VERSION "created by canmatrix"

NS_ :

BS_:

BU_:

BO_ 2358902526 JLCM: 8 Vector__XXX
 SG_ Joystick3Lamp10Cmd : 58|2@1+ (1,0) [0|3] "" Vector__XXX
 SG_ Joystick3Lamp9Cmd : 56|2@1+ (1,0) [0|3] "" Vector__XXX
 SG_ Joystick3Lamp8Cmd : 54|2@1+ (1,0) [0|3] "" Vector__XXX
 SG_ Joystick3Lamp7Cmd : 52|2@1+ (1,0) [0|3] "" Vector__XXX
 SG_ Joystick3Lamp6Cmd : 50|2@1+ (1,0) [0|3] "" Vector__XXX
 SG_ Joystick3Lamp5Cmd : 48|2@1+ (1,0) [0|3] "" Vector__XXX
 SG_ Joystick3Lamp4Cmd : 46|2@1+ (1,0) [0|3] "" Vector__XXX
 SG_ Joystick3Lamp3Cmd : 44|2@1+ (1,0) [0|3] "" Vector__XXX
 SG_ Joystick3Lamp2Cmd : 42|2@1+ (1,0) [0|3] "" Vector__XXX
 SG_ Joystick3Lamp1Cmd : 40|2@1+ (1,0) [0|3] "" Vector__XXX
 SG_ Joystick2Lamp10Cmd : 38|2@1+ (1,0) [0|3] "" Vector__XXX
 SG_ Joystick2Lamp9Cmd : 36|2@1+ (1,0) [0|3] "" Vector__XXX
 SG_ Joystick2Lamp8Cmd : 34|2@1+ (1,0) [0|3] "" Vector__XXX
 SG_ Joystick2Lamp7Cmd : 32|2@1+ (1,0) [0|3] "" Vector__XXX
 SG_ Joystick2Lamp6Cmd : 30|2@1+ (1,0) [0|3] "" Vector__XXX
 SG_ Joystick2Lamp5Cmd : 28|2@1+ (1,0) [0|3] "" Vector__XXX
 SG_ Joystick2Lamp4Cmd : 26|2@1+ (1,0) [0|3] "" Vector__XXX
 SG_ Joystick2Lamp3Cmd : 24|2@1+ (1,0) [0|3] "" Vector__XXX
 SG_ Joystick2Lamp2Cmd : 22|2@1+ (1,0) [0|3] "" Vector__XXX
 SG_ Joystick2Lamp1Cmd : 20|2@1+ (1,0) [0|3] "" Vector__XXX
 SG_ Joystick1Lamp10Cmd : 18|2@1+ (1,0) [0|3] "" Vector__XXX
 SG_ Joystick1Lamp9Cmd : 16|2@1+ (1,0) [0|3] "" Vector__XXX
 SG_ Joystick1Lamp8Cmd : 14|2@1+ (1,0) [0|3] "" Vector__XXX
 SG_ Joystick1Lamp7Cmd : 12|2@1+ (1,0) [0|3] "" Vector__XXX
 SG_ Joystick1Lamp6Cmd : 10|2@1+ (1,0) [0|3] "" Vector__XXX
 SG_ Joystick1Lamp5Cmd : 8|2@1+ (1,0) [0|3] "" Vector__XXX
 SG_ Joystick1Lamp4Cmd : 6|2@1+ (1,0) [0|3] "" Vector__XXX
 SG_ Joystick1Lamp3Cmd : 4|2@1+ (1,0) [0|3] "" Vector__XXX
 SG_ Joystick1Lamp2Cmd : 2|2@1+ (1,0) [0|3] "" Vector__XXX
 SG_ Joystick1Lamp1Cmd : 0|2@1+ (1,0) [0|3] "" Vector__XXX

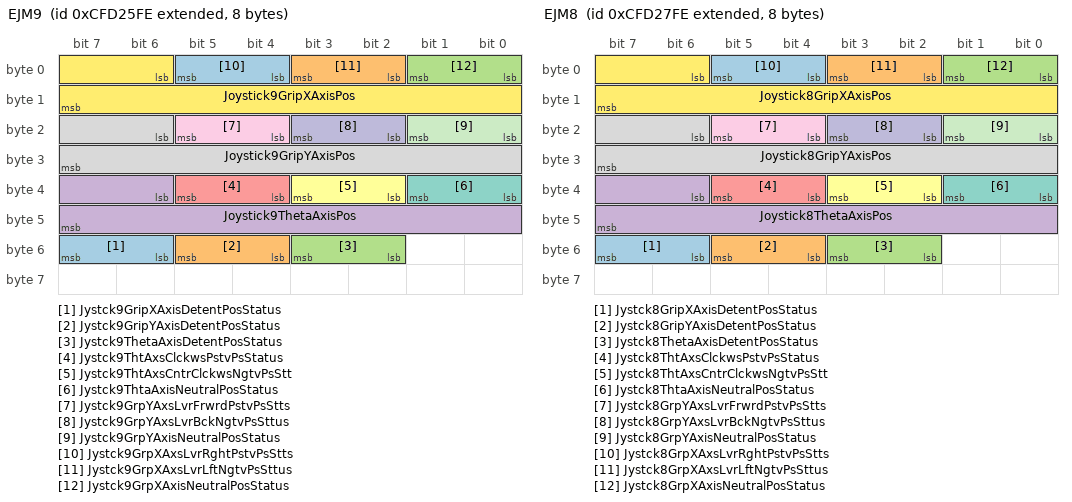
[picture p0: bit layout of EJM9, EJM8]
BO_ 2365400574 EJM9: 8 Vector__XXX
 SG_ Jystck9GripXAxisDetentPosStatus : 54|2@1+ (1,0) [0|3] "" Vector__XXX
 SG_ Jystck9GripYAxisDetentPosStatus : 52|2@1+ (1,0) [0|3] "" Vector__XXX
 SG_ Jystck9ThetaAxisDetentPosStatus : 50|2@1+ (1,0) [0|3] "" Vector__XXX
 SG_ Joystick9ThetaAxisPos : 38|10@1+ (0.1,0) [0|102] "%" Vector__XXX
 SG_ Jystck9ThtAxsClckwsPstvPsStatus : 36|2@1+ (1,0) [0|3] "" Vector__XXX
 SG_ Jystck9ThtAxsCntrClckwsNgtvPsStt : 34|2@1+ (1,0) [0|3] "" Vector__XXX
 SG_ Jystck9ThtaAxisNeutralPosStatus : 32|2@1+ (1,0) [0|3] "" Vector__XXX
 SG_ Joystick9GripYAxisPos : 22|10@1+ (0.1,0) [0|102] "%" Vector__XXX
 SG_ Jystck9GrpYAxsLvrFrwrdPstvPsStts : 20|2@1+ (1,0) [0|3] "" Vector__XXX
 SG_ Jystck9GrpYAxsLvrBckNgtvPsSttus : 18|2@1+ (1,0) [0|3] "" Vector__XXX
 SG_ Jystck9GrpYAxisNeutralPosStatus : 16|2@1+ (1,0) [0|3] "" Vector__XXX
 SG_ Joystick9GripXAxisPos : 6|10@1+ (0.1,0) [0|102] "%" Vector__XXX
 SG_ Jystck9GrpXAxsLvrRghtPstvPsStts : 4|2@1+ (1,0) [0|3] "" Vector__XXX
 SG_ Jystck9GrpXAxsLvrLftNgtvPsSttus : 2|2@1+ (1,0) [0|3] "" Vector__XXX
 SG_ Jystck9GrpXAxisNeutralPosStatus : 0|2@1+ (1,0) [0|3] "" Vector__XXX

BO_ 2365401086 EJM8: 8 Vector__XXX
 SG_ Jystck8GripXAxisDetentPosStatus : 54|2@1+ (1,0) [0|3] "" Vector__XXX
 SG_ Jystck8GripYAxisDetentPosStatus : 52|2@1+ (1,0) [0|3] "" Vector__XXX
 SG_ Jystck8ThetaAxisDetentPosStatus : 50|2@1+ (1,0) [0|3] "" Vector__XXX
 SG_ Joystick8ThetaAxisPos : 38|10@1+ (0.1,0) [0|102] "%" Vector__XXX
 SG_ Jystck8ThtAxsClckwsPstvPsStatus : 36|2@1+ (1,0) [0|3] "" Vector__XXX
 SG_ Jystck8ThtAxsCntrClckwsNgtvPsStt : 34|2@1+ (1,0) [0|3] "" Vector__XXX
 SG_ Jystck8ThtaAxisNeutralPosStatus : 32|2@1+ (1,0) [0|3] "" Vector__XXX
 SG_ Joystick8GripYAxisPos : 22|10@1+ (0.1,0) [0|102] "%" Vector__XXX
 SG_ Jystck8GrpYAxsLvrFrwrdPstvPsStts : 20|2@1+ (1,0) [0|3] "" Vector__XXX
 SG_ Jystck8GrpYAxsLvrBckNgtvPsSttus : 18|2@1+ (1,0) [0|3] "" Vector__XXX
 SG_ Jystck8GrpYAxisNeutralPosStatus : 16|2@1+ (1,0) [0|3] "" Vector__XXX
 SG_ Joystick8GripXAxisPos : 6|10@1+ (0.1,0) [0|102] "%" Vector__XXX
 SG_ Jystck8GrpXAxsLvrRghtPstvPsStts : 4|2@1+ (1,0) [0|3] "" Vector__XXX
 SG_ Jystck8GrpXAxsLvrLftNgtvPsSttus : 2|2@1+ (1,0) [0|3] "" Vector__XXX
 SG_ Jystck8GrpXAxisNeutralPosStatus : 0|2@1+ (1,0) [0|3] "" Vector__XXX

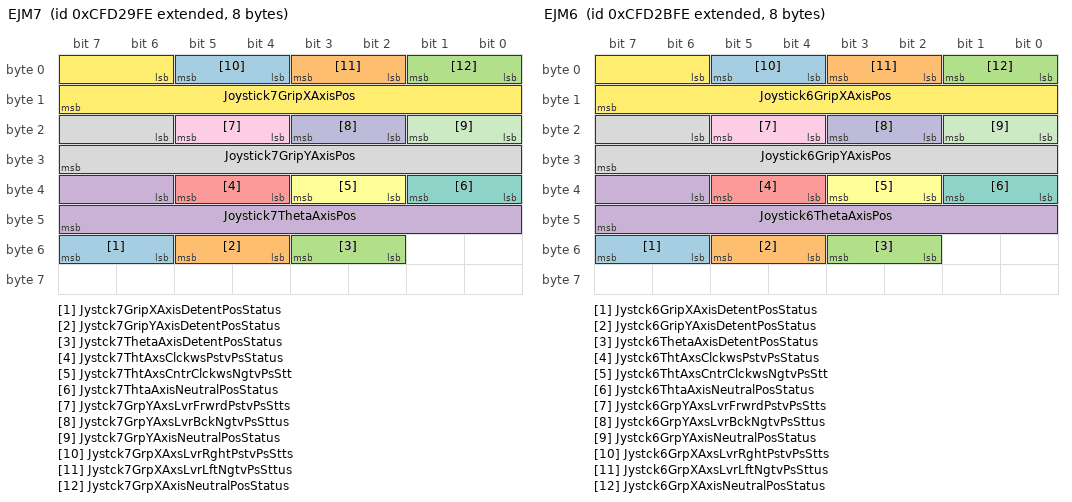
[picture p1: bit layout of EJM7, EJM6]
BO_ 2365401598 EJM7: 8 Vector__XXX
 SG_ Jystck7GripXAxisDetentPosStatus : 54|2@1+ (1,0) [0|3] "" Vector__XXX
 SG_ Jystck7GripYAxisDetentPosStatus : 52|2@1+ (1,0) [0|3] "" Vector__XXX
 SG_ Jystck7ThetaAxisDetentPosStatus : 50|2@1+ (1,0) [0|3] "" Vector__XXX
 SG_ Joystick7ThetaAxisPos : 38|10@1+ (0.1,0) [0|102] "%" Vector__XXX
 SG_ Jystck7ThtAxsClckwsPstvPsStatus : 36|2@1+ (1,0) [0|3] "" Vector__XXX
 SG_ Jystck7ThtAxsCntrClckwsNgtvPsStt : 34|2@1+ (1,0) [0|3] "" Vector__XXX
 SG_ Jystck7ThtaAxisNeutralPosStatus : 32|2@1+ (1,0) [0|3] "" Vector__XXX
 SG_ Joystick7GripYAxisPos : 22|10@1+ (0.1,0) [0|102] "%" Vector__XXX
 SG_ Jystck7GrpYAxsLvrFrwrdPstvPsStts : 20|2@1+ (1,0) [0|3] "" Vector__XXX
 SG_ Jystck7GrpYAxsLvrBckNgtvPsSttus : 18|2@1+ (1,0) [0|3] "" Vector__XXX
 SG_ Jystck7GrpYAxisNeutralPosStatus : 16|2@1+ (1,0) [0|3] "" Vector__XXX
 SG_ Joystick7GripXAxisPos : 6|10@1+ (0.1,0) [0|102] "%" Vector__XXX
 SG_ Jystck7GrpXAxsLvrRghtPstvPsStts : 4|2@1+ (1,0) [0|3] "" Vector__XXX
 SG_ Jystck7GrpXAxsLvrLftNgtvPsSttus : 2|2@1+ (1,0) [0|3] "" Vector__XXX
 SG_ Jystck7GrpXAxisNeutralPosStatus : 0|2@1+ (1,0) [0|3] "" Vector__XXX

BO_ 2365402110 EJM6: 8 Vector__XXX
 SG_ Jystck6GripXAxisDetentPosStatus : 54|2@1+ (1,0) [0|3] "" Vector__XXX
 SG_ Jystck6GripYAxisDetentPosStatus : 52|2@1+ (1,0) [0|3] "" Vector__XXX
 SG_ Jystck6ThetaAxisDetentPosStatus : 50|2@1+ (1,0) [0|3] "" Vector__XXX
 SG_ Joystick6ThetaAxisPos : 38|10@1+ (0.1,0) [0|102] "%" Vector__XXX
 SG_ Jystck6ThtAxsClckwsPstvPsStatus : 36|2@1+ (1,0) [0|3] "" Vector__XXX
 SG_ Jystck6ThtAxsCntrClckwsNgtvPsStt : 34|2@1+ (1,0) [0|3] "" Vector__XXX
 SG_ Jystck6ThtaAxisNeutralPosStatus : 32|2@1+ (1,0) [0|3] "" Vector__XXX
 SG_ Joystick6GripYAxisPos : 22|10@1+ (0.1,0) [0|102] "%" Vector__XXX
 SG_ Jystck6GrpYAxsLvrFrwrdPstvPsStts : 20|2@1+ (1,0) [0|3] "" Vector__XXX
 SG_ Jystck6GrpYAxsLvrBckNgtvPsSttus : 18|2@1+ (1,0) [0|3] "" Vector__XXX
 SG_ Jystck6GrpYAxisNeutralPosStatus : 16|2@1+ (1,0) [0|3] "" Vector__XXX
 SG_ Joystick6GripXAxisPos : 6|10@1+ (0.1,0) [0|102] "%" Vector__XXX
 SG_ Jystck6GrpXAxsLvrRghtPstvPsStts : 4|2@1+ (1,0) [0|3] "" Vector__XXX
 SG_ Jystck6GrpXAxsLvrLftNgtvPsSttus : 2|2@1+ (1,0) [0|3] "" Vector__XXX
 SG_ Jystck6GrpXAxisNeutralPosStatus : 0|2@1+ (1,0) [0|3] "" Vector__XXX

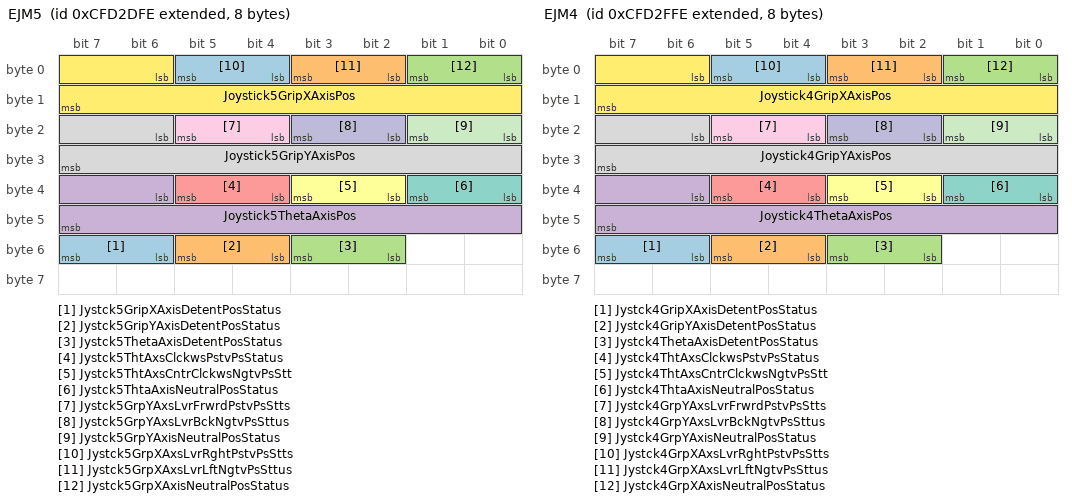
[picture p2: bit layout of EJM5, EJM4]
BO_ 2365402622 EJM5: 8 Vector__XXX
 SG_ Jystck5GripXAxisDetentPosStatus : 54|2@1+ (1,0) [0|3] "" Vector__XXX
 SG_ Jystck5GripYAxisDetentPosStatus : 52|2@1+ (1,0) [0|3] "" Vector__XXX
 SG_ Jystck5ThetaAxisDetentPosStatus : 50|2@1+ (1,0) [0|3] "" Vector__XXX
 SG_ Joystick5ThetaAxisPos : 38|10@1+ (0.1,0) [0|102] "%" Vector__XXX
 SG_ Jystck5ThtAxsClckwsPstvPsStatus : 36|2@1+ (1,0) [0|3] "" Vector__XXX
 SG_ Jystck5ThtAxsCntrClckwsNgtvPsStt : 34|2@1+ (1,0) [0|3] "" Vector__XXX
 SG_ Jystck5ThtaAxisNeutralPosStatus : 32|2@1+ (1,0) [0|3] "" Vector__XXX
 SG_ Joystick5GripYAxisPos : 22|10@1+ (0.1,0) [0|102] "%" Vector__XXX
 SG_ Jystck5GrpYAxsLvrFrwrdPstvPsStts : 20|2@1+ (1,0) [0|3] "" Vector__XXX
 SG_ Jystck5GrpYAxsLvrBckNgtvPsSttus : 18|2@1+ (1,0) [0|3] "" Vector__XXX
 SG_ Jystck5GrpYAxisNeutralPosStatus : 16|2@1+ (1,0) [0|3] "" Vector__XXX
 SG_ Joystick5GripXAxisPos : 6|10@1+ (0.1,0) [0|102] "%" Vector__XXX
 SG_ Jystck5GrpXAxsLvrRghtPstvPsStts : 4|2@1+ (1,0) [0|3] "" Vector__XXX
 SG_ Jystck5GrpXAxsLvrLftNgtvPsSttus : 2|2@1+ (1,0) [0|3] "" Vector__XXX
 SG_ Jystck5GrpXAxisNeutralPosStatus : 0|2@1+ (1,0) [0|3] "" Vector__XXX

BO_ 2365403134 EJM4: 8 Vector__XXX
 SG_ Jystck4GripXAxisDetentPosStatus : 54|2@1+ (1,0) [0|3] "" Vector__XXX
 SG_ Jystck4GripYAxisDetentPosStatus : 52|2@1+ (1,0) [0|3] "" Vector__XXX
 SG_ Jystck4ThetaAxisDetentPosStatus : 50|2@1+ (1,0) [0|3] "" Vector__XXX
 SG_ Joystick4ThetaAxisPos : 38|10@1+ (0.1,0) [0|102] "%" Vector__XXX
 SG_ Jystck4ThtAxsClckwsPstvPsStatus : 36|2@1+ (1,0) [0|3] "" Vector__XXX
 SG_ Jystck4ThtAxsCntrClckwsNgtvPsStt : 34|2@1+ (1,0) [0|3] "" Vector__XXX
 SG_ Jystck4ThtaAxisNeutralPosStatus : 32|2@1+ (1,0) [0|3] "" Vector__XXX
 SG_ Joystick4GripYAxisPos : 22|10@1+ (0.1,0) [0|102] "%" Vector__XXX
 SG_ Jystck4GrpYAxsLvrFrwrdPstvPsStts : 20|2@1+ (1,0) [0|3] "" Vector__XXX
 SG_ Jystck4GrpYAxsLvrBckNgtvPsSttus : 18|2@1+ (1,0) [0|3] "" Vector__XXX
 SG_ Jystck4GrpYAxisNeutralPosStatus : 16|2@1+ (1,0) [0|3] "" Vector__XXX
 SG_ Joystick4GripXAxisPos : 6|10@1+ (0.1,0) [0|102] "%" Vector__XXX
 SG_ Jystck4GrpXAxsLvrRghtPstvPsStts : 4|2@1+ (1,0) [0|3] "" Vector__XXX
 SG_ Jystck4GrpXAxsLvrLftNgtvPsSttus : 2|2@1+ (1,0) [0|3] "" Vector__XXX
 SG_ Jystck4GrpXAxisNeutralPosStatus : 0|2@1+ (1,0) [0|3] "" Vector__XXX

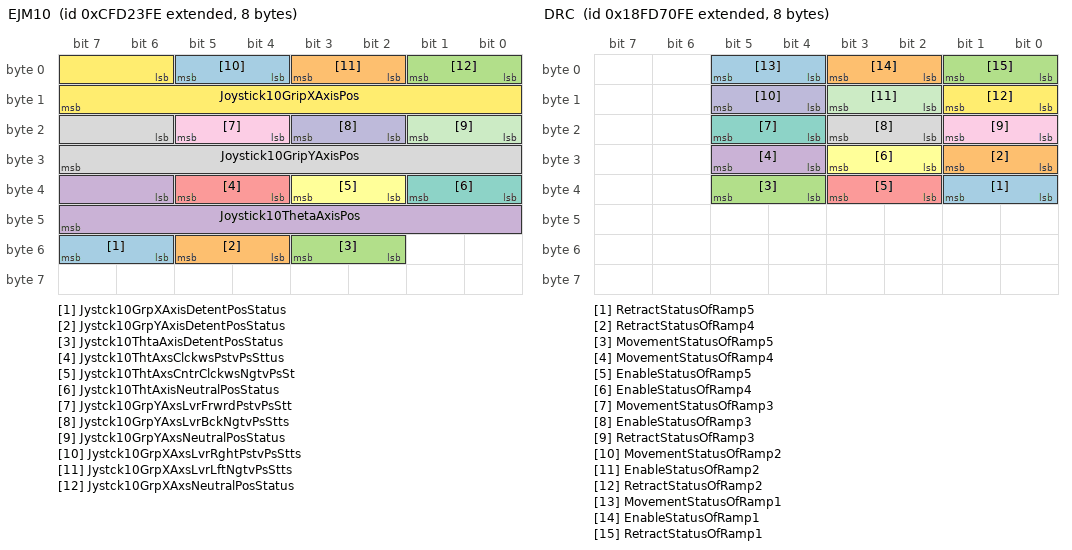
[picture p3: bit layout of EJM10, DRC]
BO_ 2365400062 EJM10: 8 Vector__XXX
 SG_ Jystck10GrpXAxisDetentPosStatus : 54|2@1+ (1,0) [0|3] "" Vector__XXX
 SG_ Jystck10GrpYAxisDetentPosStatus : 52|2@1+ (1,0) [0|3] "" Vector__XXX
 SG_ Jystck10ThtaAxisDetentPosStatus : 50|2@1+ (1,0) [0|3] "" Vector__XXX
 SG_ Joystick10ThetaAxisPos : 38|10@1+ (0.1,0) [0|102] "%" Vector__XXX
 SG_ Jystck10ThtAxsClckwsPstvPsSttus : 36|2@1+ (1,0) [0|3] "" Vector__XXX
 SG_ Jystck10ThtAxsCntrClckwsNgtvPsSt : 34|2@1+ (1,0) [0|3] "" Vector__XXX
 SG_ Jystck10ThtAxisNeutralPosStatus : 32|2@1+ (1,0) [0|3] "" Vector__XXX
 SG_ Joystick10GripYAxisPos : 22|10@1+ (0.1,0) [0|102] "%" Vector__XXX
 SG_ Jystck10GrpYAxsLvrFrwrdPstvPsStt : 20|2@1+ (1,0) [0|3] "" Vector__XXX
 SG_ Jystck10GrpYAxsLvrBckNgtvPsStts : 18|2@1+ (1,0) [0|3] "" Vector__XXX
 SG_ Jystck10GrpYAxsNeutralPosStatus : 16|2@1+ (1,0) [0|3] "" Vector__XXX
 SG_ Joystick10GripXAxisPos : 6|10@1+ (0.1,0) [0|102] "%" Vector__XXX
 SG_ Jystck10GrpXAxsLvrRghtPstvPsStts : 4|2@1+ (1,0) [0|3] "" Vector__XXX
 SG_ Jystck10GrpXAxsLvrLftNgtvPsStts : 2|2@1+ (1,0) [0|3] "" Vector__XXX
 SG_ Jystck10GrpXAxsNeutralPosStatus : 0|2@1+ (1,0) [0|3] "" Vector__XXX

BO_ 2566749438 DPFC1: 8 Vector__XXX
 SG_ DslPrtcltFltrActvRgnrtnFrcdStts : 53|3@1+ (1,0) [0|7] "" Vector__XXX
 SG_ ExhaustSystemHighTempLampCmd : 50|3@1+ (1,0) [0|7] "" Vector__XXX
 SG_ DslPrtcltFltrAtmtcActvRgnrtnIntt : 48|2@1+ (1,0) [0|3] "" Vector__XXX
 SG_ DslPrtcltFltrActvRgnrtnInhbtdDTV0 : 46|2@1+ (1,0) [0|3] "" Vector__XXX
 SG_ DslPrtcltFltrActvRgnrtnInhbtdDTE : 44|2@1+ (1,0) [0|3] "" Vector__XXX
 SG_ DslPrtcltFltrActvRgnrtnInhbtdDTP0 : 42|2@1+ (1,0) [0|3] "" Vector__XXX
 SG_ DslPrtcltFltrActvRgnrtnInhbtdDTT : 40|2@1+ (1,0) [0|3] "" Vector__XXX
 SG_ DslPrtcltFltrActvRgnrtnInhbtdDTS0 : 38|2@1+ (1,0) [0|3] "" Vector__XXX
 SG_ DslPrtcltFltrActvRgnrtnInhbtdDTS1 : 36|2@1+ (1,0) [0|3] "" Vector__XXX
 SG_ DslPrtcltFltrActvRgnrtnInhbtdDTL : 34|2@1+ (1,0) [0|3] "" Vector__XXX
 SG_ DslPrtcltFltrActvRgnrtnInhbtdDTP1 : 32|2@1+ (1,0) [0|3] "" Vector__XXX
 SG_ DslPrtcltFltrActvRgnrtnInhbtdDTV1 : 30|2@1+ (1,0) [0|3] "" Vector__XXX
 SG_ DslPrtcltFltrActvRgnrtnInhbtdDTO : 28|2@1+ (1,0) [0|3] "" Vector__XXX
 SG_ DslPrtcltFltrActvRgnrtnInhbtdDTA : 26|2@1+ (1,0) [0|3] "" Vector__XXX
 SG_ DslPrtcltFltrActvRgnrtnInhbtdDTP2 : 24|2@1+ (1,0) [0|3] "" Vector__XXX
 SG_ DslPrtcltFltrActvRgnrtnInhbtdDTS2 : 22|2@1+ (1,0) [0|3] "" Vector__XXX
 SG_ DslPrtcltFltrActvRgnrtnInhbtdDTC : 20|2@1+ (1,0) [0|3] "" Vector__XXX
 SG_ DslPrtcltFltrActvRgnrtnInhbtdDTI : 18|2@1+ (1,0) [0|3] "" Vector__XXX
 SG_ DslPrtcltFltrActvRgnrtnInhbtdStt : 16|2@1+ (1,0) [0|3] "" Vector__XXX
 SG_ DieselParticulateFilterStatus : 12|3@1+ (1,0) [0|7] "" Vector__XXX
 SG_ DslPrtcltFltrActvRgnrtionStatus : 10|2@1+ (1,0) [0|3] "" Vector__XXX
 SG_ DslPrtcltFltrPssvRgnrtionStatus : 8|2@1+ (1,0) [0|3] "" Vector__XXX
 SG_ DieselParticulateFilterLampCmd : 0|3@1+ (1,0) [0|7] "" Vector__XXX

BO_ 2561212158 DISP1: 8 Vector__XXX
 SG_ TextDisplayIndex : 16|8@1+ (1,0) [0|250] "" Vector__XXX
 SG_ TextDisplayInstructions : 0|4@1+ (1,0) [0|15] "" Vector__XXX

BO_ 2566746366 DRC: 8 Vector__XXX
 SG_ RetractStatusOfRamp5 : 32|2@1+ (1,0) [0|3] "" Vector__XXX
 SG_ RetractStatusOfRamp4 : 24|2@1+ (1,0) [0|3] "" Vector__XXX
 SG_ MovementStatusOfRamp5 : 36|2@1+ (1,0) [0|3] "" Vector__XXX
 SG_ MovementStatusOfRamp4 : 28|2@1+ (1,0) [0|3] "" Vector__XXX
 SG_ EnableStatusOfRamp5 : 34|2@1+ (1,0) [0|3] "" Vector__XXX
 SG_ EnableStatusOfRamp4 : 26|2@1+ (1,0) [0|3] "" Vector__XXX
 SG_ MovementStatusOfRamp3 : 20|2@1+ (1,0) [0|3] "" Vector__XXX
 SG_ EnableStatusOfRamp3 : 18|2@1+ (1,0) [0|3] "" Vector__XXX
 SG_ RetractStatusOfRamp3 : 16|2@1+ (1,0) [0|3] "" Vector__XXX
 SG_ MovementStatusOfRamp2 : 12|2@1+ (1,0) [0|3] "" Vector__XXX
 SG_ EnableStatusOfRamp2 : 10|2@1+ (1,0) [0|3] "" Vector__XXX
 SG_ RetractStatusOfRamp2 : 8|2@1+ (1,0) [0|3] "" Vector__XXX
 SG_ MovementStatusOfRamp1 : 4|2@1+ (1,0) [0|3] "" Vector__XXX
 SG_ EnableStatusOfRamp1 : 2|2@1+ (1,0) [0|3] "" Vector__XXX
 SG_ RetractStatusOfRamp1 : 0|2@1+ (1,0) [0|3] "" Vector__XXX

BO_ 2566750206 EC2: 8 Vector__XXX
 SG_ MaxCrankAttemptsPerStartAttempt : 0|8@1+ (1,0) [0|250] "" Vector__XXX

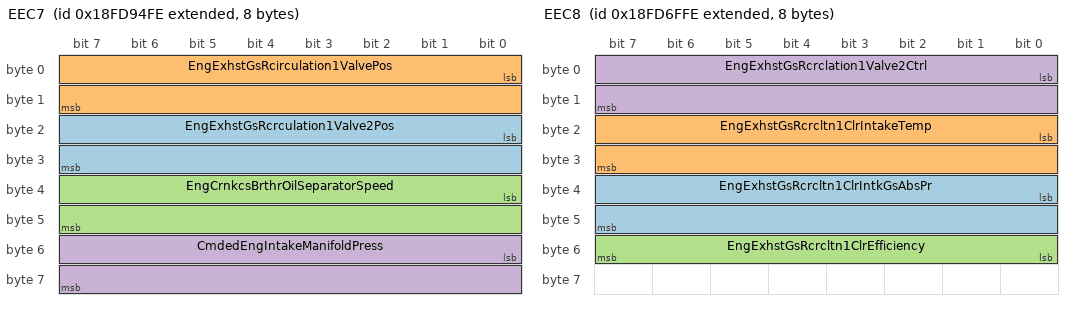
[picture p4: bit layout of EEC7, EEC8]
BO_ 2566755582 EEC7: 8 Vector__XXX
 SG_ EngExhstGsRcrculation1Valve2Pos : 16|16@1+ (0.0025,0) [0|160.6375] "%" Vector__XXX
 SG_ EngExhstGsRcirculation1ValvePos : 0|16@1+ (0.0025,0) [0|160.6375] "%" Vector__XXX
 SG_ EngCrnkcsBrthrOilSeparatorSpeed : 32|16@1+ (1,0) [0|64255] "rpm" Vector__XXX
 SG_ CmdedEngIntakeManifoldPress : 48|16@1+ (0.125,0) [0|8031.875] "kPa" Vector__XXX

BO_ 2566746110 EEC8: 8 Vector__XXX
 SG_ EngExhstGsRcrcltn1ClrIntkGsAbsPr : 32|16@1+ (0.5,0) [0|32127.5] "kPa" Vector__XXX
 SG_ EngExhstGsRcrcltn1ClrIntakeTemp : 16|16@1+ (0.03125,-273) [-273|1734.96875] "deg C" Vector__XXX
 SG_ EngExhstGsRcrcltn1ClrEfficiency : 48|8@1+ (0.4,0) [0|100] "%" Vector__XXX
 SG_ EngExhstGsRcrclation1Valve2Ctrl : 0|16@1+ (0.0025,0) [0|160.6375] "%" Vector__XXX

BO_ 2499641854 EGRBV: 8 Vector__XXX
 SG_ EGR1CoolerBypassActuatorPostion : 0|8@1+ (0.4,0) [0|100] "%" Vector__XXX

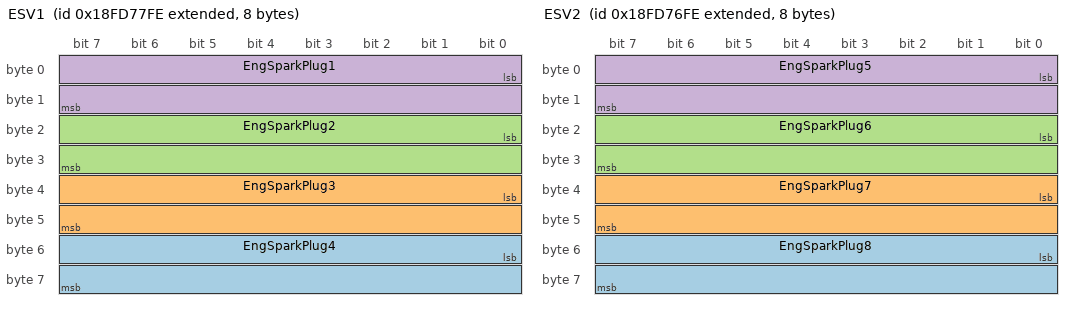
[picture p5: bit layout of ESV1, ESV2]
BO_ 2566748158 ESV1: 8 Vector__XXX
 SG_ EngSparkPlug4 : 48|16@1+ (1,0) [0|64255] "Volts" Vector__XXX
 SG_ EngSparkPlug3 : 32|16@1+ (1,0) [0|64255] "Volts" Vector__XXX
 SG_ EngSparkPlug2 : 16|16@1+ (1,0) [0|64255] "Volts" Vector__XXX
 SG_ EngSparkPlug1 : 0|16@1+ (1,0) [0|64255] "Volts" Vector__XXX

BO_ 2566747902 ESV2: 8 Vector__XXX
 SG_ EngSparkPlug8 : 48|16@1+ (1,0) [0|64255] "Volts" Vector__XXX
 SG_ EngSparkPlug7 : 32|16@1+ (1,0) [0|64255] "Volts" Vector__XXX
 SG_ EngSparkPlug6 : 16|16@1+ (1,0) [0|64255] "Volts" Vector__XXX
 SG_ EngSparkPlug5 : 0|16@1+ (1,0) [0|64255] "Volts" Vector__XXX

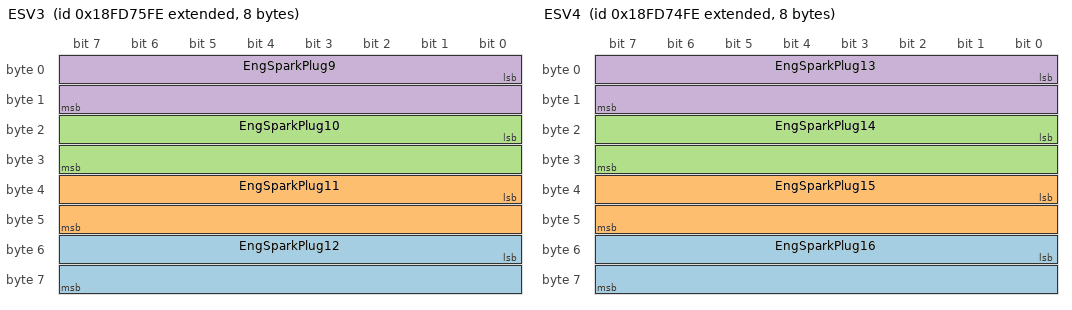
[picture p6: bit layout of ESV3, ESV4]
BO_ 2566747646 ESV3: 8 Vector__XXX
 SG_ EngSparkPlug12 : 48|16@1+ (1,0) [0|64255] "Volts" Vector__XXX
 SG_ EngSparkPlug11 : 32|16@1+ (1,0) [0|64255] "Volts" Vector__XXX
 SG_ EngSparkPlug10 : 16|16@1+ (1,0) [0|64255] "Volts" Vector__XXX
 SG_ EngSparkPlug9 : 0|16@1+ (1,0) [0|64255] "Volts" Vector__XXX

BO_ 2566747390 ESV4: 8 Vector__XXX
 SG_ EngSparkPlug16 : 48|16@1+ (1,0) [0|64255] "Volts" Vector__XXX
 SG_ EngSparkPlug15 : 32|16@1+ (1,0) [0|64255] "Volts" Vector__XXX
 SG_ EngSparkPlug14 : 16|16@1+ (1,0) [0|64255] "Volts" Vector__XXX
 SG_ EngSparkPlug13 : 0|16@1+ (1,0) [0|64255] "Volts" Vector__XXX

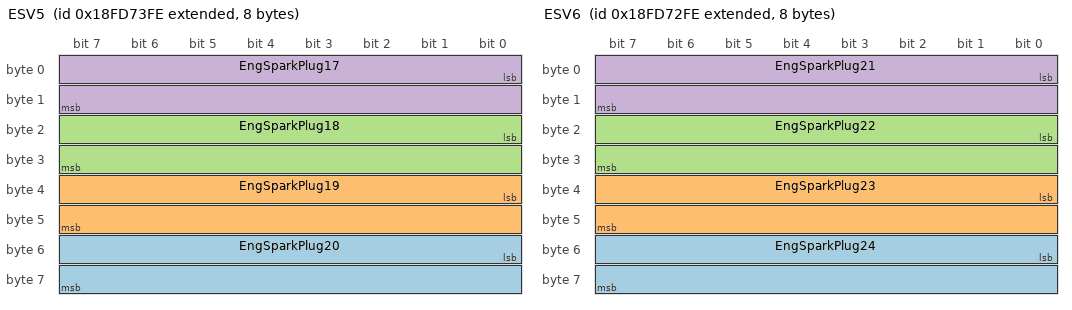
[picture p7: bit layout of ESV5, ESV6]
BO_ 2566747134 ESV5: 8 Vector__XXX
 SG_ EngSparkPlug20 : 48|16@1+ (1,0) [0|64255] "Volts" Vector__XXX
 SG_ EngSparkPlug19 : 32|16@1+ (1,0) [0|64255] "Volts" Vector__XXX
 SG_ EngSparkPlug18 : 16|16@1+ (1,0) [0|64255] "Volts" Vector__XXX
 SG_ EngSparkPlug17 : 0|16@1+ (1,0) [0|64255] "Volts" Vector__XXX

BO_ 2566746878 ESV6: 8 Vector__XXX
 SG_ EngSparkPlug24 : 48|16@1+ (1,0) [0|64255] "Volts" Vector__XXX
 SG_ EngSparkPlug23 : 32|16@1+ (1,0) [0|64255] "Volts" Vector__XXX
 SG_ EngSparkPlug22 : 16|16@1+ (1,0) [0|64255] "Volts" Vector__XXX
 SG_ EngSparkPlug21 : 0|16@1+ (1,0) [0|64255] "Volts" Vector__XXX

BO_ 2561277694 FLIC: 8 Vector__XXX
 SG_ LaneDepartureWarningEnableCmd : 0|2@1+ (1,0) [0|3] "" Vector__XXX

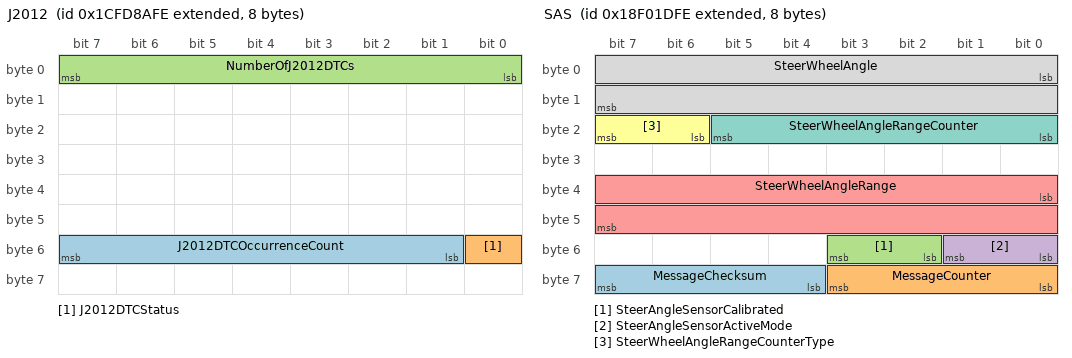
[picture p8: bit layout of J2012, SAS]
BO_ 2633861886 J2012: 8 Vector__XXX
 SG_ J2012DTCOccurrenceCount : 49|7@1+ (1,0) [0|127] "" Vector__XXX
 SG_ J2012DTCStatus : 48|1@1+ (1,0) [0|1] "" Vector__XXX
 SG_ NumberOfJ2012DTCs : 0|8@1+ (1,0) [0|250] "" Vector__XXX

BO_ 2565873150 SAS: 8 Vector__XXX
 SG_ MessageChecksum : 60|4@1+ (1,0) [0|15] "" Vector__XXX
 SG_ MessageCounter : 56|4@1+ (1,0) [0|15] "" Vector__XXX
 SG_ SteerAngleSensorCalibrated : 50|2@1+ (1,0) [0|3] "" Vector__XXX
 SG_ SteerAngleSensorActiveMode : 48|2@1+ (1,0) [0|3] "" Vector__XXX
 SG_ SteerWheelAngleRange : 32|16@1+ (0.0009765625,-31.374) [-31.374|31.374] "rad" Vector__XXX
 SG_ SteerWheelAngleRangeCounterType : 22|2@1+ (1,0) [0|3] "" Vector__XXX
 SG_ SteerWheelAngleRangeCounter : 16|6@1+ (1,-32) [-32|29] "ranges" Vector__XXX
 SG_ SteerWheelAngle : 0|16@1+ (0.0009765625,-31.374) [-31.374|31.374] "rad" Vector__XXX

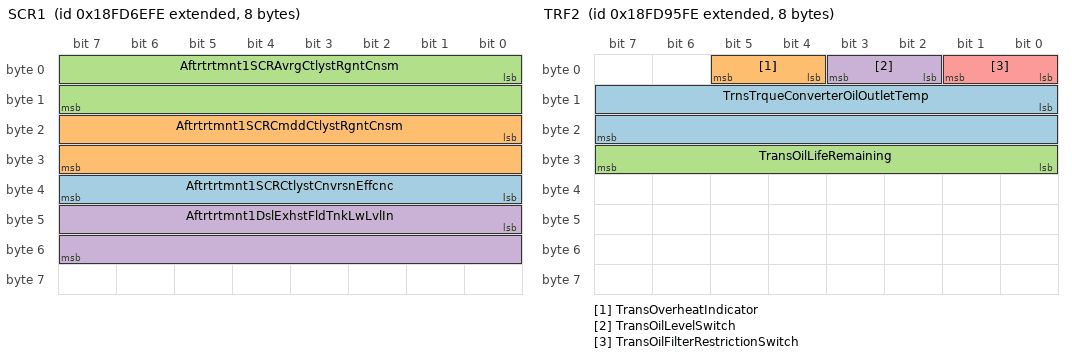
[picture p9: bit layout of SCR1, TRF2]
BO_ 2566745854 SCR1: 8 Vector__XXX
 SG_ Aftrtrtmnt1SCRCtlystCnvrsnEffcnc : 32|8@1+ (0.4,0) [0|100] "%" Vector__XXX
 SG_ Aftrtrtmnt1SCRCmddCtlystRgntCnsm : 16|16@1+ (0.05,0) [0|3212.75] "L/h" Vector__XXX
 SG_ Aftrtrtmnt1SCRAvrgCtlystRgntCnsm : 0|16@1+ (0.05,0) [0|3212.75] "L/h" Vector__XXX
 SG_ Aftrtrtmnt1DslExhstFldTnkLwLvlIn : 40|16@1+ (1,0) [0|64255] "km" Vector__XXX

BO_ 2566751230 TCI: 8 Vector__XXX
 SG_ TransferCaseStatus : 0|3@1+ (1,0) [0|7] "" Vector__XXX

BO_ 2566755838 TRF2: 8 Vector__XXX
 SG_ TrnsTrqueConverterOilOutletTemp : 8|16@1+ (0.03125,-273) [-273|1734.96875] "deg C" Vector__XXX
 SG_ TransOverheatIndicator : 4|2@1+ (1,0) [0|3] "" Vector__XXX
 SG_ TransOilLifeRemaining : 24|8@1+ (0.4,0) [0|100] "%" Vector__XXX
 SG_ TransOilLevelSwitch : 2|2@1+ (1,0) [0|3] "" Vector__XXX
 SG_ TransOilFilterRestrictionSwitch : 0|2@1+ (1,0) [0|3] "" Vector__XXX

BO_ 2566752766 VDS2: 8 Vector__XXX
 SG_ VehicleRoll : 0|16@1+ (0.0078125,-200) [-200|301.99] "deg" Vector__XXX

BO_ 2633938942 LF: 10 Vector__XXX
 SG_ TotalEngCruiseTime : 48|32@1+ (0.05,0) [0|210554060.75] "hr" Vector__XXX
 SG_ TotalDriveAverageLoadFactor : 40|8@1+ (0.4,0) [0|100] "%" Vector__XXX
 SG_ TripDriveAverageLoadFactor : 32|8@1+ (0.4,0) [0|100] "%" Vector__XXX
 SG_ TripAverageEngSpeed : 16|16@1+ (0.125,0) [0|8031.875] "rpm" Vector__XXX
 SG_ TripMaxEngSpeed : 0|16@1+ (0.125,0) [0|8031.875] "rpm" Vector__XXX

BO_ 2566799614 LD: 8 Vector__XXX
 SG_ ImplementRearWorkLight : 62|2@1+ (1,0) [0|3] "" Vector__XXX
 SG_ ImplementLeftForwardWorkLight : 60|2@1+ (1,0) [0|3] "" Vector__XXX
 SG_ ImplementRightForwardWorkLight : 58|2@1+ (1,0) [0|3] "" Vector__XXX
 SG_ ImplementLeftFacingWorkLight : 54|2@1+ (1,0) [0|3] "" Vector__XXX
 SG_ ImplementRightFacingWorkLight : 52|2@1+ (1,0) [0|3] "" Vector__XXX
 SG_ ImplementOEMOption1Light : 50|2@1+ (1,0) [0|3] "" Vector__XXX
 SG_ ImplementOEMOption2Light : 48|2@1+ (1,0) [0|3] "" Vector__XXX
 SG_ TrctrFrontHighMountedWorkLights : 46|2@1+ (1,0) [0|3] "" Vector__XXX
 SG_ TrctorFrontLowMountedWorkLights : 44|2@1+ (1,0) [0|3] "" Vector__XXX
 SG_ TrctorSideHighMountedWorkLights : 42|2@1+ (1,0) [0|3] "" Vector__XXX
 SG_ TractorSideLowMountedWorkLights : 40|2@1+ (1,0) [0|3] "" Vector__XXX
 SG_ TrctorRearHighMountedWorkLights : 38|2@1+ (1,0) [0|3] "" Vector__XXX
 SG_ TractorRearLowMountedWorkLights : 36|2@1+ (1,0) [0|3] "" Vector__XXX
 SG_ TrctrUndersideMountedWorkLights : 34|2@1+ (1,0) [0|3] "" Vector__XXX
 SG_ RearFogLights : 32|2@1+ (1,0) [0|3] "" Vector__XXX
 SG_ TractorMarkerLight : 30|2@1+ (1,0) [0|3] "" Vector__XXX
 SG_ ImplementMarkerLight : 28|2@1+ (1,0) [0|3] "" Vector__XXX
 SG_ TractorClearanceLight : 26|2@1+ (1,0) [0|3] "" Vector__XXX
 SG_ ImplementClearanceLight : 24|2@1+ (1,0) [0|3] "" Vector__XXX
 SG_ LeftStopLight : 22|2@1+ (1,0) [0|3] "" Vector__XXX
 SG_ RightStopLight : 20|2@1+ (1,0) [0|3] "" Vector__XXX
 SG_ CenterStopLight : 18|2@1+ (1,0) [0|3] "" Vector__XXX
 SG_ BackUpLightAndAlarmHorn : 16|2@1+ (1,0) [0|3] "" Vector__XXX
 SG_ LeftTurnSignalLights : 14|2@1+ (1,0) [0|3] "" Vector__XXX
 SG_ RightTurnSignalLights : 12|2@1+ (1,0) [0|3] "" Vector__XXX
 SG_ RotatingBeaconLight : 10|2@1+ (1,0) [0|3] "" Vector__XXX
 SG_ TractorFrontFogLights : 8|2@1+ (1,0) [0|3] "" Vector__XXX
 SG_ HighBeamHeadLightData : 6|2@1+ (1,0) [0|3] "" Vector__XXX
 SG_ LowBeamHeadLightData : 4|2@1+ (1,0) [0|3] "" Vector__XXX
 SG_ AltBeamHeadLightData : 2|2@1+ (1,0) [0|3] "" Vector__XXX
 SG_ RunningLight : 0|2@1+ (1,0) [0|3] "" Vector__XXX

BO_ 2365473278 LC: 8 Vector__XXX
 SG_ ImplementRearWorkLightCmd : 62|2@1+ (1,0) [0|3] "" Vector__XXX
 SG_ ImplmentLeftForwardWorkLightCmd : 60|2@1+ (1,0) [0|3] "" Vector__XXX
 SG_ ImplmntRightForwardWorkLightCmd : 58|2@1+ (1,0) [0|3] "" Vector__XXX
 SG_ LightingDataRqCmd : 56|2@1+ (1,0) [0|3] "" Vector__XXX
 SG_ ImplementLeftFacingWorkLightCmd : 54|2@1+ (1,0) [0|3] "" Vector__XXX
 SG_ ImplmentRightFacingWorkLightCmd : 52|2@1+ (1,0) [0|3] "" Vector__XXX
 SG_ ImplementOEMOption1LightCmd : 50|2@1+ (1,0) [0|3] "" Vector__XXX
 SG_ ImplementOEMOption2LightCmd : 48|2@1+ (1,0) [0|3] "" Vector__XXX
 SG_ TrctrFrntHghMuntedWorkLightsCmd : 46|2@1+ (1,0) [0|3] "" Vector__XXX
 SG_ TrctrFrntLwMountedWorkLightsCmd : 44|2@1+ (1,0) [0|3] "" Vector__XXX
 SG_ TrctrSdHighMountedWorkLightsCmd : 42|2@1+ (1,0) [0|3] "" Vector__XXX
 SG_ TrctrSdeLowMountedWorkLightsCmd : 40|2@1+ (1,0) [0|3] "" Vector__XXX
 SG_ TrctrRrHighMountedWorkLightsCmd : 38|2@1+ (1,0) [0|3] "" Vector__XXX
 SG_ TrctrRarLowMountedWorkLightsCmd : 36|2@1+ (1,0) [0|3] "" Vector__XXX
 SG_ TrctrUndrsdMountedWorkLightsCmd : 34|2@1+ (1,0) [0|3] "" Vector__XXX
 SG_ RearFogLightCmd : 32|2@1+ (1,0) [0|3] "" Vector__XXX
 SG_ TractorMarkerLightCmd : 30|2@1+ (1,0) [0|3] "" Vector__XXX
 SG_ ImplementMarkerLightCmd : 28|2@1+ (1,0) [0|3] "" Vector__XXX
 SG_ TractorClearanceLightCmd : 26|2@1+ (1,0) [0|3] "" Vector__XXX
 SG_ ImplementClearanceLightCmd : 24|2@1+ (1,0) [0|3] "" Vector__XXX
 SG_ LeftStopLightCmd : 22|2@1+ (1,0) [0|3] "" Vector__XXX
 SG_ RightStopLightCmd : 20|2@1+ (1,0) [0|3] "" Vector__XXX
 SG_ CenterStopLightCmd : 18|2@1+ (1,0) [0|3] "" Vector__XXX
 SG_ BackUpLightAndAlarmHornCmd : 16|2@1+ (1,0) [0|3] "" Vector__XXX
 SG_ LeftTurnSignalLightsCmd : 14|2@1+ (1,0) [0|3] "" Vector__XXX
 SG_ RightTurnSignalLightsCmd : 12|2@1+ (1,0) [0|3] "" Vector__XXX
 SG_ RotatingBeaconLightCmd : 10|2@1+ (1,0) [0|3] "" Vector__XXX
 SG_ TractorFrontFogLightsCmd : 8|2@1+ (1,0) [0|3] "" Vector__XXX
 SG_ HighBeamHeadLightCmd : 6|2@1+ (1,0) [0|3] "" Vector__XXX
 SG_ LowBeamHeadLightCmd : 4|2@1+ (1,0) [0|3] "" Vector__XXX
 SG_ AltBeamHeadLightCmd : 2|2@1+ (1,0) [0|3] "" Vector__XXX
 SG_ RunningLightCmd : 0|2@1+ (1,0) [0|3] "" Vector__XXX

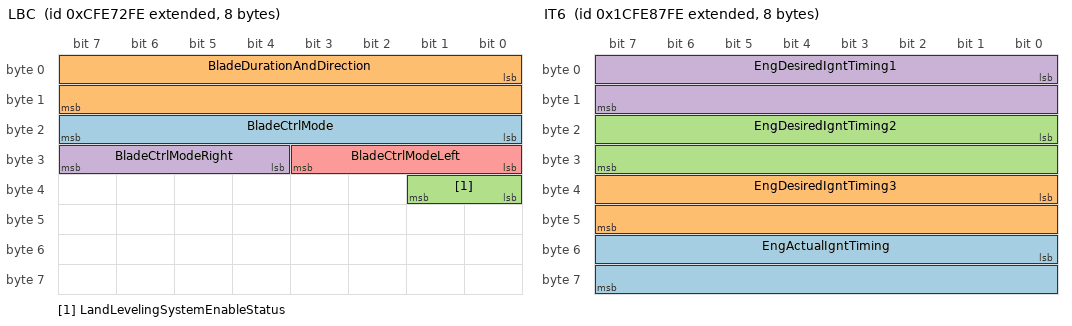
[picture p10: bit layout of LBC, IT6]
BO_ 2365485822 LBC: 8 Vector__XXX
 SG_ BladeCtrlMode : 16|8@1+ (1,0) [0|255] "" Vector__XXX
 SG_ BladeDurationAndDirection : 0|16@1+ (0.1,-3276.8) [-3276.8|3148.7] "sec" Vector__XXX
 SG_ LandLevelingSystemEnableStatus : 32|2@1+ (1,0) [0|3] "" Vector__XXX
 SG_ BladeCtrlModeRight : 28|4@1+ (1,0) [0|15] "" Vector__XXX
 SG_ BladeCtrlModeLeft : 24|4@1+ (1,0) [0|15] "" Vector__XXX

BO_ 2633926654 IT6: 8 Vector__XXX
 SG_ EngActualIgntTiming : 48|16@1+ (0.0078125,-200) [-200|301.99] "deg" Vector__XXX
 SG_ EngDesiredIgntTiming3 : 32|16@1+ (0.0078125,-200) [-200|301.99] "deg" Vector__XXX
 SG_ EngDesiredIgntTiming2 : 16|16@1+ (0.0078125,-200) [-200|301.99] "deg" Vector__XXX
 SG_ EngDesiredIgntTiming1 : 0|16@1+ (0.0078125,-200) [-200|301.99] "deg" Vector__XXX

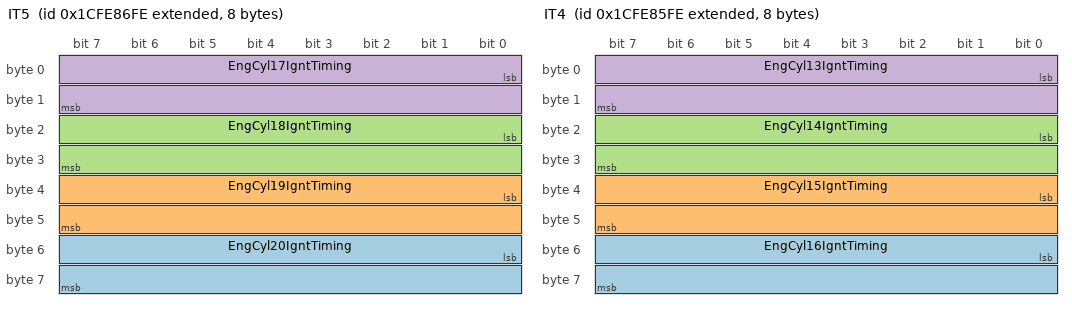
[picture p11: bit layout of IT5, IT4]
BO_ 2633926398 IT5: 8 Vector__XXX
 SG_ EngCyl20IgntTiming : 48|16@1+ (0.0078125,-200) [-200|301.99] "deg" Vector__XXX
 SG_ EngCyl19IgntTiming : 32|16@1+ (0.0078125,-200) [-200|301.99] "deg" Vector__XXX
 SG_ EngCyl18IgntTiming : 16|16@1+ (0.0078125,-200) [-200|301.99] "deg" Vector__XXX
 SG_ EngCyl17IgntTiming : 0|16@1+ (0.0078125,-200) [-200|301.99] "deg" Vector__XXX

BO_ 2633926142 IT4: 8 Vector__XXX
 SG_ EngCyl16IgntTiming : 48|16@1+ (0.0078125,-200) [-200|301.99] "deg" Vector__XXX
 SG_ EngCyl15IgntTiming : 32|16@1+ (0.0078125,-200) [-200|301.99] "deg" Vector__XXX
 SG_ EngCyl14IgntTiming : 16|16@1+ (0.0078125,-200) [-200|301.99] "deg" Vector__XXX
 SG_ EngCyl13IgntTiming : 0|16@1+ (0.0078125,-200) [-200|301.99] "deg" Vector__XXX

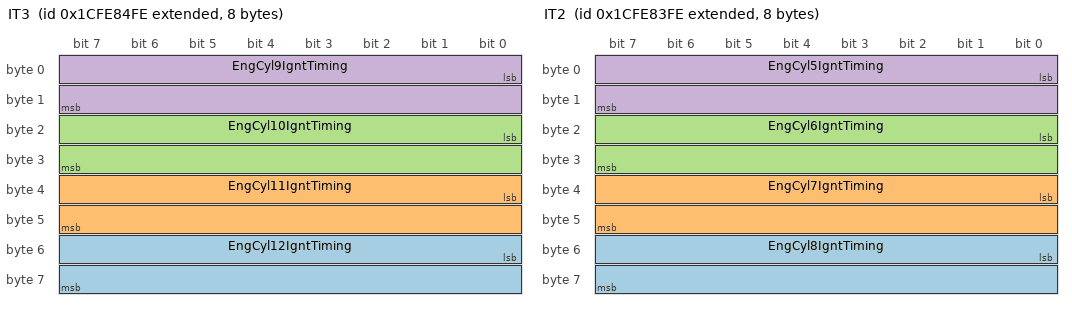
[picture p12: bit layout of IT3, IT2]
BO_ 2633925886 IT3: 8 Vector__XXX
 SG_ EngCyl12IgntTiming : 48|16@1+ (0.0078125,-200) [-200|301.99] "deg" Vector__XXX
 SG_ EngCyl11IgntTiming : 32|16@1+ (0.0078125,-200) [-200|301.99] "deg" Vector__XXX
 SG_ EngCyl10IgntTiming : 16|16@1+ (0.0078125,-200) [-200|301.99] "deg" Vector__XXX
 SG_ EngCyl9IgntTiming : 0|16@1+ (0.0078125,-200) [-200|301.99] "deg" Vector__XXX

BO_ 2633925630 IT2: 8 Vector__XXX
 SG_ EngCyl8IgntTiming : 48|16@1+ (0.0078125,-200) [-200|301.99] "deg" Vector__XXX
 SG_ EngCyl7IgntTiming : 32|16@1+ (0.0078125,-200) [-200|301.99] "deg" Vector__XXX
 SG_ EngCyl6IgntTiming : 16|16@1+ (0.0078125,-200) [-200|301.99] "deg" Vector__XXX
 SG_ EngCyl5IgntTiming : 0|16@1+ (0.0078125,-200) [-200|301.99] "deg" Vector__XXX

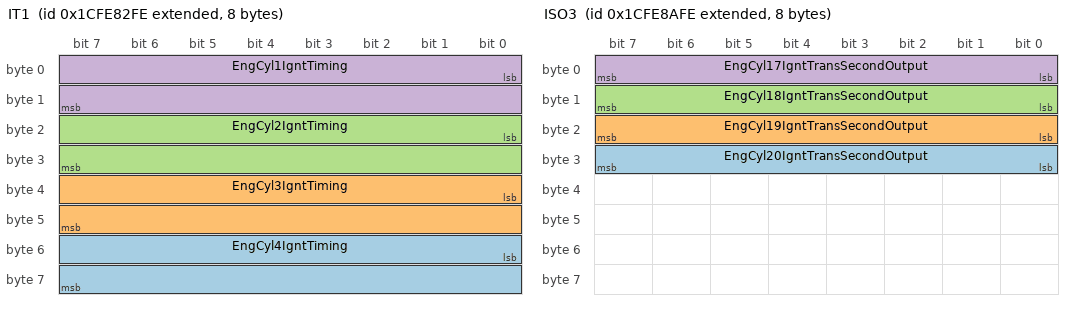
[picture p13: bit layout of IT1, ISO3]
BO_ 2633925374 IT1: 8 Vector__XXX
 SG_ EngCyl4IgntTiming : 48|16@1+ (0.0078125,-200) [-200|301.99] "deg" Vector__XXX
 SG_ EngCyl3IgntTiming : 32|16@1+ (0.0078125,-200) [-200|301.99] "deg" Vector__XXX
 SG_ EngCyl2IgntTiming : 16|16@1+ (0.0078125,-200) [-200|301.99] "deg" Vector__XXX
 SG_ EngCyl1IgntTiming : 0|16@1+ (0.0078125,-200) [-200|301.99] "deg" Vector__XXX

BO_ 2633927422 ISO3: 8 Vector__XXX
 SG_ EngCyl20IgntTransSecondOutput : 24|8@1+ (1,-125) [-125|125] "%" Vector__XXX
 SG_ EngCyl19IgntTransSecondOutput : 16|8@1+ (1,-125) [-125|125] "%" Vector__XXX
 SG_ EngCyl18IgntTransSecondOutput : 8|8@1+ (1,-125) [-125|125] "%" Vector__XXX
 SG_ EngCyl17IgntTransSecondOutput : 0|8@1+ (1,-125) [-125|125] "%" Vector__XXX

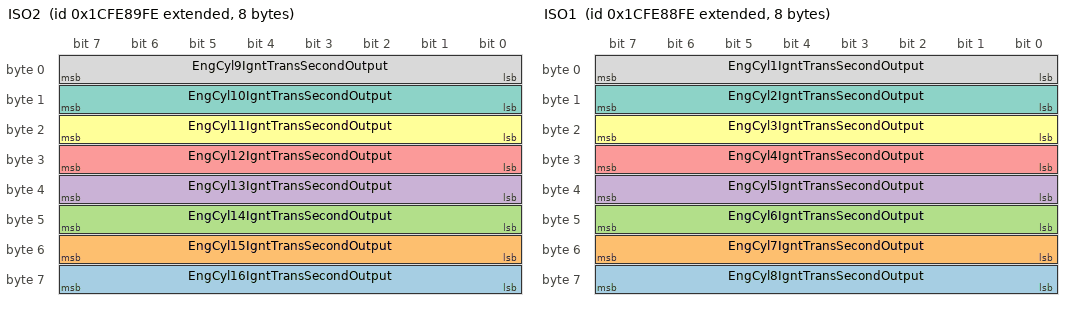
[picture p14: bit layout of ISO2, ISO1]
BO_ 2633927166 ISO2: 8 Vector__XXX
 SG_ EngCyl16IgntTransSecondOutput : 56|8@1+ (1,-125) [-125|125] "%" Vector__XXX
 SG_ EngCyl15IgntTransSecondOutput : 48|8@1+ (1,-125) [-125|125] "%" Vector__XXX
 SG_ EngCyl14IgntTransSecondOutput : 40|8@1+ (1,-125) [-125|125] "%" Vector__XXX
 SG_ EngCyl13IgntTransSecondOutput : 32|8@1+ (1,-125) [-125|125] "%" Vector__XXX
 SG_ EngCyl12IgntTransSecondOutput : 24|8@1+ (1,-125) [-125|125] "%" Vector__XXX
 SG_ EngCyl11IgntTransSecondOutput : 16|8@1+ (1,-125) [-125|125] "%" Vector__XXX
 SG_ EngCyl10IgntTransSecondOutput : 8|8@1+ (1,-125) [-125|125] "%" Vector__XXX
 SG_ EngCyl9IgntTransSecondOutput : 0|8@1+ (1,-125) [-125|125] "%" Vector__XXX

BO_ 2633926910 ISO1: 8 Vector__XXX
 SG_ EngCyl8IgntTransSecondOutput : 56|8@1+ (1,-125) [-125|125] "%" Vector__XXX
 SG_ EngCyl7IgntTransSecondOutput : 48|8@1+ (1,-125) [-125|125] "%" Vector__XXX
 SG_ EngCyl6IgntTransSecondOutput : 40|8@1+ (1,-125) [-125|125] "%" Vector__XXX
 SG_ EngCyl5IgntTransSecondOutput : 32|8@1+ (1,-125) [-125|125] "%" Vector__XXX
 SG_ EngCyl4IgntTransSecondOutput : 24|8@1+ (1,-125) [-125|125] "%" Vector__XXX
 SG_ EngCyl3IgntTransSecondOutput : 16|8@1+ (1,-125) [-125|125] "%" Vector__XXX
 SG_ EngCyl2IgntTransSecondOutput : 8|8@1+ (1,-125) [-125|125] "%" Vector__XXX
 SG_ EngCyl1IgntTransSecondOutput : 0|8@1+ (1,-125) [-125|125] "%" Vector__XXX

BO_ 2566768894 ISCS: 8 Vector__XXX
 SG_ EngOprtrPrmryIntrmdtSpdSlctStte : 0|4@1+ (1,0) [0|15] "" Vector__XXX

BO_ 2566769406 ISC: 8 Vector__XXX
 SG_ EngOprtrPrmryIntrmdtSpeedSelect : 0|4@1+ (1,0) [0|15] "" Vector__XXX

BO_ 2566839550 IO: 8 Vector__XXX
 SG_ EngTotalIdleHours : 32|32@1+ (0.05,0) [0|210554060.75] "hr" Vector__XXX
 SG_ EngTotalIdleFuelUsed : 0|32@1+ (0.5,0) [0|2105540607.5] "L" Vector__XXX

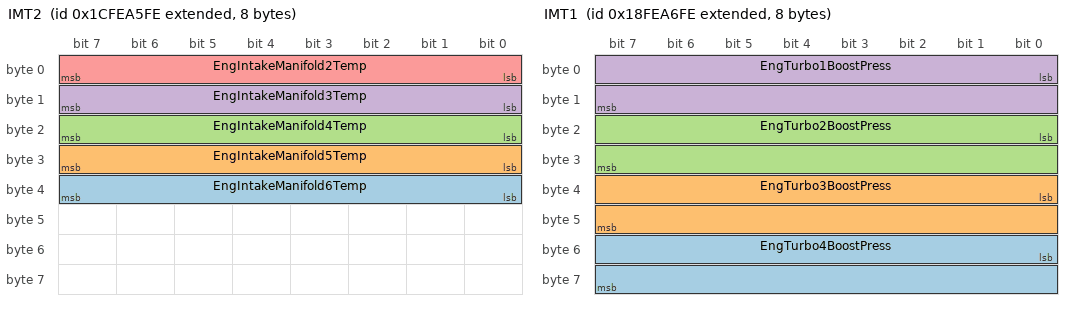
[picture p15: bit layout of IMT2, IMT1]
BO_ 2633934334 IMT2: 8 Vector__XXX
 SG_ EngIntakeManifold6Temp : 32|8@1+ (1,-40) [-40|210] "deg C" Vector__XXX
 SG_ EngIntakeManifold5Temp : 24|8@1+ (1,-40) [-40|210] "deg C" Vector__XXX
 SG_ EngIntakeManifold4Temp : 16|8@1+ (1,-40) [-40|210] "deg C" Vector__XXX
 SG_ EngIntakeManifold3Temp : 8|8@1+ (1,-40) [-40|210] "deg C" Vector__XXX
 SG_ EngIntakeManifold2Temp : 0|8@1+ (1,-40) [-40|210] "deg C" Vector__XXX

BO_ 2566825726 IMT1: 8 Vector__XXX
 SG_ EngTurbo4BoostPress : 48|16@1+ (0.125,0) [0|8031.875] "kPa" Vector__XXX
 SG_ EngTurbo3BoostPress : 32|16@1+ (0.125,0) [0|8031.875] "kPa" Vector__XXX
 SG_ EngTurbo2BoostPress : 16|16@1+ (0.125,0) [0|8031.875] "kPa" Vector__XXX
 SG_ EngTurbo1BoostPress : 0|16@1+ (0.125,0) [0|8031.875] "kPa" Vector__XXX

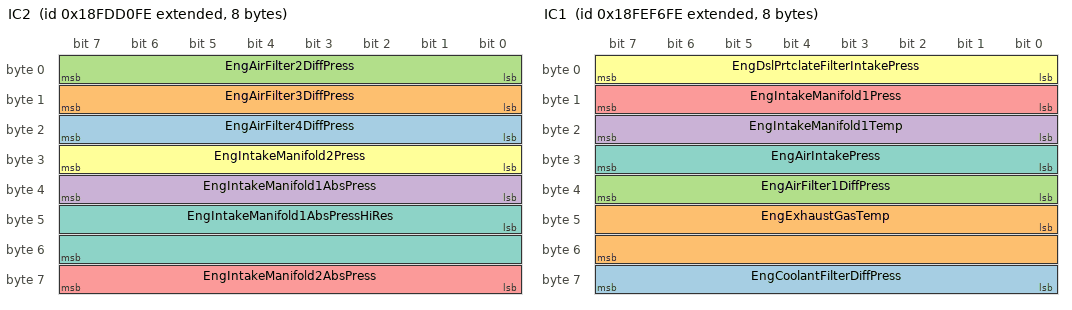
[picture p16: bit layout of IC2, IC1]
BO_ 2566770942 IC2: 8 Vector__XXX
 SG_ EngAirFilter4DiffPress : 16|8@1+ (0.05,0) [0|12.5] "kPa" Vector__XXX
 SG_ EngAirFilter3DiffPress : 8|8@1+ (0.05,0) [0|12.5] "kPa" Vector__XXX
 SG_ EngAirFilter2DiffPress : 0|8@1+ (0.05,0) [0|12.5] "kPa" Vector__XXX
 SG_ EngIntakeManifold1AbsPress : 32|8@1+ (0.1,0) [0|25.5] "kPa" Vector__XXX
 SG_ EngIntakeManifold2AbsPress : 56|8@1+ (2,0) [0|500] "kPa" Vector__XXX
 SG_ EngIntakeManifold2Press : 24|8@1+ (2,0) [0|500] "kPa" Vector__XXX
 SG_ EngIntakeManifold1AbsPressHiRes : 40|16@1+ (0.1,0) [0|6425.5] "kPa" Vector__XXX

BO_ 2566846206 IC1: 8 Vector__XXX
 SG_ EngCoolantFilterDiffPress : 56|8@1+ (0.5,0) [0|125] "kPa" Vector__XXX
 SG_ EngExhaustGasTemp : 40|16@1+ (0.03125,-273) [-273|1734.96875] "deg C" Vector__XXX
 SG_ EngAirFilter1DiffPress : 32|8@1+ (0.05,0) [0|12.5] "kPa" Vector__XXX
 SG_ EngIntakeManifold1Temp : 16|8@1+ (1,-40) [-40|210] "deg C" Vector__XXX
 SG_ EngIntakeManifold1Press : 8|8@1+ (2,0) [0|500] "kPa" Vector__XXX
 SG_ EngDslPrtclateFilterIntakePress : 0|8@1+ (0.5,0) [0|125] "kPa" Vector__XXX
 SG_ EngAirIntakePress : 24|8@1+ (2,0) [0|500] "kPa" Vector__XXX

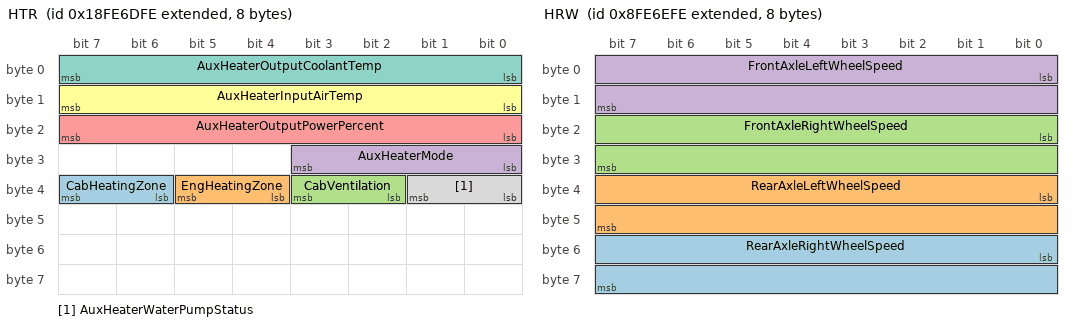
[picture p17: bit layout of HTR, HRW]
BO_ 2566811134 HTR: 8 Vector__XXX
 SG_ CabHeatingZone : 38|2@1+ (1,0) [0|3] "" Vector__XXX
 SG_ EngHeatingZone : 36|2@1+ (1,0) [0|3] "" Vector__XXX
 SG_ CabVentilation : 34|2@1+ (1,0) [0|3] "" Vector__XXX
 SG_ AuxHeaterMode : 24|4@1+ (1,0) [0|15] "" Vector__XXX
 SG_ AuxHeaterOutputPowerPercent : 16|8@1+ (0.4,0) [0|100] "%" Vector__XXX
 SG_ AuxHeaterInputAirTemp : 8|8@1+ (1,-40) [-40|210] "deg C" Vector__XXX
 SG_ AuxHeaterOutputCoolantTemp : 0|8@1+ (1,-40) [-40|210] "deg C" Vector__XXX
 SG_ AuxHeaterWaterPumpStatus : 32|2@1+ (1,0) [0|3] "" Vector__XXX

BO_ 2298375934 HRW: 8 Vector__XXX
 SG_ RearAxleRightWheelSpeed : 48|16@1+ (0.00390625,0) [0|250.996] "km/h" Vector__XXX
 SG_ RearAxleLeftWheelSpeed : 32|16@1+ (0.00390625,0) [0|250.996] "km/h" Vector__XXX
 SG_ FrontAxleRightWheelSpeed : 16|16@1+ (0.00390625,0) [0|250.996] "km/h" Vector__XXX
 SG_ FrontAxleLeftWheelSpeed : 0|16@1+ (0.00390625,0) [0|250.996] "km/h" Vector__XXX

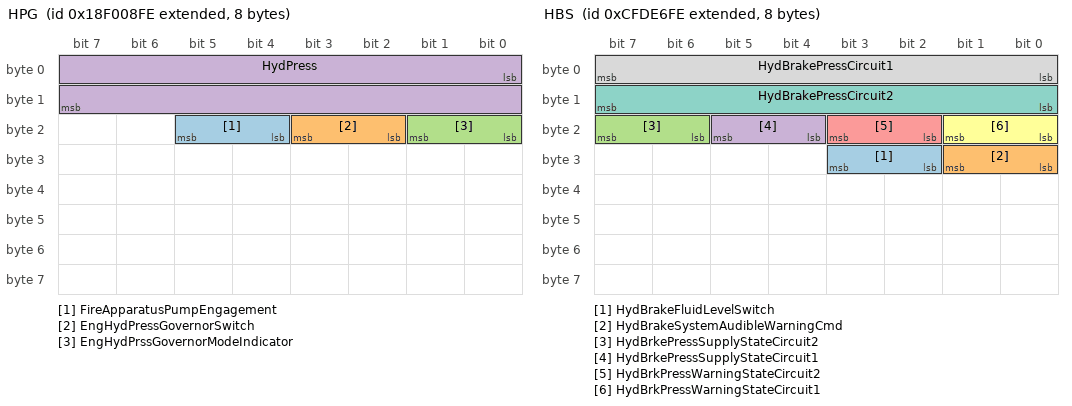
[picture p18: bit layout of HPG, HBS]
BO_ 2565867774 HPG: 8 Vector__XXX
 SG_ FireApparatusPumpEngagement : 20|2@1+ (1,0) [0|3] "" Vector__XXX
 SG_ EngHydPressGovernorSwitch : 18|2@1+ (1,0) [0|3] "" Vector__XXX
 SG_ EngHydPrssGovernorModeIndicator : 16|2@1+ (1,0) [0|3] "" Vector__XXX
 SG_ HydPress : 0|16@1+ (2,0) [0|128510] "kPa" Vector__XXX

BO_ 2566841854 HOURS: 8 Vector__XXX
 SG_ EngTotalRevolutions : 32|32@1+ (1000,0) [0|4211081215000] "r" Vector__XXX
 SG_ EngTotalHoursOfOperation : 0|32@1+ (0.05,0) [0|210554060.75] "hr" Vector__XXX

BO_ 2365449982 HBS: 8 Vector__XXX
 SG_ HydBrakeFluidLevelSwitch : 26|2@1+ (1,0) [0|3] "" Vector__XXX
 SG_ HydBrakeSystemAudibleWarningCmd : 24|2@1+ (1,0) [0|3] "" Vector__XXX
 SG_ HydBrkePressSupplyStateCircuit2 : 22|2@1+ (1,0) [0|3] "" Vector__XXX
 SG_ HydBrkePressSupplyStateCircuit1 : 20|2@1+ (1,0) [0|3] "" Vector__XXX
 SG_ HydBrkPressWarningStateCircuit2 : 18|2@1+ (1,0) [0|3] "" Vector__XXX
 SG_ HydBrkPressWarningStateCircuit1 : 16|2@1+ (1,0) [0|3] "" Vector__XXX
 SG_ HydBrakePressCircuit2 : 8|8@1+ (100,0) [0|25] "MPa" Vector__XXX
 SG_ HydBrakePressCircuit1 : 0|8@1+ (100,0) [0|25] "MPa" Vector__XXX

BO_ 2633939198 GTFI: 22 Vector__XXX
 SG_ TripDriveFuelEconomy : 160|16@1+ (0.001953125,0) [0|125.5] "km/kg" Vector__XXX
 SG_ TrpPTOGovernorNonmovingFuelUsed : 64|32@1+ (0.5,0) [0|2105540607.5] "kg" Vector__XXX
 SG_ TripVehicleIdleFuelUsed : 96|32@1+ (0.5,0) [0|2105540607.5] "kg" Vector__XXX
 SG_ TripCruiseFuelUsed : 128|32@1+ (0.5,0) [0|2105540607.5] "kg" Vector__XXX
 SG_ TripDriveFuelUsed : 0|32@1+ (0.5,0) [0|2105540607.5] "kg" Vector__XXX
 SG_ TripPTOGovernorMovingFuelUsed : 32|32@1+ (0.5,0) [0|2105540607.5] "kg" Vector__XXX

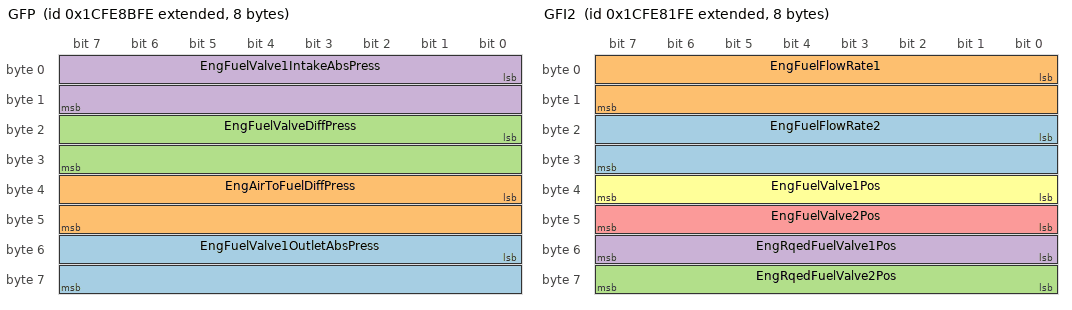
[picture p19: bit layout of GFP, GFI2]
BO_ 2633927678 GFP: 8 Vector__XXX
 SG_ EngFuelValve1OutletAbsPress : 48|16@1+ (0.1,0) [0|6425.5] "kPa" Vector__XXX
 SG_ EngAirToFuelDiffPress : 32|16@1+ (0.1,0) [0|6425.5] "kPa" Vector__XXX
 SG_ EngFuelValveDiffPress : 16|16@1+ (0.1,0) [0|6425.5] "kPa" Vector__XXX
 SG_ EngFuelValve1IntakeAbsPress : 0|16@1+ (0.1,0) [0|6425.5] "kPa" Vector__XXX

BO_ 2633925118 GFI2: 8 Vector__XXX
 SG_ EngFuelFlowRate2 : 16|16@1+ (0.1,0) [0|6425.5] "(m*m*m)/h" Vector__XXX
 SG_ EngFuelFlowRate1 : 0|16@1+ (0.1,0) [0|6425.5] "(m*m*m)/h" Vector__XXX
 SG_ EngRqedFuelValve2Pos : 56|8@1+ (0.4,0) [0|100] "%" Vector__XXX
 SG_ EngRqedFuelValve1Pos : 48|8@1+ (0.4,0) [0|100] "%" Vector__XXX
 SG_ EngFuelValve2Pos : 40|8@1+ (0.4,0) [0|100] "%" Vector__XXX
 SG_ EngFuelValve1Pos : 32|8@1+ (0.4,0) [0|100] "%" Vector__XXX

BO_ 2633937662 GFI1: 8 Vector__XXX
 SG_ TotalEngPTOGovernorFuelUsed : 0|32@1+ (0.5,0) [0|2105540607.5] "kg" Vector__XXX
 SG_ TripAverageFuelRate : 32|16@1+ (0.05,0) [0|3212.75] "kg/h" Vector__XXX
 SG_ EngFuelSpecificGravity : 48|16@1+ (0.0001,0) [0|6.4255] "" Vector__XXX

BO_ 2566804990 GFD: 8 Vector__XXX
 SG_ SpecificHeatRatio : 0|16@1+ (0.001,0) [0|64.255] "" Vector__XXX

CM_ BO_ 2358902526  "Joystick Lamp Command Message";
CM_ BO_ 2365400574  "Extended Joystick Message 9";
CM_ BO_ 2365401086  "Extended Joystick Message 8";
CM_ BO_ 2365401598  "Extended Joystick Message 7";
CM_ BO_ 2365402110  "Extended Joystick Message 6";
CM_ BO_ 2365402622  "Extended Joystick Message 5";
CM_ BO_ 2365403134  "Extended Joystick Message 4";
CM_ BO_ 2365400062  "Extended Joystick Message 10";
CM_ BO_ 2566749438  "Diesel Particulate Filter Control 1";
CM_ BO_ 2561212158  "Text Display";
CM_ BO_ 2566746366  "Door ramp control";
CM_ BO_ 2566750206  "Engine Configuration 2";
CM_ BO_ 2566755582  "Electronic Engine Controller 7";
CM_ BO_ 2566746110  "Electronic Engine Controller 8";
CM_ BO_ 2499641854  "EGR Cooler Bypass";
CM_ BO_ 2566748158  "Engine Spark Voltage 1";
CM_ BO_ 2566747902  "Engine Spark Voltage 2";
CM_ BO_ 2566747646  "Engine Spark Voltage 3";
CM_ BO_ 2566747390  "Engine Spark Voltage 4";
CM_ BO_ 2566747134  "Engine Spark Voltage 5";
CM_ BO_ 2566746878  "Engine Spark Voltage 6";
CM_ BO_ 2561277694  "Forward Lane Image Command";
CM_ BO_ 2633861886  "SAE J2012 DTC Display";
CM_ BO_ 2565873150  "Steering Angle Sensor Information";
CM_ BO_ 2566745854  "Aftertreatment 1 SCR Service Information";
CM_ BO_ 2566751230  "Transfer Case Information";
CM_ BO_ 2566755838  "Transmission Fluids 2";
CM_ BO_ 2566752766  "Vehicle Direction/Speed 2";
CM_ BO_ 2633938942  "Engine Speed/Load Factor Information";
CM_ BO_ 2566799614  "Lighting Data";
CM_ BO_ 2365473278  "Lighting Command";
CM_ BO_ 2365485822  "Laser Leveling System Blade Control";
CM_ BO_ 2633926654  "Ignition Timing 6";
CM_ BO_ 2633926398  "Ignition Timing 5";
CM_ BO_ 2633926142  "Ignition Timing 4";
CM_ BO_ 2633925886  "Ignition Timing 3";
CM_ BO_ 2633925630  "Ignition Timing 2";
CM_ BO_ 2633925374  "Ignition Timing 1";
CM_ BO_ 2633927422  "Ignition Transformer Secondary Output 3";
CM_ BO_ 2633927166  "Ignition Transformer Secondary Output 2";
CM_ BO_ 2633926910  "Ignition Transformer Secondary Output 1";
CM_ BO_ 2566768894  "Operator Primary Intermediate Speed Control state";
CM_ BO_ 2566769406  "Intermediate Speed Control";
CM_ BO_ 2566839550  "Idle Operation";
CM_ BO_ 2633934334  "Intake Manifold Information 2";
CM_ BO_ 2566825726  "Intake Manifold Information 1";
CM_ BO_ 2566770942  "Intake/Exhaust Conditions 2";
CM_ BO_ 2566846206  "Intake/Exhaust Conditions 1";
CM_ BO_ 2566811134  "Heater Information";
CM_ BO_ 2298375934  "High Resolution Wheel Speed";
CM_ BO_ 2565867774  "Hydraulic Pressure Governor Info";
CM_ BO_ 2566841854  "Engine Hours, Revolutions";
CM_ BO_ 2365449982  "Hydraulic Braking System";
CM_ BO_ 2633939198  "Trip Fuel Information (Gaseous)";
CM_ BO_ 2633927678  "Gaseous Fuel Pressure";
CM_ BO_ 2633925118  "Fuel Information 2 (Gaseous)";
CM_ BO_ 2633937662  "Fuel Information 1 (Gaseous)";
CM_ BO_ 2566804990  "Gaseous Fuel Properties";

CM_ SG_ 2358902526 Joystick3Lamp10Cmd "Tells joystick 3 to switch on/off/blinking lamp 10.";
CM_ SG_ 2358902526 Joystick3Lamp9Cmd "Tells joystick 3 to switch on/off/blinking lamp 9.";
CM_ SG_ 2358902526 Joystick3Lamp8Cmd "Tells joystick 3 to switch on/off/blinking lamp 8.";
CM_ SG_ 2358902526 Joystick3Lamp7Cmd "Tells joystick 3 to switch on/off/blinking lamp 7.";
CM_ SG_ 2358902526 Joystick3Lamp6Cmd "Tells joystick 3 to switch on/off/blinking lamp 6.";
CM_ SG_ 2358902526 Joystick3Lamp5Cmd "Tells joystick 3 to switch on/off/blinking lamp 5.";
CM_ SG_ 2358902526 Joystick3Lamp4Cmd "Tells joystick 3 to switch on/off/blinking lamp 4.";
CM_ SG_ 2358902526 Joystick3Lamp3Cmd "Tells joystick 3 to switch on/off/blinking lamp 3.";
CM_ SG_ 2358902526 Joystick3Lamp2Cmd "Tells joystick 3 to switch on/off/blinking lamp 2.";
CM_ SG_ 2358902526 Joystick3Lamp1Cmd "Tells joystick 3 to switch on/off/blinking lamp 1.";
CM_ SG_ 2358902526 Joystick2Lamp10Cmd "Tells joystick 2 to switch on/off/blinking lamp 10.";
CM_ SG_ 2358902526 Joystick2Lamp9Cmd "Tells joystick 2 to switch on/off/blinking lamp 9.";
CM_ SG_ 2358902526 Joystick2Lamp8Cmd "Tells joystick 2 to switch on/off/blinking lamp 8.";
CM_ SG_ 2358902526 Joystick2Lamp7Cmd "Tells joystick 2 to switch on/off/blinking lamp 7.";
CM_ SG_ 2358902526 Joystick2Lamp6Cmd "Tells joystick 2 to switch on/off/blinking lamp 6.";
CM_ SG_ 2358902526 Joystick2Lamp5Cmd "Tells joystick 2 to switch on/off/blinking lamp 5.";
CM_ SG_ 2358902526 Joystick2Lamp4Cmd "Tells joystick 2 to switch on/off/blinking lamp 4.";
CM_ SG_ 2358902526 Joystick2Lamp3Cmd "Tells joystick 2 to switch on/off/blinking lamp 3.";
CM_ SG_ 2358902526 Joystick2Lamp2Cmd "Tells joystick 2 to switch on/off/blinking lamp 2.";
CM_ SG_ 2358902526 Joystick2Lamp1Cmd "Tells joystick 2 to switch on/off/blinking lamp 1.";
CM_ SG_ 2358902526 Joystick1Lamp10Cmd "Tells joystick 1 to switch on/off/blinking lamp 10.";
CM_ SG_ 2358902526 Joystick1Lamp9Cmd "Tells joystick 1 to switch on/off/blinking lamp 9.";
CM_ SG_ 2358902526 Joystick1Lamp8Cmd "Tells joystick 1 to switch on/off/blinking lamp 8.";
CM_ SG_ 2358902526 Joystick1Lamp7Cmd "Tells joystick 1 to switch on/off/blinking lamp 7.";
CM_ SG_ 2358902526 Joystick1Lamp6Cmd "Tells joystick 1 to switch on/off/blinking lamp 6.";
CM_ SG_ 2358902526 Joystick1Lamp5Cmd "Tells joystick 1 to switch on/off/blinking lamp 5.";
CM_ SG_ 2358902526 Joystick1Lamp4Cmd "Tells joystick 1 to switch on/off/blinking lamp 4.";
CM_ SG_ 2358902526 Joystick1Lamp3Cmd "Tells joystick 1 to switch on/off/blinking lamp 3.";
CM_ SG_ 2358902526 Joystick1Lamp2Cmd "Tells joystick 1 to switch on/off/blinking lamp 2.";
CM_ SG_ 2358902526 Joystick1Lamp1Cmd "Tells joystick 1 to switch on/off/blinking lamp 1.";
CM_ SG_ 2365400574 Jystck9GripXAxisDetentPosStatus "Reports when the current joystick grip position is in the detent position for that axis of travel.";
CM_ SG_ 2365400574 Jystck9GripYAxisDetentPosStatus "Reports when the current joystick grip position is in the detent position for that axis of travel.";
CM_ SG_ 2365400574 Jystck9ThetaAxisDetentPosStatus "Reports when the current joystick position is in the detent position for that axis of travel.";
CM_ SG_ 2365400574 Joystick9ThetaAxisPos "The position of the joystick in the relative motion of travel from the neutral position.";
CM_ SG_ 2365400574 Jystck9ThtAxsClckwsPstvPsStatus "Reports when the current joystick position is on the positive travel side (forward, right, clockwise, up) relative to the";
CM_ SG_ 2365400574 Jystck9ThtAxsCntrClckwsNgtvPsStt "Reports when the current joystick position is on the negative travel side (back, left, counterclockwise, down) relative to the";
CM_ SG_ 2365400574 Jystck9ThtaAxisNeutralPosStatus "Reports when the current joystick position is in the neutral position for that axis of travel.";
CM_ SG_ 2365400574 Joystick9GripYAxisPos "The position of the joystick grip in the relative motion of travel from the neutral position.";
CM_ SG_ 2365400574 Jystck9GrpYAxsLvrFrwrdPstvPsStts "Reports when the current joystick grip position is on the positive travel side (forward, right, clockwise, up) relative to the";
CM_ SG_ 2365400574 Jystck9GrpYAxsLvrBckNgtvPsSttus "Reports when the current joystick grip position is on the negative travel side (back, left, counterclockwise, down) relative";
CM_ SG_ 2365400574 Jystck9GrpYAxisNeutralPosStatus "Reports when the current joystick grip position is in the neutral position for that axis of travel.";
CM_ SG_ 2365400574 Joystick9GripXAxisPos "The position of the joystick grip in the relative motion of travel from the neutral position.";
CM_ SG_ 2365400574 Jystck9GrpXAxsLvrRghtPstvPsStts "Reports when the current joystick grip position is on the positive travel side (forward, right, clockwise, up) relative to the";
CM_ SG_ 2365400574 Jystck9GrpXAxsLvrLftNgtvPsSttus "Reports when the current joystick grip position is on the negative travel side (back, left, counterclockwise, down) relative";
CM_ SG_ 2365400574 Jystck9GrpXAxisNeutralPosStatus "Reports when the current joystick grip position is in the neutral position for that axis of travel.";
CM_ SG_ 2365401086 Jystck8GripXAxisDetentPosStatus "Reports when the current joystick grip position is in the detent position for that axis of travel.";
CM_ SG_ 2365401086 Jystck8GripYAxisDetentPosStatus "Reports when the current joystick grip position is in the detent position for that axis of travel.";
CM_ SG_ 2365401086 Jystck8ThetaAxisDetentPosStatus "Reports when the current joystick position is in the detent position for that axis of travel.";
CM_ SG_ 2365401086 Joystick8ThetaAxisPos "The position of the joystick in the relative motion of travel from the neutral position.";
CM_ SG_ 2365401086 Jystck8ThtAxsClckwsPstvPsStatus "Reports when the current joystick position is on the positive travel side (forward, right, clockwise, up) relative to the";
CM_ SG_ 2365401086 Jystck8ThtAxsCntrClckwsNgtvPsStt "Reports when the current joystick position is on the negative travel side (back, left, counterclockwise, down) relative to the";
CM_ SG_ 2365401086 Jystck8ThtaAxisNeutralPosStatus "Reports when the current joystick position is in the neutral position for that axis of travel.";
CM_ SG_ 2365401086 Joystick8GripYAxisPos "The position of the joystick grip in the relative motion of travel from the neutral position.";
CM_ SG_ 2365401086 Jystck8GrpYAxsLvrFrwrdPstvPsStts "Reports when the current joystick grip position is on the positive travel side (forward, right, clockwise, up) relative to the";
CM_ SG_ 2365401086 Jystck8GrpYAxsLvrBckNgtvPsSttus "Reports when the current joystick grip position is on the negative travel side (back, left, counterclockwise, down) relative";
CM_ SG_ 2365401086 Jystck8GrpYAxisNeutralPosStatus "Reports when the current joystick grip position is in the neutral position for that axis of travel.";
CM_ SG_ 2365401086 Joystick8GripXAxisPos "The position of the joystick grip in the relative motion of travel from the neutral position.";
CM_ SG_ 2365401086 Jystck8GrpXAxsLvrRghtPstvPsStts "Reports when the current joystick grip position is on the positive travel side (forward, right, clockwise, up) relative to the";
CM_ SG_ 2365401086 Jystck8GrpXAxsLvrLftNgtvPsSttus "Reports when the current joystick grip position is on the negative travel side (back, left, counterclockwise, down) relative";
CM_ SG_ 2365401086 Jystck8GrpXAxisNeutralPosStatus "Reports when the current joystick grip position is in the neutral position for that axis of travel.";
CM_ SG_ 2365401598 Jystck7GripXAxisDetentPosStatus "Reports when the current joystick grip position is in the detent position for that axis of travel.";
CM_ SG_ 2365401598 Jystck7GripYAxisDetentPosStatus "Reports when the current joystick grip position is in the detent position for that axis of travel.";
CM_ SG_ 2365401598 Jystck7ThetaAxisDetentPosStatus "Reports when the current joystick position is in the detent position for that axis of travel.";
CM_ SG_ 2365401598 Joystick7ThetaAxisPos "The position of the joystick in the relative motion of travel from the neutral position.";
CM_ SG_ 2365401598 Jystck7ThtAxsClckwsPstvPsStatus "Reports when the current joystick position is on the positive travel side (forward, right, clockwise, up) relative to the";
CM_ SG_ 2365401598 Jystck7ThtAxsCntrClckwsNgtvPsStt "Reports when the current joystick position is on the negative travel side (back, left, counterclockwise, down) relative to the";
CM_ SG_ 2365401598 Jystck7ThtaAxisNeutralPosStatus "Reports when the current joystick position is in the neutral position for that axis of travel.";
CM_ SG_ 2365401598 Joystick7GripYAxisPos "The position of the joystick grip in the relative motion of travel from the neutral position.";
CM_ SG_ 2365401598 Jystck7GrpYAxsLvrFrwrdPstvPsStts "Reports when the current joystick grip position is on the positive travel side (forward, right, clockwise, up) relative to the";
CM_ SG_ 2365401598 Jystck7GrpYAxsLvrBckNgtvPsSttus "Reports when the current joystick grip position is on the negative travel side (back, left, counterclockwise, down) relative";
CM_ SG_ 2365401598 Jystck7GrpYAxisNeutralPosStatus "Reports when the current joystick grip position is in the neutral position for that axis of travel.";
CM_ SG_ 2365401598 Joystick7GripXAxisPos "The position of the joystick grip in the relative motion of travel from the neutral position.";
CM_ SG_ 2365401598 Jystck7GrpXAxsLvrRghtPstvPsStts "Reports when the current joystick grip position is on the positive travel side (forward, right, clockwise, up) relative to the";
CM_ SG_ 2365401598 Jystck7GrpXAxsLvrLftNgtvPsSttus "Reports when the current joystick grip position is on the negative travel side (back, left, counterclockwise, down) relative";
CM_ SG_ 2365401598 Jystck7GrpXAxisNeutralPosStatus "Reports when the current joystick grip position is in the neutral position for that axis of travel.";
CM_ SG_ 2365402110 Jystck6GripXAxisDetentPosStatus "Reports when the current joystick grip position is in the detent position for that axis of travel.";
CM_ SG_ 2365402110 Jystck6GripYAxisDetentPosStatus "Reports when the current joystick grip position is in the detent position for that axis of travel.";
CM_ SG_ 2365402110 Jystck6ThetaAxisDetentPosStatus "Reports when the current joystick position is in the detent position for that axis of travel.";
CM_ SG_ 2365402110 Joystick6ThetaAxisPos "The position of the joystick in the relative motion of travel from the neutral position.";
CM_ SG_ 2365402110 Jystck6ThtAxsClckwsPstvPsStatus "Reports when the current joystick position is on the positive travel side (forward, right, clockwise, up) relative to the";
CM_ SG_ 2365402110 Jystck6ThtAxsCntrClckwsNgtvPsStt "Reports when the current joystick position is on the negative travel side (back, left, counterclockwise, down) relative to the";
CM_ SG_ 2365402110 Jystck6ThtaAxisNeutralPosStatus "Reports when the current joystick position is in the neutral position for that axis of travel.";
CM_ SG_ 2365402110 Joystick6GripYAxisPos "The position of the joystick grip in the relative motion of travel from the neutral position.";
CM_ SG_ 2365402110 Jystck6GrpYAxsLvrFrwrdPstvPsStts "Reports when the current joystick grip position is on the positive travel side (forward, right, clockwise, up) relative to the";
CM_ SG_ 2365402110 Jystck6GrpYAxsLvrBckNgtvPsSttus "Reports when the current joystick grip position is on the negative travel side (back, left, counterclockwise, down) relative";
CM_ SG_ 2365402110 Jystck6GrpYAxisNeutralPosStatus "Reports when the current joystick grip position is in the neutral position for that axis of travel.";
CM_ SG_ 2365402110 Joystick6GripXAxisPos "The position of the joystick grip in the relative motion of travel from the neutral position.";
CM_ SG_ 2365402110 Jystck6GrpXAxsLvrRghtPstvPsStts "Reports when the current joystick grip position is on the positive travel side (forward, right, clockwise, up) relative to the";
CM_ SG_ 2365402110 Jystck6GrpXAxsLvrLftNgtvPsSttus "Reports when the current joystick grip position is on the negative travel side (back, left, counterclockwise, down) relative";
CM_ SG_ 2365402110 Jystck6GrpXAxisNeutralPosStatus "Reports when the current joystick grip position is in the neutral position for that axis of travel.";
CM_ SG_ 2365402622 Jystck5GripXAxisDetentPosStatus "Reports when the current joystick grip position is in the detent position for that axis of travel.";
CM_ SG_ 2365402622 Jystck5GripYAxisDetentPosStatus "Reports when the current joystick grip position is in the detent position for that axis of travel.";
CM_ SG_ 2365402622 Jystck5ThetaAxisDetentPosStatus "Reports when the current joystick position is in the detent position for that axis of travel.";
CM_ SG_ 2365402622 Joystick5ThetaAxisPos "The position of the joystick in the relative motion of travel from the neutral position.";
CM_ SG_ 2365402622 Jystck5ThtAxsClckwsPstvPsStatus "Reports when the current joystick position is on the positive travel side (forward, right, clockwise, up) relative to the";
CM_ SG_ 2365402622 Jystck5ThtAxsCntrClckwsNgtvPsStt "Reports when the current joystick position is on the negative travel side (back, left, counterclockwise, down) relative to the";
CM_ SG_ 2365402622 Jystck5ThtaAxisNeutralPosStatus "Reports when the current joystick position is in the neutral position for that axis of travel.";
CM_ SG_ 2365402622 Joystick5GripYAxisPos "The position of the joystick grip in the relative motion of travel from the neutral position.";
CM_ SG_ 2365402622 Jystck5GrpYAxsLvrFrwrdPstvPsStts "Reports when the current joystick grip position is on the positive travel side (forward, right, clockwise, up) relative to the";
CM_ SG_ 2365402622 Jystck5GrpYAxsLvrBckNgtvPsSttus "Reports when the current joystick grip position is on the negative travel side (back, left, counterclockwise, down) relative";
CM_ SG_ 2365402622 Jystck5GrpYAxisNeutralPosStatus "Reports when the current joystick grip position is in the neutral position for that axis of travel.";
CM_ SG_ 2365402622 Joystick5GripXAxisPos "The position of the joystick grip in the relative motion of travel from the neutral position.";
CM_ SG_ 2365402622 Jystck5GrpXAxsLvrRghtPstvPsStts "Reports when the current joystick grip position is on the positive travel side (forward, right, clockwise, up) relative to the";
CM_ SG_ 2365402622 Jystck5GrpXAxsLvrLftNgtvPsSttus "Reports when the current joystick grip position is on the negative travel side (back, left, counterclockwise, down) relative";
CM_ SG_ 2365402622 Jystck5GrpXAxisNeutralPosStatus "Reports when the current joystick grip position is in the neutral position for that axis of travel.";
CM_ SG_ 2365403134 Jystck4GripXAxisDetentPosStatus "Reports when the current joystick grip position is in the detent position for that axis of travel.";
CM_ SG_ 2365403134 Jystck4GripYAxisDetentPosStatus "Reports when the current joystick grip position is in the detent position for that axis of travel.";
CM_ SG_ 2365403134 Jystck4ThetaAxisDetentPosStatus "Reports when the current joystick position is in the detent position for that axis of travel.";
CM_ SG_ 2365403134 Joystick4ThetaAxisPos "The position of the joystick in the relative motion of travel from the neutral position.";
CM_ SG_ 2365403134 Jystck4ThtAxsClckwsPstvPsStatus "Reports when the current joystick position is on the positive travel side (forward, right, clockwise, up) relative to the";
CM_ SG_ 2365403134 Jystck4ThtAxsCntrClckwsNgtvPsStt "Reports when the current joystick position is on the negative travel side (back, left, counterclockwise, down) relative to the";
CM_ SG_ 2365403134 Jystck4ThtaAxisNeutralPosStatus "Reports when the current joystick position is in the neutral position for that axis of travel.";
CM_ SG_ 2365403134 Joystick4GripYAxisPos "The position of the joystick grip in the relative motion of travel from the neutral position.";
CM_ SG_ 2365403134 Jystck4GrpYAxsLvrFrwrdPstvPsStts "Reports when the current joystick grip position is on the positive travel side (forward, right, clockwise, up) relative to the";
CM_ SG_ 2365403134 Jystck4GrpYAxsLvrBckNgtvPsSttus "Reports when the current joystick grip position is on the negative travel side (back, left, counterclockwise, down) relative";
CM_ SG_ 2365403134 Jystck4GrpYAxisNeutralPosStatus "Reports when the current joystick grip position is in the neutral position for that axis of travel.";
CM_ SG_ 2365403134 Joystick4GripXAxisPos "The position of the joystick grip in the relative motion of travel from the neutral position.";
CM_ SG_ 2365403134 Jystck4GrpXAxsLvrRghtPstvPsStts "Reports when the current joystick grip position is on the positive travel side (forward, right, clockwise, up) relative to the";
CM_ SG_ 2365403134 Jystck4GrpXAxsLvrLftNgtvPsSttus "Reports when the current joystick grip position is on the negative travel side (back, left, counterclockwise, down) relative";
CM_ SG_ 2365403134 Jystck4GrpXAxisNeutralPosStatus "Reports when the current joystick grip position is in the neutral position for that axis of travel.";
CM_ SG_ 2365400062 Jystck10GrpXAxisDetentPosStatus "Reports when the current joystick grip position is in the detent position for that axis of travel.";
CM_ SG_ 2365400062 Jystck10GrpYAxisDetentPosStatus "Reports when the current joystick grip position is in the detent position for that axis of travel.";
CM_ SG_ 2365400062 Jystck10ThtaAxisDetentPosStatus "Reports when the current joystick position is in the detent position for that axis of travel.";
CM_ SG_ 2365400062 Joystick10ThetaAxisPos "The position of the joystick in the relative motion of travel from the neutral position.";
CM_ SG_ 2365400062 Jystck10ThtAxsClckwsPstvPsSttus "Reports when the current joystick position is on the positive travel side (forward, right, clockwise, up) relative to the";
CM_ SG_ 2365400062 Jystck10ThtAxsCntrClckwsNgtvPsSt "Reports when the current joystick position is on the negative travel side (back, left, counterclockwise, down) relative to the";
CM_ SG_ 2365400062 Jystck10ThtAxisNeutralPosStatus "Reports when the current joystick position is in the neutral position for that axis of travel.";
CM_ SG_ 2365400062 Joystick10GripYAxisPos "The position of the joystick grip in the relative motion of travel from the neutral position.";
CM_ SG_ 2365400062 Jystck10GrpYAxsLvrFrwrdPstvPsStt "Reports when the current joystick grip position is on the positive travel side (forward, right, clockwise, up) relative to the";
CM_ SG_ 2365400062 Jystck10GrpYAxsLvrBckNgtvPsStts "Reports when the current joystick grip position is on the negative travel side (back, left, counterclockwise, down) relative";
CM_ SG_ 2365400062 Jystck10GrpYAxsNeutralPosStatus "Reports when the current joystick grip position is in the neutral position for that axis of travel.";
CM_ SG_ 2365400062 Joystick10GripXAxisPos "The position of the joystick grip in the relative motion of travel from the neutral position.";
CM_ SG_ 2365400062 Jystck10GrpXAxsLvrRghtPstvPsStts "Reports when the current joystick grip position is on the positive travel side (forward, right, clockwise, up) relative to the";
CM_ SG_ 2365400062 Jystck10GrpXAxsLvrLftNgtvPsStts "Reports when the current joystick grip position is on the negative travel side (back, left, counterclockwise, down) relative";
CM_ SG_ 2365400062 Jystck10GrpXAxsNeutralPosStatus "Reports when the current joystick grip position is in the neutral position for that axis of travel.";
CM_ SG_ 2566749438 DslPrtcltFltrActvRgnrtnFrcdStts "Indicates the forced execution status of diesel particulate filter regeneration.";
CM_ SG_ 2566749438 ExhaustSystemHighTempLampCmd "Command to control the exhaust system high temperature lamp.";
CM_ SG_ 2566749438 DslPrtcltFltrAtmtcActvRgnrtnIntt "Indicates the configuration of diesel particulate filter active regeneration automatic initiation.";
CM_ SG_ 2566749438 DslPrtcltFltrActvRgnrtnInhbtdDTV0 "Speed";
CM_ SG_ 2566749438 DslPrtcltFltrActvRgnrtnInhbtdDTE "Indicates the state of diesel particulate filter active regeneration inhibition due to the engine not being warmed up.";
CM_ SG_ 2566749438 DslPrtcltFltrActvRgnrtnInhbtdDTP0 "Indicates the state of diesel particulate filter active regeneration inhibition due to a permanent system lockout.";
CM_ SG_ 2566749438 DslPrtcltFltrActvRgnrtnInhbtdDTT "Indicates the state of diesel particulate filter active regeneration inhibition due to a temporary system lockout.";
CM_ SG_ 2566749438 DslPrtcltFltrActvRgnrtnInhbtdDTS0 "Indicates the state of diesel particulate filter active regeneration inhibition due to a system timeout.";
CM_ SG_ 2566749438 DslPrtcltFltrActvRgnrtnInhbtdDTS1 "Indicates the state of diesel particulate filter active regeneration inhibition due to a system fault being active.";
CM_ SG_ 2566749438 DslPrtcltFltrActvRgnrtnInhbtdDTL "Indicates the state of diesel particulate filter active regeneration inhibition due to the exhaust gas temperature being too";
CM_ SG_ 2566749438 DslPrtcltFltrActvRgnrtnInhbtdDTP1 "Indicates the state of diesel particulate filter active regeneration inhibition due to the parking brake being not set.";
CM_ SG_ 2566749438 DslPrtcltFltrActvRgnrtnInhbtdDTV1 "Speed";
CM_ SG_ 2566749438 DslPrtcltFltrActvRgnrtnInhbtdDTO "Indicates the state of diesel particulate filter active regeneration inhibition due to the transmission being out of neutral.";
CM_ SG_ 2566749438 DslPrtcltFltrActvRgnrtnInhbtdDTA "Indicates the state of diesel particulate filter active regeneration inhibition due to the accelerator pedal being off idle.";
CM_ SG_ 2566749438 DslPrtcltFltrActvRgnrtnInhbtdDTP2 "Indicates the state of diesel particulate filter active regeneration inhibition due to the PTO being active.";
CM_ SG_ 2566749438 DslPrtcltFltrActvRgnrtnInhbtdDTS2 "Indicates the state of diesel particulate filter active regeneration inhibition due to the service brake being active.";
CM_ SG_ 2566749438 DslPrtcltFltrActvRgnrtnInhbtdDTC "Indicates the state of diesel particulate filter active regeneration inhibition due to the clutch being disengaged.";
CM_ SG_ 2566749438 DslPrtcltFltrActvRgnrtnInhbtdDTI "Indicates the state of diesel particulate filter active regeneration inhibition due to the Diesel Particulate Filter Regeneration";
CM_ SG_ 2566749438 DslPrtcltFltrActvRgnrtnInhbtdStt "Indicates the state of diesel particulate filter active regeneration inhibition.";
CM_ SG_ 2566749438 DieselParticulateFilterStatus "Indicates the state of the diesel particulate filter regeneration need and urgency.";
CM_ SG_ 2566749438 DslPrtcltFltrActvRgnrtionStatus "Indicates the state of diesel particulate filter active regeneration.";
CM_ SG_ 2566749438 DslPrtcltFltrPssvRgnrtionStatus "Indicates the state of diesel particulate filter passive regeneration.";
CM_ SG_ 2566749438 DieselParticulateFilterLampCmd "Command to control the diesel particulate filter lamp.";
CM_ SG_ 2561212158 TextDisplayInstructions "This parameter describes the status for the display how to show the information.";
CM_ SG_ 2566746366 RetractStatusOfRamp5 "Retract status of ramp at doorway 5, counting from front to back on the vehicle.";
CM_ SG_ 2566746366 RetractStatusOfRamp4 "Retract status of ramp at doorway 4, counting from front to back on the vehicle.";
CM_ SG_ 2566746366 MovementStatusOfRamp5 "Movement status of ramp at doorway 5, counting from front to back on the vehicle.";
CM_ SG_ 2566746366 MovementStatusOfRamp4 "Movement status of ramp at doorway 4, counting from front to back on the vehicle.";
CM_ SG_ 2566746366 EnableStatusOfRamp5 "Enable status of ramp at doorway 5, counting from front to back on the vehicle.";
CM_ SG_ 2566746366 EnableStatusOfRamp4 "Enable status of ramp at doorway 4, counting from front to back on the vehicle.";
CM_ SG_ 2566746366 MovementStatusOfRamp3 "Movement status of ramp at doorway 3, counting from front to back on the vehicle.";
CM_ SG_ 2566746366 EnableStatusOfRamp3 "Enable status of ramp at doorway 3, counting from front to back on the vehicle.";
CM_ SG_ 2566746366 RetractStatusOfRamp3 "Retract status of ramp at doorway 3, counting from front to back on the vehicle.";
CM_ SG_ 2566746366 MovementStatusOfRamp2 "Movement status of ramp at doorway 2, counting from front to back on the vehicle.";
CM_ SG_ 2566746366 EnableStatusOfRamp2 "Enable status of ramp at doorway 2, counting from front to back on the vehicle.";
CM_ SG_ 2566746366 RetractStatusOfRamp2 "Retract status of ramp at doorway 2, counting from front to back on the vehicle.";
CM_ SG_ 2566746366 MovementStatusOfRamp1 "Movement status of ramp at doorway 1, counting from front to back on the vehicle.";
CM_ SG_ 2566746366 EnableStatusOfRamp1 "Enable status of ramp at doorway 1, counting from front to back on the vehicle.";
CM_ SG_ 2566746366 RetractStatusOfRamp1 "Retract status of ramp at doorway 1, counting from front to back on the vehicle.";
CM_ SG_ 2566750206 MaxCrankAttemptsPerStartAttempt "The number of cranking cycles that will be performed before ending the start attempt.";
CM_ SG_ 2566755582 EngExhstGsRcrculation1Valve2Pos "The position of the second exhaust gas recirculation valve expressed as a percentage of full travel.";
CM_ SG_ 2566755582 EngExhstGsRcirculation1ValvePos "The position of the exhaust gas recirculation valve expressed as a percentage of full travel.";
CM_ SG_ 2566755582 EngCrnkcsBrthrOilSeparatorSpeed "The speed of a rotating (centrifugal) crankcase oil separator.";
CM_ SG_ 2566755582 CmdedEngIntakeManifoldPress "Provides the commanded set point value for the engine intake manifold pressure.";
CM_ SG_ 2566746110 EngExhstGsRcrcltn1ClrIntkGsAbsPr "Exhaust Gas Recirculation gas absolute pressure is measured at the EGR cooler intake.";
CM_ SG_ 2566746110 EngExhstGsRcrcltn1ClrIntakeTemp "Exhaust Gas Recirculation (EGR) Temperature measured at the EGR cooler intake.";
CM_ SG_ 2566746110 EngExhstGsRcrcltn1ClrEfficiency "Exhaust Gas Recirculation cooler efficiency is an indication of the cooler's ability to reduce the temperature of the exhaust";
CM_ SG_ 2566746110 EngExhstGsRcrclation1Valve2Ctrl "Desired percentage of maximum Exhaust Gas Recirculation (EGR) valve opening for valve 2.";
CM_ SG_ 2499641854 EGR1CoolerBypassActuatorPostion "The parameter gives the % open of the EGR Cooler Bypass Actuator, where 0% = Fully Closed (no gas flowing through";
CM_ SG_ 2566748158 EngSparkPlug4 "The measured voltage of the spark event on Cylinder #4";
CM_ SG_ 2566748158 EngSparkPlug3 "The measured voltage of the spark event on Cylinder #3";
CM_ SG_ 2566748158 EngSparkPlug2 "The measured voltage of the spark event on Cylinder #2";
CM_ SG_ 2566748158 EngSparkPlug1 "The measured voltage of the spark event on Cylinder #1";
CM_ SG_ 2566747902 EngSparkPlug8 "The measured voltage of the spark event on Cylinder #8";
CM_ SG_ 2566747902 EngSparkPlug7 "The measured voltage of the spark event on Cylinder #7";
CM_ SG_ 2566747902 EngSparkPlug6 "The measured voltage of the spark event on Cylinder #6";
CM_ SG_ 2566747902 EngSparkPlug5 "The measured voltage of the spark event on Cylinder #5";
CM_ SG_ 2566747646 EngSparkPlug12 "The measured voltage of the spark event on Cylinder #12";
CM_ SG_ 2566747646 EngSparkPlug11 "The measured voltage of the spark event on Cylinder #11";
CM_ SG_ 2566747646 EngSparkPlug10 "The measured voltage of the spark event on Cylinder #10";
CM_ SG_ 2566747646 EngSparkPlug9 "The measured voltage of the spark event on Cylinder #9";
CM_ SG_ 2566747390 EngSparkPlug16 "The measured voltage of the spark event on Cylinder #16";
CM_ SG_ 2566747390 EngSparkPlug15 "The measured voltage of the spark event on Cylinder #15";
CM_ SG_ 2566747390 EngSparkPlug14 "The measured voltage of the spark event on Cylinder #14";
CM_ SG_ 2566747390 EngSparkPlug13 "The measured voltage of the spark event on Cylinder #13";
CM_ SG_ 2566747134 EngSparkPlug20 "The measured voltage of the spark event on Cylinder #20";
CM_ SG_ 2566747134 EngSparkPlug19 "The measured voltage of the spark event on Cylinder #19";
CM_ SG_ 2566747134 EngSparkPlug18 "The measured voltage of the spark event on Cylinder #18";
CM_ SG_ 2566747134 EngSparkPlug17 "The measured voltage of the spark event on Cylinder #17";
CM_ SG_ 2566746878 EngSparkPlug24 "The measured voltage of the spark event on Cylinder #24";
CM_ SG_ 2566746878 EngSparkPlug23 "The measured voltage of the spark event on Cylinder #23";
CM_ SG_ 2566746878 EngSparkPlug22 "The measured voltage of the spark event on Cylinder #22";
CM_ SG_ 2566746878 EngSparkPlug21 "The measured voltage of the spark event on Cylinder #21";
CM_ SG_ 2561277694 LaneDepartureWarningEnableCmd "Command to enable/disable Lane Departure Indication";
CM_ SG_ 2633861886 J2012DTCOccurrenceCount "Number of occurrences of the respective SAE J2012 DTC being conveyed.";
CM_ SG_ 2633861886 J2012DTCStatus "Indicates if the respective SAE J2012 DTC is active or previously active.";
CM_ SG_ 2633861886 NumberOfJ2012DTCs "The number J2012 DTCs being conveyed in PGN 64906.";
CM_ SG_ 2565873150 MessageChecksum "The message checksum is used to verify the signal path from the demanding device to the steering controller.";
CM_ SG_ 2565873150 MessageCounter "The message counter is to verify the signal path from the demanding device to the steering controller.";
CM_ SG_ 2565873150 SteerAngleSensorCalibrated "This signal indicates the calibration status of the steering angle sensor.";
CM_ SG_ 2565873150 SteerAngleSensorActiveMode "This signal indicates the operational mode of the steering angle sensor.";
CM_ SG_ 2565873150 SteerWheelAngleRange "The signal indicates the range of the steering wheel angle the sensor element is capable to measure.";
CM_ SG_ 2565873150 SteerWheelAngleRangeCounterType "The signal indicates whether the steering wheel angle sensor is capable of absolute measuring of the number of steering";
CM_ SG_ 2565873150 SteerWheelAngleRangeCounter "The signal indicates the number of steering wheel angle range overflows if the operating range of steering wheel is";
CM_ SG_ 2565873150 SteerWheelAngle "The main operator`s steering wheel angle (on the steering column, not the actual wheel angle).";
CM_ SG_ 2566745854 Aftrtrtmnt1SCRCtlystCnvrsnEffcnc "The SCR catalyst conversion efficiency percentage.";
CM_ SG_ 2566745854 Aftrtrtmnt1SCRCmddCtlystRgntCnsm "This parameter transmits the amount of reagent that the emissions control system has requested to be used, averaged";
CM_ SG_ 2566745854 Aftrtrtmnt1SCRAvrgCtlystRgntCnsm "Measured use of reagent by a Selective Catalytic Reduction system for exhaust emission control, averaged over the";
CM_ SG_ 2566745854 Aftrtrtmnt1DslExhstFldTnkLwLvlIn "The distance traveled while diesel exhaust fluid is low/empty or driver warning/inducement strategy is active.";
CM_ SG_ 2566751230 TransferCaseStatus "This parameter describes the feedback from the transfer case controller .";
CM_ SG_ 2566755838 TrnsTrqueConverterOilOutletTemp "Temperature of transmission torque converter outlet oil.";
CM_ SG_ 2566755838 TransOverheatIndicator "Signal from transmission indicating that its fluid temperature is above normal acceptable limits, and as a result,";
CM_ SG_ 2566755838 TransOilLifeRemaining "Signal which indicates the actual oil life remaining in percent.";
CM_ SG_ 2566755838 TransOilLevelSwitch "This switch indicates whether transmission oil level is full or empty.";
CM_ SG_ 2566755838 TransOilFilterRestrictionSwitch "This switch indicates whether the transmission oil filter is clogged.";
CM_ SG_ 2566752766 VehicleRoll "This parameter indicates the roll in degrees from level.";
CM_ SG_ 2633938942 TotalEngCruiseTime "Total time that the engine has operated in the cruise hold state, excluding time in accelerator override, over the life of the engine.";
CM_ SG_ 2633938942 TotalDriveAverageLoadFactor "Average engine load factor while engine speed is greater than zero, vehicle speed is greater than or equal to 2 km/h, and";
CM_ SG_ 2633938942 TripDriveAverageLoadFactor "Average engine load factor while engine speed is greater than zero, vehicle speed is greater than or equal to 2 km/h, and";
CM_ SG_ 2633938942 TripAverageEngSpeed "Average speed of the engine since the last trip reset.";
CM_ SG_ 2633938942 TripMaxEngSpeed "Maximum engine speed achieved since the last trip reset.";
CM_ SG_ 2566799614 ImplementRearWorkLight "This parameter provides measured data from the implement rear work lamps.";
CM_ SG_ 2566799614 ImplementLeftForwardWorkLight "This parameter provides measured data from the forward facing work lights toward the left end of the implement.";
CM_ SG_ 2566799614 ImplementRightForwardWorkLight "This parameter provides measured data from the forward facing work lights toward the right end of the implement.";
CM_ SG_ 2566799614 ImplementLeftFacingWorkLight "This parameter provides measured data from the work lights mounted on an implement to illuminate beyond left end of";
CM_ SG_ 2566799614 ImplementRightFacingWorkLight "This parameter provides measured data from the work lights mounted on an implement to illuminate beyond right end of";
CM_ SG_ 2566799614 ImplementOEMOption1Light "This parameter provides measured data from the implement OEM option 1 light.";
CM_ SG_ 2566799614 ImplementOEMOption2Light "This parameter provides measured data from the implement OEM option 2 light.";
CM_ SG_ 2566799614 TrctrFrontHighMountedWorkLights "This parameter provides measured data from the tractor front high mounted work lights.";
CM_ SG_ 2566799614 TrctorFrontLowMountedWorkLights "This parameter provides measured data from the tractor front low mounted work lights.";
CM_ SG_ 2566799614 TrctorSideHighMountedWorkLights "This parameter provides measured data from the tractor side high mounted work lights.";
CM_ SG_ 2566799614 TractorSideLowMountedWorkLights "This parameter provides measured data from the tractor side low mounted work lights.";
CM_ SG_ 2566799614 TrctorRearHighMountedWorkLights "This parameter provides measured data from the tractor rear high mounted work lights.";
CM_ SG_ 2566799614 TractorRearLowMountedWorkLights "This parameter provides measured data from the tractor rear low mounted work lights.";
CM_ SG_ 2566799614 TrctrUndersideMountedWorkLights "This parameter provides measured data from the tractor underside mounted work lights.";
CM_ SG_ 2566799614 RearFogLights "This parameter provides measured data from the tractor and/or implement rear fog lights.";
CM_ SG_ 2566799614 TractorMarkerLight "This parameter provides measured data from the tractor and attached implement marker lights, including front position";
CM_ SG_ 2566799614 ImplementMarkerLight "This parameter provides measured data from an attached implement marker lights, including front position lights, rear tail";
CM_ SG_ 2566799614 TractorClearanceLight "This parameter provides measured data from the tractor high mounted clearance and center ID lights.";
CM_ SG_ 2566799614 ImplementClearanceLight "This parameter provides measured data from an attached implement high mounted clearance lights.";
CM_ SG_ 2566799614 LeftStopLight "This parameter provides measured data from the tractor and attached implement left stop lights.";
CM_ SG_ 2566799614 RightStopLight "This parameter provides measured data from the tractor and attached implement right stop lights.";
CM_ SG_ 2566799614 CenterStopLight "This parameter provides measured data from the tractor and attached implement center stop lights.";
CM_ SG_ 2566799614 BackUpLightAndAlarmHorn "This parameter provides measured data from the back up lights and/ or associated alarm.";
CM_ SG_ 2566799614 LeftTurnSignalLights "This parameter provides measured data from the tractor and attached implement left turn signal lights.";
CM_ SG_ 2566799614 RightTurnSignalLights "This parameter provides measured data from the tractor and attached implement right turn signal lights.";
CM_ SG_ 2566799614 RotatingBeaconLight "This parameter provides measured data from the beacon light on tractor or attached implements.";
CM_ SG_ 2566799614 TractorFrontFogLights "This parameter provides measured data from the tractor front fog lights.";
CM_ SG_ 2566799614 HighBeamHeadLightData "This parameter provides measured data from the tractor high beam head light lamps.";
CM_ SG_ 2566799614 LowBeamHeadLightData "This parameter provides measured data from the tractor low beam head light lamps.";
CM_ SG_ 2566799614 AltBeamHeadLightData "This parameter provides measured data from the tractor alternate beam head light lamps.";
CM_ SG_ 2566799614 RunningLight "This parameter provides measured data from the vehicle's running lights.";
CM_ SG_ 2365473278 ImplementRearWorkLightCmd "Command to activate or de-activate implement rear work lights.";
CM_ SG_ 2365473278 ImplmentLeftForwardWorkLightCmd "Command to activate or de-activate the forward facing work lights toward the left end of the implement.";
CM_ SG_ 2365473278 ImplmntRightForwardWorkLightCmd "Command to activate or de-activate the forward facing work lights toward the right end of the implement.";
CM_ SG_ 2365473278 LightingDataRqCmd "Command to provide a response of the light state";
CM_ SG_ 2365473278 ImplementLeftFacingWorkLightCmd "Command to activate or de-activate work lights mounted on an implement to illuminate beyond left end of the implement.";
CM_ SG_ 2365473278 ImplmentRightFacingWorkLightCmd "Command to activate or de-activate work lights mounted on an implement to illuminate beyond right end of the implement.";
CM_ SG_ 2365473278 ImplementOEMOption1LightCmd "Command to activate or de-activate an implement OEM option 1 light.";
CM_ SG_ 2365473278 ImplementOEMOption2LightCmd "Command to activate or de-activate an implement OEM option 2 light.";
CM_ SG_ 2365473278 TrctrFrntHghMuntedWorkLightsCmd "Command to activate or de-activate the tractor front high mounted work lights.";
CM_ SG_ 2365473278 TrctrFrntLwMountedWorkLightsCmd "Command to activate or de-activate the tractor front low mounted work lights.";
CM_ SG_ 2365473278 TrctrSdHighMountedWorkLightsCmd "Command to activate or de-activate the tractor side high mounted work lights.";
CM_ SG_ 2365473278 TrctrSdeLowMountedWorkLightsCmd "Command to activate or de-activate the tractor side low mounted work lights.";
CM_ SG_ 2365473278 TrctrRrHighMountedWorkLightsCmd "Command to activate or de-activate the tractor rear high mounted work lights.";
CM_ SG_ 2365473278 TrctrRarLowMountedWorkLightsCmd "Command to activate or de-activate the tractor rear low mounted work lights.";
CM_ SG_ 2365473278 TrctrUndrsdMountedWorkLightsCmd "Command to activate or de-activate the tractor underside mounted work lights.";
CM_ SG_ 2365473278 RearFogLightCmd "Command to activate or de-activate tractor or implement rear fog lights.";
CM_ SG_ 2365473278 TractorMarkerLightCmd "Command to activate or de-activate tractor and implement front position lights, rear red tail lights, side amber running";
CM_ SG_ 2365473278 ImplementMarkerLightCmd "Command to activate or de-activate implement front position lights, rear red tail lights, side amber running lights, license";
CM_ SG_ 2365473278 TractorClearanceLightCmd "Command to activate or de-activate the tractor high mounted clearance and center ID lights";
CM_ SG_ 2365473278 ImplementClearanceLightCmd "Command to activate or de-activate the implement high mounted clearance and lights.";
CM_ SG_ 2365473278 LeftStopLightCmd "Command to activate or de-activate the tractor and implement left stop lights";
CM_ SG_ 2365473278 RightStopLightCmd "Command to activate or de-activate the tractor and implement right stop light";
CM_ SG_ 2365473278 CenterStopLightCmd "Command to activate or de-activate the tractor and implement center stop light";
CM_ SG_ 2365473278 BackUpLightAndAlarmHornCmd "Command to activate or de-activate the back up lights and/ or associated alarm if required";
CM_ SG_ 2365473278 LeftTurnSignalLightsCmd "Command to activate or de-activate left turn signal lights on the tractor and all connected implements";
CM_ SG_ 2365473278 RightTurnSignalLightsCmd "Command to activate or de-activate right turn signal lights on the tractor and all connected implements";
CM_ SG_ 2365473278 RotatingBeaconLightCmd "Command to activate or de-activate slow moving vehicle indicator lights on tractor and/or implements.";
CM_ SG_ 2365473278 TractorFrontFogLightsCmd "Command to activate or de-activate tractor front fog lights.";
CM_ SG_ 2365473278 HighBeamHeadLightCmd "Command to activate or de-activate the tractor high beam head light lamps.";
CM_ SG_ 2365473278 LowBeamHeadLightCmd "Command to activate or de-activate the tractor low beam head light lamps.";
CM_ SG_ 2365473278 AltBeamHeadLightCmd "Command to activate or de-activate the tractor alternate head lights (only low beam is available on alternate head lights).";
CM_ SG_ 2365473278 RunningLightCmd "Command to activate or de-activate the tractor or powered vehicle running lights.";
CM_ SG_ 2365485822 BladeCtrlMode "Allows the user to select the type of blade control for the land leveling system.";
CM_ SG_ 2365485822 BladeDurationAndDirection "Used to indicate the duration and direction that the land leveling system blade moves.";
CM_ SG_ 2365485822 LandLevelingSystemEnableStatus "Communicate the enable/disable status of the Land Leveling System.";
CM_ SG_ 2365485822 BladeCtrlModeRight "Indicate if the land leveling system's automatic control is active or inactive for the elevation sensor on the right side of the";
CM_ SG_ 2365485822 BladeCtrlModeLeft "Indicate if the land leveling system's automatic control is active or inactive for the elevation sensor on the left side of the";
CM_ SG_ 2633926654 EngActualIgntTiming "The actual ignition timing at the current engine conditions.";
CM_ SG_ 2633926654 EngDesiredIgntTiming3 "A programmable timing value specific to the engine's application.";
CM_ SG_ 2633926654 EngDesiredIgntTiming2 "A programmable timing value specific to the engine's application.";
CM_ SG_ 2633926654 EngDesiredIgntTiming1 "A programmable timing value specific to the engine's application.";
CM_ SG_ 2633926398 EngCyl20IgntTiming "The ignition timing of the cylinder.";
CM_ SG_ 2633926398 EngCyl19IgntTiming "The ignition timing of the cylinder.";
CM_ SG_ 2633926398 EngCyl18IgntTiming "The ignition timing of the cylinder.";
CM_ SG_ 2633926398 EngCyl17IgntTiming "The ignition timing of the cylinder.";
CM_ SG_ 2633926142 EngCyl16IgntTiming "The ignition timing of the cylinder.";
CM_ SG_ 2633926142 EngCyl15IgntTiming "The ignition timing of the cylinder.";
CM_ SG_ 2633926142 EngCyl14IgntTiming "The ignition timing of the cylinder.";
CM_ SG_ 2633926142 EngCyl13IgntTiming "The ignition timing of the cylinder.";
CM_ SG_ 2633925886 EngCyl12IgntTiming "The ignition timing of the cylinder.";
CM_ SG_ 2633925886 EngCyl11IgntTiming "The ignition timing of the cylinder.";
CM_ SG_ 2633925886 EngCyl10IgntTiming "The ignition timing of the cylinder.";
CM_ SG_ 2633925886 EngCyl9IgntTiming "The ignition timing of the cylinder.";
CM_ SG_ 2633925630 EngCyl8IgntTiming "The ignition timing of the cylinder.";
CM_ SG_ 2633925630 EngCyl7IgntTiming "The ignition timing of the cylinder.";
CM_ SG_ 2633925630 EngCyl6IgntTiming "The ignition timing of the cylinder.";
CM_ SG_ 2633925630 EngCyl5IgntTiming "The ignition timing of the cylinder.";
CM_ SG_ 2633925374 EngCyl4IgntTiming "The ignition timing of the cylinder.";
CM_ SG_ 2633925374 EngCyl3IgntTiming "The ignition timing of the cylinder.";
CM_ SG_ 2633925374 EngCyl2IgntTiming "The ignition timing of the cylinder.";
CM_ SG_ 2633925374 EngCyl1IgntTiming "The ignition timing of the cylinder.";
CM_ SG_ 2633927422 EngCyl20IgntTransSecondOutput "This parameter indicates the relative intensity of the secondary output voltage of the ignition transformer.";
CM_ SG_ 2633927422 EngCyl19IgntTransSecondOutput "This parameter indicates the relative intensity of the secondary output voltage of the ignition transformer.";
CM_ SG_ 2633927422 EngCyl18IgntTransSecondOutput "This parameter indicates the relative intensity of the secondary output voltage of the ignition transformer.";
CM_ SG_ 2633927422 EngCyl17IgntTransSecondOutput "This parameter indicates the relative intensity of the secondary output voltage of the ignition transformer.";
CM_ SG_ 2633927166 EngCyl16IgntTransSecondOutput "This parameter indicates the relative intensity of the secondary output voltage of the ignition transformer.";
CM_ SG_ 2633927166 EngCyl15IgntTransSecondOutput "This parameter indicates the relative intensity of the secondary output voltage of the ignition transformer.";
CM_ SG_ 2633927166 EngCyl14IgntTransSecondOutput "This parameter indicates the relative intensity of the secondary output voltage of the ignition transformer.";
CM_ SG_ 2633927166 EngCyl13IgntTransSecondOutput "This parameter indicates the relative intensity of the secondary output voltage of the ignition transformer.";
CM_ SG_ 2633927166 EngCyl12IgntTransSecondOutput "This parameter indicates the relative intensity of the secondary output voltage of the ignition transformer.";
CM_ SG_ 2633927166 EngCyl11IgntTransSecondOutput "This parameter indicates the relative intensity of the secondary output voltage of the ignition transformer.";
CM_ SG_ 2633927166 EngCyl10IgntTransSecondOutput "This parameter indicates the relative intensity of the secondary output voltage of the ignition transformer.";
CM_ SG_ 2633927166 EngCyl9IgntTransSecondOutput "This parameter indicates the relative intensity of the secondary output voltage of the ignition transformer.";
CM_ SG_ 2633926910 EngCyl8IgntTransSecondOutput "This parameter indicates the relative intensity of the secondary output voltage of the ignition transformer.";
CM_ SG_ 2633926910 EngCyl7IgntTransSecondOutput "This parameter indicates the relative intensity of the secondary output voltage of the ignition transformer.";
CM_ SG_ 2633926910 EngCyl6IgntTransSecondOutput "This parameter indicates the relative intensity of the secondary output voltage of the ignition transformer.";
CM_ SG_ 2633926910 EngCyl5IgntTransSecondOutput "This parameter indicates the relative intensity of the secondary output voltage of the ignition transformer.";
CM_ SG_ 2633926910 EngCyl4IgntTransSecondOutput "This parameter indicates the relative intensity of the secondary output voltage of the ignition transformer.";
CM_ SG_ 2633926910 EngCyl3IgntTransSecondOutput "This parameter indicates the relative intensity of the secondary output voltage of the ignition transformer.";
CM_ SG_ 2633926910 EngCyl2IgntTransSecondOutput "This parameter indicates the relative intensity of the secondary output voltage of the ignition transformer.";
CM_ SG_ 2633926910 EngCyl1IgntTransSecondOutput "This parameter indicates the relative intensity of the secondary output voltage of the ignition transformer.";
CM_ SG_ 2566768894 EngOprtrPrmryIntrmdtSpdSlctStte "13 preprogrammed intermediate speed control settings are available for the controlling ECM to select.";
CM_ SG_ 2566769406 EngOprtrPrmryIntrmdtSpeedSelect "Allows the operator to select one of 13 preprogrammed Intermediate Speed Control settings.";
CM_ SG_ 2566839550 EngTotalIdleHours "Accumulated time of operation of the engine while under idle conditions.";
CM_ SG_ 2566839550 EngTotalIdleFuelUsed "Accumulated amount of fuel used during vehicle operation while under idle conditions.";
CM_ SG_ 2633934334 EngIntakeManifold6Temp "Temperature of pre-combustion air found in intake manifold number 6 of engine air supply system.";
CM_ SG_ 2633934334 EngIntakeManifold5Temp "Temperature of pre-combustion air found in intake manifold number 5 of engine air supply system.";
CM_ SG_ 2633934334 EngIntakeManifold4Temp "Temperature of pre-combustion air found in intake manifold of engine air supply system.";
CM_ SG_ 2633934334 EngIntakeManifold3Temp "Temperature of pre-combustion air found in intake manifold of engine air supply system.";
CM_ SG_ 2633934334 EngIntakeManifold2Temp "Temperature of pre-combustion air found in intake manifold of engine air supply system.";
CM_ SG_ 2566825726 EngTurbo4BoostPress "Gage pressure of air measured downstream of the compressor discharge side of the turbocharger.";
CM_ SG_ 2566825726 EngTurbo3BoostPress "Gage pressure of air measured downstream of the compressor discharge side of the turbocharger.";
CM_ SG_ 2566825726 EngTurbo2BoostPress "Gage pressure of air measured downstream of the compressor discharge side of the turbocharger.";
CM_ SG_ 2566825726 EngTurbo1BoostPress "Gage pressure of air measured downstream of the compressor discharge side of the turbocharger.";
CM_ SG_ 2566770942 EngAirFilter4DiffPress "Change in engine air system pressure, measured across the fourth air filter, due to the filter and any accumulation of solid";
CM_ SG_ 2566770942 EngAirFilter3DiffPress "Change in engine air system pressure, measured across the third air filter, due to the filter and any accumulation of solid";
CM_ SG_ 2566770942 EngAirFilter2DiffPress "Change in engine air system pressure, measured across the second air filter, due to the filter and any accumulation of";
CM_ SG_ 2566770942 EngIntakeManifold1AbsPress "The absolute pressure measurement of the air intake manifold.The absolute pressure measurement of the air intake manifold.";
CM_ SG_ 2566770942 EngIntakeManifold2AbsPress "The absolute pressure measurement of the air intake manifold for bank 2 or the second air intake manifold.";
CM_ SG_ 2566770942 EngIntakeManifold2Press "The gage pressure measurement of the air intake manifold for bank #2 or the second air intake manifold.";
CM_ SG_ 2566770942 EngIntakeManifold1AbsPressHiRes "The absolute pressure measurement of the air intake manifold.The absolute pressure measurement of the air intake manifold.";
CM_ SG_ 2566846206 EngCoolantFilterDiffPress "Change in coolant pressure, measured across the filter, due to the filter and any accumulation of solid or semisolid matter";
CM_ SG_ 2566846206 EngExhaustGasTemp "Temperature of combustion byproducts leaving the engine.";
CM_ SG_ 2566846206 EngAirFilter1DiffPress "Change in engine air system pressure, measured across the filter, due to the filter and any accumulation of solid foreign";
CM_ SG_ 2566846206 EngIntakeManifold1Temp "Temperature of pre-combustion air found in intake manifold of engine air supply system.";
CM_ SG_ 2566846206 EngIntakeManifold1Press "The gage pressure measurement of the air intake manifold.";
CM_ SG_ 2566846206 EngDslPrtclateFilterIntakePress "Exhaust back pressure as a result of particle accumulation on filter media placed in the exhaust stream.";
CM_ SG_ 2566846206 EngAirIntakePress "Absolute air pressure at input port to intake manifold or air box.";
CM_ SG_ 2566811134 CabHeatingZone "Parameter indicating whether the cab zone is being heated.";
CM_ SG_ 2566811134 EngHeatingZone "Parameter indicating whether the engine zone is being heated.";
CM_ SG_ 2566811134 CabVentilation "Indicates whether the cab is being ventilated or not.";
CM_ SG_ 2566811134 AuxHeaterMode "State of the auxiliary heater";
CM_ SG_ 2566811134 AuxHeaterOutputPowerPercent "Current auxiliary heater output power, relative to the auxiliary heater maximum output power.";
CM_ SG_ 2566811134 AuxHeaterInputAirTemp "Temperature of the input air in an auxiliary heater system.";
CM_ SG_ 2566811134 AuxHeaterOutputCoolantTemp "Temperature of the auxiliary heater output coolant (I.";
CM_ SG_ 2566811134 AuxHeaterWaterPumpStatus "Parameter indicating whether the auxiliary heater water pump is running";
CM_ SG_ 2298375934 RearAxleRightWheelSpeed "High resolution measurement of the speed of the right wheel on the rear axle.";
CM_ SG_ 2298375934 RearAxleLeftWheelSpeed "High resolution measurement of the speed of the left wheel on the rear axle.";
CM_ SG_ 2298375934 FrontAxleRightWheelSpeed "High resolution measurement of the speed of the right wheel on the front axle.";
CM_ SG_ 2298375934 FrontAxleLeftWheelSpeed "High resolution measurement of the speed of the left wheel on the front axle.";
CM_ SG_ 2565867774 FireApparatusPumpEngagement "The measured status of the pump used to provide water in fire fighting apparatus for distribution of water through water";
CM_ SG_ 2565867774 EngHydPressGovernorSwitch "Switch that sets the mode of hydraulic governor";
CM_ SG_ 2565867774 EngHydPrssGovernorModeIndicator "Mode for governor operation is hydraulic pressure control.";
CM_ SG_ 2565867774 HydPress "Hydraulic pressure measured at the output of the hydraulic pump.";
CM_ SG_ 2566841854 EngTotalRevolutions "Accumulated number of revolutions of engine crankshaft during its operation.";
CM_ SG_ 2566841854 EngTotalHoursOfOperation "Accumulated time of operation of engine.";
CM_ SG_ 2365449982 HydBrakeFluidLevelSwitch "Signal which indicates whether the hydraulic fluid level in the reservoir(s) is sufficient.";
CM_ SG_ 2365449982 HydBrakeSystemAudibleWarningCmd "Signal which commands an audible warning by the hydraulic braking system.";
CM_ SG_ 2365449982 HydBrkePressSupplyStateCircuit2 "Signal which indicates whether the hydraulic brake pressure supply of circuit 2 is reliable; that is, able to support";
CM_ SG_ 2365449982 HydBrkePressSupplyStateCircuit1 "Signal which indicates whether the hydraulic brake pressure supply of circuit 1 is reliable; that is, able to support";
CM_ SG_ 2365449982 HydBrkPressWarningStateCircuit2 "Signal which indicates whether the hydraulic brake pressure of circuit 2 is below the warning level";
CM_ SG_ 2365449982 HydBrkPressWarningStateCircuit1 "Signal which indicates whether the hydraulic brake pressure of circuit 1 is below the warning level";
CM_ SG_ 2365449982 HydBrakePressCircuit2 "Gage hydraulic pressure in circuit 2 of the hydraulic brake system";
CM_ SG_ 2365449982 HydBrakePressCircuit1 "Gage hydraulic pressure in circuit 1 of the hydraulic brake system";
CM_ SG_ 2633939198 TripDriveFuelEconomy "Trip drive fuel economy is equal to the distance traveled by vehicle in the drive state (engine speed greater than zero,";
CM_ SG_ 2633939198 TrpPTOGovernorNonmovingFuelUsed "Total fuel consumed while the PTO or remote PTO governors are in the hold state, the engine speed is greater than zero,";
CM_ SG_ 2633939198 TripVehicleIdleFuelUsed "Total fuel consumed while neither the PTO or remote PTO governors are active, the engine speed is greater than zero,";
CM_ SG_ 2633939198 TripCruiseFuelUsed "Total fuel consumed while the engine is in the cruise hold state since the last trip reset.";
CM_ SG_ 2633939198 TripDriveFuelUsed "Total fuel consumed while the engine speed is greater than zero, vehicle speed is greater than or equal to 2 km/h, and";
CM_ SG_ 2633939198 TripPTOGovernorMovingFuelUsed "Total fuel consumed while either the PTO or remote PTO governors are in the hold state, the engine speed is greater";
CM_ SG_ 2633927678 EngFuelValve1OutletAbsPress "Absolute Pressure of gas on outlet side of the first or only fuel system control valve.";
CM_ SG_ 2633927678 EngAirToFuelDiffPress "The differential pressure between the gaseous fuel and the air intake manifold.";
CM_ SG_ 2633927678 EngFuelValveDiffPress "The differential pressure between the intake and the outlet of a gaseous fuel valve.";
CM_ SG_ 2633927678 EngFuelValve1IntakeAbsPress "The absolute pressure of gas on the intake side of the first system control valve.";
CM_ SG_ 2633925118 EngFuelFlowRate2 "The rate at which the fuel is flowing through a fuel valve.";
CM_ SG_ 2633925118 EngFuelFlowRate1 "The rate at which the fuel is flowing through a fuel valve.";
CM_ SG_ 2633925118 EngRqedFuelValve2Pos "The requested position of a gaseous fuel valve 2 that is metering the fuel flow to the engine, as requested by the Engine";
CM_ SG_ 2633925118 EngRqedFuelValve1Pos "The requested position of a gaseous fuel valve 1 that is metering the fuel flow to the engine.";
CM_ SG_ 2633925118 EngFuelValve2Pos "The position of a gaseous fuel valve that is metering the fuel flow to the engine.";
CM_ SG_ 2633925118 EngFuelValve1Pos "The position of a gaseous fuel valve that is metering the fuel flow to the engine.";
CM_ SG_ 2633937662 TotalEngPTOGovernorFuelUsed "Total fuel used while the PTO or remote PTO governors are in the hold state and engine speed is above zero, over the";
CM_ SG_ 2633937662 TripAverageFuelRate "Average fuel rate, equal to trip fuel divided by trip time while the engine speed is above zero, since the last trip reset.";
CM_ SG_ 2633937662 EngFuelSpecificGravity "This parameter conveys the specific gravity of the gaseous fuel being used by the engine.";
CM_ SG_ 2566804990 SpecificHeatRatio "The specific heat ratio of the fuel.";

BA_DEF_ BO_ "GenMsgCycleTime" INT 0 3600000;
BA_DEF_ BO_ "GenMsgSendType" ENUM  "cyclic","reserved","cyclicIfActive","reserved","reserved","reserved","reserved","reserved","noMsgSendType";
BA_DEF_ BO_ "GenMsgStartDelayTime" INT 0 100000;
BA_DEF_ BO_ "VFrameFormat" ENUM  "StandardCAN","ExtendedCAN","reserved","J1939PG";
BA_DEF_ SG_ "GenSigStartValue" INT 0 10000;
BA_DEF_ SG_ "SPN" INT 0 524287;
BA_DEF_ SG_ "SigType" ENUM  "Default","Range","RangeSigned","ASCII","Discrete","Control","ReferencePGN","DTC","StringDelimiter","StringLength","StringLengthControl";
BA_DEF_ SG_ "SystemSignalLongSymbol" STRING;
BA_DEF_DEF_ "GenMsgCycleTime" 0;
BA_DEF_DEF_ "GenMsgSendType" "noMsgSendType";
BA_DEF_DEF_ "GenMsgStartDelayTime" 0;
BA_DEF_DEF_ "GenSigStartValue" 0;
BA_DEF_DEF_ "SPN" 0;
BA_DEF_DEF_ "SigType" "Default";
BA_DEF_DEF_ "VFrameFormat" "J1939PG";

BA_ "GenMsgCycleTime" BO_ 2358902526 100;
BA_ "GenMsgSendType" BO_ 2358902526 0;
BA_ "GenMsgCycleTime" BO_ 2566746366 1000;
BA_ "GenMsgCycleTime" BO_ 2566755582 100;
BA_ "GenMsgSendType" BO_ 2566755582 0;
BA_ "GenMsgCycleTime" BO_ 2499641854 500;
BA_ "GenMsgSendType" BO_ 2499641854 0;
BA_ "GenMsgCycleTime" BO_ 2565873150 10;
BA_ "GenMsgSendType" BO_ 2565873150 0;
BA_ "GenMsgCycleTime" BO_ 2566751230 1000;
BA_ "GenMsgSendType" BO_ 2566751230 0;
BA_ "GenMsgCycleTime" BO_ 2566755838 1000;
BA_ "GenMsgSendType" BO_ 2566755838 0;
BA_ "GenMsgCycleTime" BO_ 2365485822 50;
BA_ "GenMsgSendType" BO_ 2365485822 0;
BA_ "GenMsgCycleTime" BO_ 2566768894 1000;
BA_ "GenMsgSendType" BO_ 2566768894 0;
BA_ "GenMsgCycleTime" BO_ 2566769406 1000;
BA_ "GenMsgSendType" BO_ 2566769406 0;
BA_ "GenMsgCycleTime" BO_ 2633934334 1000;
BA_ "GenMsgSendType" BO_ 2633934334 0;
BA_ "GenMsgCycleTime" BO_ 2566825726 500;
BA_ "GenMsgSendType" BO_ 2566825726 0;
BA_ "GenMsgCycleTime" BO_ 2566770942 500;
BA_ "GenMsgSendType" BO_ 2566770942 0;
BA_ "GenMsgCycleTime" BO_ 2566846206 500;
BA_ "GenMsgSendType" BO_ 2566846206 0;
BA_ "GenMsgCycleTime" BO_ 2566811134 1000;
BA_ "GenMsgSendType" BO_ 2566811134 0;
BA_ "GenMsgCycleTime" BO_ 2298375934 20;
BA_ "GenMsgSendType" BO_ 2298375934 0;
BA_ "GenMsgCycleTime" BO_ 2565867774 50;
BA_ "GenMsgSendType" BO_ 2565867774 0;
BA_ "GenMsgCycleTime" BO_ 2365449982 100;
BA_ "GenMsgSendType" BO_ 2365449982 0;

BA_ "SPN" SG_ 2358902526 Joystick3Lamp10Cmd 4489;
BA_ "SigType" SG_ 2358902526 Joystick3Lamp10Cmd 4;
BA_ "SPN" SG_ 2358902526 Joystick3Lamp9Cmd 4488;
BA_ "SigType" SG_ 2358902526 Joystick3Lamp9Cmd 4;
BA_ "SPN" SG_ 2358902526 Joystick3Lamp8Cmd 4487;
BA_ "SigType" SG_ 2358902526 Joystick3Lamp8Cmd 4;
BA_ "SPN" SG_ 2358902526 Joystick3Lamp7Cmd 4486;
BA_ "SigType" SG_ 2358902526 Joystick3Lamp7Cmd 4;
BA_ "SPN" SG_ 2358902526 Joystick3Lamp6Cmd 4485;
BA_ "SigType" SG_ 2358902526 Joystick3Lamp6Cmd 4;
BA_ "SPN" SG_ 2358902526 Joystick3Lamp5Cmd 4484;
BA_ "SigType" SG_ 2358902526 Joystick3Lamp5Cmd 4;
BA_ "SPN" SG_ 2358902526 Joystick3Lamp4Cmd 4483;
BA_ "SigType" SG_ 2358902526 Joystick3Lamp4Cmd 4;
BA_ "SPN" SG_ 2358902526 Joystick3Lamp3Cmd 4482;
BA_ "SigType" SG_ 2358902526 Joystick3Lamp3Cmd 4;
BA_ "SPN" SG_ 2358902526 Joystick3Lamp2Cmd 4481;
BA_ "SigType" SG_ 2358902526 Joystick3Lamp2Cmd 4;
BA_ "SPN" SG_ 2358902526 Joystick3Lamp1Cmd 4480;
BA_ "SigType" SG_ 2358902526 Joystick3Lamp1Cmd 4;
BA_ "SPN" SG_ 2358902526 Joystick2Lamp10Cmd 4479;
BA_ "SigType" SG_ 2358902526 Joystick2Lamp10Cmd 4;
BA_ "SPN" SG_ 2358902526 Joystick2Lamp9Cmd 4478;
BA_ "SigType" SG_ 2358902526 Joystick2Lamp9Cmd 4;
BA_ "SPN" SG_ 2358902526 Joystick2Lamp8Cmd 4477;
BA_ "SigType" SG_ 2358902526 Joystick2Lamp8Cmd 4;
BA_ "SPN" SG_ 2358902526 Joystick2Lamp7Cmd 4476;
BA_ "SigType" SG_ 2358902526 Joystick2Lamp7Cmd 4;
BA_ "SPN" SG_ 2358902526 Joystick2Lamp6Cmd 4475;
BA_ "SigType" SG_ 2358902526 Joystick2Lamp6Cmd 4;
BA_ "SPN" SG_ 2358902526 Joystick2Lamp5Cmd 4474;
BA_ "SigType" SG_ 2358902526 Joystick2Lamp5Cmd 4;
BA_ "SPN" SG_ 2358902526 Joystick2Lamp4Cmd 4473;
BA_ "SigType" SG_ 2358902526 Joystick2Lamp4Cmd 4;
BA_ "SPN" SG_ 2358902526 Joystick2Lamp3Cmd 4472;
BA_ "SigType" SG_ 2358902526 Joystick2Lamp3Cmd 4;
BA_ "SPN" SG_ 2358902526 Joystick2Lamp2Cmd 4471;
BA_ "SigType" SG_ 2358902526 Joystick2Lamp2Cmd 4;
BA_ "SPN" SG_ 2358902526 Joystick2Lamp1Cmd 4470;
BA_ "SigType" SG_ 2358902526 Joystick2Lamp1Cmd 4;
BA_ "SPN" SG_ 2358902526 Joystick1Lamp10Cmd 4469;
BA_ "SigType" SG_ 2358902526 Joystick1Lamp10Cmd 4;
BA_ "SPN" SG_ 2358902526 Joystick1Lamp9Cmd 4468;
BA_ "SigType" SG_ 2358902526 Joystick1Lamp9Cmd 4;
BA_ "SPN" SG_ 2358902526 Joystick1Lamp8Cmd 4467;
BA_ "SigType" SG_ 2358902526 Joystick1Lamp8Cmd 4;
BA_ "SPN" SG_ 2358902526 Joystick1Lamp7Cmd 4466;
BA_ "SigType" SG_ 2358902526 Joystick1Lamp7Cmd 4;
BA_ "SPN" SG_ 2358902526 Joystick1Lamp6Cmd 4465;
BA_ "SigType" SG_ 2358902526 Joystick1Lamp6Cmd 4;
BA_ "SPN" SG_ 2358902526 Joystick1Lamp5Cmd 4464;
BA_ "SigType" SG_ 2358902526 Joystick1Lamp5Cmd 4;
BA_ "SPN" SG_ 2358902526 Joystick1Lamp4Cmd 4463;
BA_ "SigType" SG_ 2358902526 Joystick1Lamp4Cmd 4;
BA_ "SPN" SG_ 2358902526 Joystick1Lamp3Cmd 4462;
BA_ "SigType" SG_ 2358902526 Joystick1Lamp3Cmd 4;
BA_ "SPN" SG_ 2358902526 Joystick1Lamp2Cmd 4461;
BA_ "SigType" SG_ 2358902526 Joystick1Lamp2Cmd 4;
BA_ "SPN" SG_ 2358902526 Joystick1Lamp1Cmd 4460;
BA_ "SigType" SG_ 2358902526 Joystick1Lamp1Cmd 4;
BA_ "SPN" SG_ 2365400574 Jystck9GripXAxisDetentPosStatus 4712;
BA_ "SigType" SG_ 2365400574 Jystck9GripXAxisDetentPosStatus 4;
BA_ "SPN" SG_ 2365400574 Jystck9GripYAxisDetentPosStatus 4711;
BA_ "SigType" SG_ 2365400574 Jystck9GripYAxisDetentPosStatus 4;
BA_ "SPN" SG_ 2365400574 Jystck9ThetaAxisDetentPosStatus 4710;
BA_ "SigType" SG_ 2365400574 Jystck9ThetaAxisDetentPosStatus 4;
BA_ "SPN" SG_ 2365400574 Joystick9ThetaAxisPos 4709;
BA_ "SigType" SG_ 2365400574 Joystick9ThetaAxisPos 1;
BA_ "SPN" SG_ 2365400574 Jystck9ThtAxsClckwsPstvPsStatus 4708;
BA_ "SigType" SG_ 2365400574 Jystck9ThtAxsClckwsPstvPsStatus 4;
BA_ "SPN" SG_ 2365400574 Jystck9ThtAxsCntrClckwsNgtvPsStt 4707;
BA_ "SigType" SG_ 2365400574 Jystck9ThtAxsCntrClckwsNgtvPsStt 4;
BA_ "SystemSignalLongSymbol" SG_ 2365400574 Jystck9ThtAxsCntrClckwsNgtvPsStt "Jystck9ThtAxsCntrClckwsNgtvPsStts";
BA_ "SPN" SG_ 2365400574 Jystck9ThtaAxisNeutralPosStatus 4706;
BA_ "SigType" SG_ 2365400574 Jystck9ThtaAxisNeutralPosStatus 4;
BA_ "SPN" SG_ 2365400574 Joystick9GripYAxisPos 4705;
BA_ "SigType" SG_ 2365400574 Joystick9GripYAxisPos 1;
BA_ "SPN" SG_ 2365400574 Jystck9GrpYAxsLvrFrwrdPstvPsStts 4704;
BA_ "SigType" SG_ 2365400574 Jystck9GrpYAxsLvrFrwrdPstvPsStts 4;
BA_ "SPN" SG_ 2365400574 Jystck9GrpYAxsLvrBckNgtvPsSttus 4703;
BA_ "SigType" SG_ 2365400574 Jystck9GrpYAxsLvrBckNgtvPsSttus 4;
BA_ "SPN" SG_ 2365400574 Jystck9GrpYAxisNeutralPosStatus 4702;
BA_ "SigType" SG_ 2365400574 Jystck9GrpYAxisNeutralPosStatus 4;
BA_ "SPN" SG_ 2365400574 Joystick9GripXAxisPos 4701;
BA_ "SigType" SG_ 2365400574 Joystick9GripXAxisPos 1;
BA_ "SPN" SG_ 2365400574 Jystck9GrpXAxsLvrRghtPstvPsStts 4700;
BA_ "SigType" SG_ 2365400574 Jystck9GrpXAxsLvrRghtPstvPsStts 4;
BA_ "SPN" SG_ 2365400574 Jystck9GrpXAxsLvrLftNgtvPsSttus 4699;
BA_ "SigType" SG_ 2365400574 Jystck9GrpXAxsLvrLftNgtvPsSttus 4;
BA_ "SPN" SG_ 2365400574 Jystck9GrpXAxisNeutralPosStatus 4698;
BA_ "SigType" SG_ 2365400574 Jystck9GrpXAxisNeutralPosStatus 4;
BA_ "SPN" SG_ 2365401086 Jystck8GripXAxisDetentPosStatus 4675;
BA_ "SigType" SG_ 2365401086 Jystck8GripXAxisDetentPosStatus 4;
BA_ "SPN" SG_ 2365401086 Jystck8GripYAxisDetentPosStatus 4674;
BA_ "SigType" SG_ 2365401086 Jystck8GripYAxisDetentPosStatus 4;
BA_ "SPN" SG_ 2365401086 Jystck8ThetaAxisDetentPosStatus 4673;
BA_ "SigType" SG_ 2365401086 Jystck8ThetaAxisDetentPosStatus 4;
BA_ "SPN" SG_ 2365401086 Joystick8ThetaAxisPos 4672;
BA_ "SigType" SG_ 2365401086 Joystick8ThetaAxisPos 1;
BA_ "SPN" SG_ 2365401086 Jystck8ThtAxsClckwsPstvPsStatus 4671;
BA_ "SigType" SG_ 2365401086 Jystck8ThtAxsClckwsPstvPsStatus 4;
BA_ "SPN" SG_ 2365401086 Jystck8ThtAxsCntrClckwsNgtvPsStt 4670;
BA_ "SigType" SG_ 2365401086 Jystck8ThtAxsCntrClckwsNgtvPsStt 4;
BA_ "SystemSignalLongSymbol" SG_ 2365401086 Jystck8ThtAxsCntrClckwsNgtvPsStt "Jystck8ThtAxsCntrClckwsNgtvPsStts";
BA_ "SPN" SG_ 2365401086 Jystck8ThtaAxisNeutralPosStatus 4669;
BA_ "SigType" SG_ 2365401086 Jystck8ThtaAxisNeutralPosStatus 4;
BA_ "SPN" SG_ 2365401086 Joystick8GripYAxisPos 4668;
BA_ "SigType" SG_ 2365401086 Joystick8GripYAxisPos 1;
BA_ "SPN" SG_ 2365401086 Jystck8GrpYAxsLvrFrwrdPstvPsStts 4667;
BA_ "SigType" SG_ 2365401086 Jystck8GrpYAxsLvrFrwrdPstvPsStts 4;
BA_ "SPN" SG_ 2365401086 Jystck8GrpYAxsLvrBckNgtvPsSttus 4666;
BA_ "SigType" SG_ 2365401086 Jystck8GrpYAxsLvrBckNgtvPsSttus 4;
BA_ "SPN" SG_ 2365401086 Jystck8GrpYAxisNeutralPosStatus 4665;
BA_ "SigType" SG_ 2365401086 Jystck8GrpYAxisNeutralPosStatus 4;
BA_ "SPN" SG_ 2365401086 Joystick8GripXAxisPos 4664;
BA_ "SigType" SG_ 2365401086 Joystick8GripXAxisPos 1;
BA_ "SPN" SG_ 2365401086 Jystck8GrpXAxsLvrRghtPstvPsStts 4663;
BA_ "SigType" SG_ 2365401086 Jystck8GrpXAxsLvrRghtPstvPsStts 4;
BA_ "SPN" SG_ 2365401086 Jystck8GrpXAxsLvrLftNgtvPsSttus 4662;
BA_ "SigType" SG_ 2365401086 Jystck8GrpXAxsLvrLftNgtvPsSttus 4;
BA_ "SPN" SG_ 2365401086 Jystck8GrpXAxisNeutralPosStatus 4661;
BA_ "SigType" SG_ 2365401086 Jystck8GrpXAxisNeutralPosStatus 4;
BA_ "SPN" SG_ 2365401598 Jystck7GripXAxisDetentPosStatus 4638;
BA_ "SigType" SG_ 2365401598 Jystck7GripXAxisDetentPosStatus 4;
BA_ "SPN" SG_ 2365401598 Jystck7GripYAxisDetentPosStatus 4637;
BA_ "SigType" SG_ 2365401598 Jystck7GripYAxisDetentPosStatus 4;
BA_ "SPN" SG_ 2365401598 Jystck7ThetaAxisDetentPosStatus 4636;
BA_ "SigType" SG_ 2365401598 Jystck7ThetaAxisDetentPosStatus 4;
BA_ "SPN" SG_ 2365401598 Joystick7ThetaAxisPos 4635;
BA_ "SigType" SG_ 2365401598 Joystick7ThetaAxisPos 1;
BA_ "SPN" SG_ 2365401598 Jystck7ThtAxsClckwsPstvPsStatus 4634;
BA_ "SigType" SG_ 2365401598 Jystck7ThtAxsClckwsPstvPsStatus 4;
BA_ "SPN" SG_ 2365401598 Jystck7ThtAxsCntrClckwsNgtvPsStt 4633;
BA_ "SigType" SG_ 2365401598 Jystck7ThtAxsCntrClckwsNgtvPsStt 4;
BA_ "SystemSignalLongSymbol" SG_ 2365401598 Jystck7ThtAxsCntrClckwsNgtvPsStt "Jystck7ThtAxsCntrClckwsNgtvPsStts";
BA_ "SPN" SG_ 2365401598 Jystck7ThtaAxisNeutralPosStatus 4632;
BA_ "SigType" SG_ 2365401598 Jystck7ThtaAxisNeutralPosStatus 4;
BA_ "SPN" SG_ 2365401598 Joystick7GripYAxisPos 4631;
BA_ "SigType" SG_ 2365401598 Joystick7GripYAxisPos 1;
BA_ "SPN" SG_ 2365401598 Jystck7GrpYAxsLvrFrwrdPstvPsStts 4630;
BA_ "SigType" SG_ 2365401598 Jystck7GrpYAxsLvrFrwrdPstvPsStts 4;
BA_ "SPN" SG_ 2365401598 Jystck7GrpYAxsLvrBckNgtvPsSttus 4629;
BA_ "SigType" SG_ 2365401598 Jystck7GrpYAxsLvrBckNgtvPsSttus 4;
BA_ "SPN" SG_ 2365401598 Jystck7GrpYAxisNeutralPosStatus 4628;
BA_ "SigType" SG_ 2365401598 Jystck7GrpYAxisNeutralPosStatus 4;
BA_ "SPN" SG_ 2365401598 Joystick7GripXAxisPos 4627;
BA_ "SigType" SG_ 2365401598 Joystick7GripXAxisPos 1;
BA_ "SPN" SG_ 2365401598 Jystck7GrpXAxsLvrRghtPstvPsStts 4626;
BA_ "SigType" SG_ 2365401598 Jystck7GrpXAxsLvrRghtPstvPsStts 4;
BA_ "SPN" SG_ 2365401598 Jystck7GrpXAxsLvrLftNgtvPsSttus 4625;
BA_ "SigType" SG_ 2365401598 Jystck7GrpXAxsLvrLftNgtvPsSttus 4;
BA_ "SPN" SG_ 2365401598 Jystck7GrpXAxisNeutralPosStatus 4624;
BA_ "SigType" SG_ 2365401598 Jystck7GrpXAxisNeutralPosStatus 4;
BA_ "SPN" SG_ 2365402110 Jystck6GripXAxisDetentPosStatus 4601;
BA_ "SigType" SG_ 2365402110 Jystck6GripXAxisDetentPosStatus 4;
BA_ "SPN" SG_ 2365402110 Jystck6GripYAxisDetentPosStatus 4600;
BA_ "SigType" SG_ 2365402110 Jystck6GripYAxisDetentPosStatus 4;
BA_ "SPN" SG_ 2365402110 Jystck6ThetaAxisDetentPosStatus 4599;
BA_ "SigType" SG_ 2365402110 Jystck6ThetaAxisDetentPosStatus 4;
BA_ "SPN" SG_ 2365402110 Joystick6ThetaAxisPos 4598;
BA_ "SigType" SG_ 2365402110 Joystick6ThetaAxisPos 1;
BA_ "SPN" SG_ 2365402110 Jystck6ThtAxsClckwsPstvPsStatus 4597;
BA_ "SigType" SG_ 2365402110 Jystck6ThtAxsClckwsPstvPsStatus 4;
BA_ "SPN" SG_ 2365402110 Jystck6ThtAxsCntrClckwsNgtvPsStt 4596;
BA_ "SigType" SG_ 2365402110 Jystck6ThtAxsCntrClckwsNgtvPsStt 4;
BA_ "SystemSignalLongSymbol" SG_ 2365402110 Jystck6ThtAxsCntrClckwsNgtvPsStt "Jystck6ThtAxsCntrClckwsNgtvPsStts";
BA_ "SPN" SG_ 2365402110 Jystck6ThtaAxisNeutralPosStatus 4595;
BA_ "SigType" SG_ 2365402110 Jystck6ThtaAxisNeutralPosStatus 4;
BA_ "SPN" SG_ 2365402110 Joystick6GripYAxisPos 4594;
BA_ "SigType" SG_ 2365402110 Joystick6GripYAxisPos 1;
BA_ "SPN" SG_ 2365402110 Jystck6GrpYAxsLvrFrwrdPstvPsStts 4593;
BA_ "SigType" SG_ 2365402110 Jystck6GrpYAxsLvrFrwrdPstvPsStts 4;
BA_ "SPN" SG_ 2365402110 Jystck6GrpYAxsLvrBckNgtvPsSttus 4592;
BA_ "SigType" SG_ 2365402110 Jystck6GrpYAxsLvrBckNgtvPsSttus 4;
BA_ "SPN" SG_ 2365402110 Jystck6GrpYAxisNeutralPosStatus 4591;
BA_ "SigType" SG_ 2365402110 Jystck6GrpYAxisNeutralPosStatus 4;
BA_ "SPN" SG_ 2365402110 Joystick6GripXAxisPos 4590;
BA_ "SigType" SG_ 2365402110 Joystick6GripXAxisPos 1;
BA_ "SPN" SG_ 2365402110 Jystck6GrpXAxsLvrRghtPstvPsStts 4589;
BA_ "SigType" SG_ 2365402110 Jystck6GrpXAxsLvrRghtPstvPsStts 4;
BA_ "SPN" SG_ 2365402110 Jystck6GrpXAxsLvrLftNgtvPsSttus 4588;
BA_ "SigType" SG_ 2365402110 Jystck6GrpXAxsLvrLftNgtvPsSttus 4;
BA_ "SPN" SG_ 2365402110 Jystck6GrpXAxisNeutralPosStatus 4587;
BA_ "SigType" SG_ 2365402110 Jystck6GrpXAxisNeutralPosStatus 4;
BA_ "SPN" SG_ 2365402622 Jystck5GripXAxisDetentPosStatus 4564;
BA_ "SigType" SG_ 2365402622 Jystck5GripXAxisDetentPosStatus 4;
BA_ "SPN" SG_ 2365402622 Jystck5GripYAxisDetentPosStatus 4563;
BA_ "SigType" SG_ 2365402622 Jystck5GripYAxisDetentPosStatus 4;
BA_ "SPN" SG_ 2365402622 Jystck5ThetaAxisDetentPosStatus 4562;
BA_ "SigType" SG_ 2365402622 Jystck5ThetaAxisDetentPosStatus 4;
BA_ "SPN" SG_ 2365402622 Joystick5ThetaAxisPos 4561;
BA_ "SigType" SG_ 2365402622 Joystick5ThetaAxisPos 1;
BA_ "SPN" SG_ 2365402622 Jystck5ThtAxsClckwsPstvPsStatus 4560;
BA_ "SigType" SG_ 2365402622 Jystck5ThtAxsClckwsPstvPsStatus 4;
BA_ "SPN" SG_ 2365402622 Jystck5ThtAxsCntrClckwsNgtvPsStt 4559;
BA_ "SigType" SG_ 2365402622 Jystck5ThtAxsCntrClckwsNgtvPsStt 4;
BA_ "SystemSignalLongSymbol" SG_ 2365402622 Jystck5ThtAxsCntrClckwsNgtvPsStt "Jystck5ThtAxsCntrClckwsNgtvPsStts";
BA_ "SPN" SG_ 2365402622 Jystck5ThtaAxisNeutralPosStatus 4558;
BA_ "SigType" SG_ 2365402622 Jystck5ThtaAxisNeutralPosStatus 4;
BA_ "SPN" SG_ 2365402622 Joystick5GripYAxisPos 4557;
BA_ "SigType" SG_ 2365402622 Joystick5GripYAxisPos 1;
BA_ "SPN" SG_ 2365402622 Jystck5GrpYAxsLvrFrwrdPstvPsStts 4556;
BA_ "SigType" SG_ 2365402622 Jystck5GrpYAxsLvrFrwrdPstvPsStts 4;
BA_ "SPN" SG_ 2365402622 Jystck5GrpYAxsLvrBckNgtvPsSttus 4555;
BA_ "SigType" SG_ 2365402622 Jystck5GrpYAxsLvrBckNgtvPsSttus 4;
BA_ "SPN" SG_ 2365402622 Jystck5GrpYAxisNeutralPosStatus 4554;
BA_ "SigType" SG_ 2365402622 Jystck5GrpYAxisNeutralPosStatus 4;
BA_ "SPN" SG_ 2365402622 Joystick5GripXAxisPos 4553;
BA_ "SigType" SG_ 2365402622 Joystick5GripXAxisPos 1;
BA_ "SPN" SG_ 2365402622 Jystck5GrpXAxsLvrRghtPstvPsStts 4552;
BA_ "SigType" SG_ 2365402622 Jystck5GrpXAxsLvrRghtPstvPsStts 4;
BA_ "SPN" SG_ 2365402622 Jystck5GrpXAxsLvrLftNgtvPsSttus 4551;
BA_ "SigType" SG_ 2365402622 Jystck5GrpXAxsLvrLftNgtvPsSttus 4;
BA_ "SPN" SG_ 2365402622 Jystck5GrpXAxisNeutralPosStatus 4550;
BA_ "SigType" SG_ 2365402622 Jystck5GrpXAxisNeutralPosStatus 4;
BA_ "SPN" SG_ 2365403134 Jystck4GripXAxisDetentPosStatus 4527;
BA_ "SigType" SG_ 2365403134 Jystck4GripXAxisDetentPosStatus 4;
BA_ "SPN" SG_ 2365403134 Jystck4GripYAxisDetentPosStatus 4526;
BA_ "SigType" SG_ 2365403134 Jystck4GripYAxisDetentPosStatus 4;
BA_ "SPN" SG_ 2365403134 Jystck4ThetaAxisDetentPosStatus 4525;
BA_ "SigType" SG_ 2365403134 Jystck4ThetaAxisDetentPosStatus 4;
BA_ "SPN" SG_ 2365403134 Joystick4ThetaAxisPos 4524;
BA_ "SigType" SG_ 2365403134 Joystick4ThetaAxisPos 1;
BA_ "SPN" SG_ 2365403134 Jystck4ThtAxsClckwsPstvPsStatus 4523;
BA_ "SigType" SG_ 2365403134 Jystck4ThtAxsClckwsPstvPsStatus 4;
BA_ "SPN" SG_ 2365403134 Jystck4ThtAxsCntrClckwsNgtvPsStt 4522;
BA_ "SigType" SG_ 2365403134 Jystck4ThtAxsCntrClckwsNgtvPsStt 4;
BA_ "SystemSignalLongSymbol" SG_ 2365403134 Jystck4ThtAxsCntrClckwsNgtvPsStt "Jystck4ThtAxsCntrClckwsNgtvPsStts";
BA_ "SPN" SG_ 2365403134 Jystck4ThtaAxisNeutralPosStatus 4521;
BA_ "SigType" SG_ 2365403134 Jystck4ThtaAxisNeutralPosStatus 4;
BA_ "SPN" SG_ 2365403134 Joystick4GripYAxisPos 4520;
BA_ "SigType" SG_ 2365403134 Joystick4GripYAxisPos 1;
BA_ "SPN" SG_ 2365403134 Jystck4GrpYAxsLvrFrwrdPstvPsStts 4519;
BA_ "SigType" SG_ 2365403134 Jystck4GrpYAxsLvrFrwrdPstvPsStts 4;
BA_ "SPN" SG_ 2365403134 Jystck4GrpYAxsLvrBckNgtvPsSttus 4518;
BA_ "SigType" SG_ 2365403134 Jystck4GrpYAxsLvrBckNgtvPsSttus 4;
BA_ "SPN" SG_ 2365403134 Jystck4GrpYAxisNeutralPosStatus 4517;
BA_ "SigType" SG_ 2365403134 Jystck4GrpYAxisNeutralPosStatus 4;
BA_ "SPN" SG_ 2365403134 Joystick4GripXAxisPos 4516;
BA_ "SigType" SG_ 2365403134 Joystick4GripXAxisPos 1;
BA_ "SPN" SG_ 2365403134 Jystck4GrpXAxsLvrRghtPstvPsStts 4515;
BA_ "SigType" SG_ 2365403134 Jystck4GrpXAxsLvrRghtPstvPsStts 4;
BA_ "SPN" SG_ 2365403134 Jystck4GrpXAxsLvrLftNgtvPsSttus 4514;
BA_ "SigType" SG_ 2365403134 Jystck4GrpXAxsLvrLftNgtvPsSttus 4;
BA_ "SPN" SG_ 2365403134 Jystck4GrpXAxisNeutralPosStatus 4513;
BA_ "SigType" SG_ 2365403134 Jystck4GrpXAxisNeutralPosStatus 4;
BA_ "SPN" SG_ 2365400062 Jystck10GrpXAxisDetentPosStatus 4749;
BA_ "SigType" SG_ 2365400062 Jystck10GrpXAxisDetentPosStatus 4;
BA_ "SPN" SG_ 2365400062 Jystck10GrpYAxisDetentPosStatus 4748;
BA_ "SigType" SG_ 2365400062 Jystck10GrpYAxisDetentPosStatus 4;
BA_ "SPN" SG_ 2365400062 Jystck10ThtaAxisDetentPosStatus 4747;
BA_ "SigType" SG_ 2365400062 Jystck10ThtaAxisDetentPosStatus 4;
BA_ "SPN" SG_ 2365400062 Joystick10ThetaAxisPos 4746;
BA_ "SigType" SG_ 2365400062 Joystick10ThetaAxisPos 1;
BA_ "SPN" SG_ 2365400062 Jystck10ThtAxsClckwsPstvPsSttus 4745;
BA_ "SigType" SG_ 2365400062 Jystck10ThtAxsClckwsPstvPsSttus 4;
BA_ "SPN" SG_ 2365400062 Jystck10ThtAxsCntrClckwsNgtvPsSt 4744;
BA_ "SigType" SG_ 2365400062 Jystck10ThtAxsCntrClckwsNgtvPsSt 4;
BA_ "SystemSignalLongSymbol" SG_ 2365400062 Jystck10ThtAxsCntrClckwsNgtvPsSt "Jystck10ThtAxsCntrClckwsNgtvPsStts";
BA_ "SPN" SG_ 2365400062 Jystck10ThtAxisNeutralPosStatus 4743;
BA_ "SigType" SG_ 2365400062 Jystck10ThtAxisNeutralPosStatus 4;
BA_ "SPN" SG_ 2365400062 Joystick10GripYAxisPos 4742;
BA_ "SigType" SG_ 2365400062 Joystick10GripYAxisPos 1;
BA_ "SPN" SG_ 2365400062 Jystck10GrpYAxsLvrFrwrdPstvPsStt 4741;
BA_ "SigType" SG_ 2365400062 Jystck10GrpYAxsLvrFrwrdPstvPsStt 4;
BA_ "SystemSignalLongSymbol" SG_ 2365400062 Jystck10GrpYAxsLvrFrwrdPstvPsStt "Jystck10GrpYAxsLvrFrwrdPstvPsStts";
BA_ "SPN" SG_ 2365400062 Jystck10GrpYAxsLvrBckNgtvPsStts 4740;
BA_ "SigType" SG_ 2365400062 Jystck10GrpYAxsLvrBckNgtvPsStts 4;
BA_ "SPN" SG_ 2365400062 Jystck10GrpYAxsNeutralPosStatus 4739;
BA_ "SigType" SG_ 2365400062 Jystck10GrpYAxsNeutralPosStatus 4;
BA_ "SPN" SG_ 2365400062 Joystick10GripXAxisPos 4738;
BA_ "SigType" SG_ 2365400062 Joystick10GripXAxisPos 1;
BA_ "SPN" SG_ 2365400062 Jystck10GrpXAxsLvrRghtPstvPsStts 4737;
BA_ "SigType" SG_ 2365400062 Jystck10GrpXAxsLvrRghtPstvPsStts 4;
BA_ "SPN" SG_ 2365400062 Jystck10GrpXAxsLvrLftNgtvPsStts 4736;
BA_ "SigType" SG_ 2365400062 Jystck10GrpXAxsLvrLftNgtvPsStts 4;
BA_ "SPN" SG_ 2365400062 Jystck10GrpXAxsNeutralPosStatus 4735;
BA_ "SigType" SG_ 2365400062 Jystck10GrpXAxsNeutralPosStatus 4;
BA_ "SPN" SG_ 2566749438 DslPrtcltFltrActvRgnrtnFrcdStts 4175;
BA_ "SigType" SG_ 2566749438 DslPrtcltFltrActvRgnrtnFrcdStts 4;
BA_ "SPN" SG_ 2566749438 ExhaustSystemHighTempLampCmd 3698;
BA_ "SigType" SG_ 2566749438 ExhaustSystemHighTempLampCmd 4;
BA_ "SPN" SG_ 2566749438 DslPrtcltFltrAtmtcActvRgnrtnIntt 3718;
BA_ "SigType" SG_ 2566749438 DslPrtcltFltrAtmtcActvRgnrtnIntt 4;
BA_ "SystemSignalLongSymbol" SG_ 2566749438 DslPrtcltFltrAtmtcActvRgnrtnIntt "DslPrtcltFltrAtmtcActvRgnrtnInttnCnfg";
BA_ "SPN" SG_ 2566749438 DslPrtcltFltrActvRgnrtnInhbtdDTV0 3717;
BA_ "SigType" SG_ 2566749438 DslPrtcltFltrActvRgnrtnInhbtdDTV0 4;
BA_ "SystemSignalLongSymbol" SG_ 2566749438 DslPrtcltFltrActvRgnrtnInhbtdDTV0 "DslPrtcltFltrActvRgnrtnInhbtdDTVhclSpdBlwAllwd";
BA_ "SPN" SG_ 2566749438 DslPrtcltFltrActvRgnrtnInhbtdDTE 3716;
BA_ "SigType" SG_ 2566749438 DslPrtcltFltrActvRgnrtnInhbtdDTE 4;
BA_ "SystemSignalLongSymbol" SG_ 2566749438 DslPrtcltFltrActvRgnrtnInhbtdDTE "DslPrtcltFltrActvRgnrtnInhbtdDTEngNtWrmdUp";
BA_ "SPN" SG_ 2566749438 DslPrtcltFltrActvRgnrtnInhbtdDTP0 3715;
BA_ "SigType" SG_ 2566749438 DslPrtcltFltrActvRgnrtnInhbtdDTP0 4;
BA_ "SystemSignalLongSymbol" SG_ 2566749438 DslPrtcltFltrActvRgnrtnInhbtdDTP0 "DslPrtcltFltrActvRgnrtnInhbtdDTPrmnntSystmLckt";
BA_ "SPN" SG_ 2566749438 DslPrtcltFltrActvRgnrtnInhbtdDTT 3714;
BA_ "SigType" SG_ 2566749438 DslPrtcltFltrActvRgnrtnInhbtdDTT 4;
BA_ "SystemSignalLongSymbol" SG_ 2566749438 DslPrtcltFltrActvRgnrtnInhbtdDTT "DslPrtcltFltrActvRgnrtnInhbtdDTTmprrySystmLckt";
BA_ "SPN" SG_ 2566749438 DslPrtcltFltrActvRgnrtnInhbtdDTS0 3713;
BA_ "SigType" SG_ 2566749438 DslPrtcltFltrActvRgnrtnInhbtdDTS0 4;
BA_ "SystemSignalLongSymbol" SG_ 2566749438 DslPrtcltFltrActvRgnrtnInhbtdDTS0 "DslPrtcltFltrActvRgnrtnInhbtdDTSystmTmt";
BA_ "SPN" SG_ 2566749438 DslPrtcltFltrActvRgnrtnInhbtdDTS1 3712;
BA_ "SigType" SG_ 2566749438 DslPrtcltFltrActvRgnrtnInhbtdDTS1 4;
BA_ "SystemSignalLongSymbol" SG_ 2566749438 DslPrtcltFltrActvRgnrtnInhbtdDTS1 "DslPrtcltFltrActvRgnrtnInhbtdDTSystmFltActv";
BA_ "SPN" SG_ 2566749438 DslPrtcltFltrActvRgnrtnInhbtdDTL 3711;
BA_ "SigType" SG_ 2566749438 DslPrtcltFltrActvRgnrtnInhbtdDTL 4;
BA_ "SystemSignalLongSymbol" SG_ 2566749438 DslPrtcltFltrActvRgnrtnInhbtdDTL "DslPrtcltFltrActvRgnrtnInhbtdDTLwExhstGsTmp";
BA_ "SPN" SG_ 2566749438 DslPrtcltFltrActvRgnrtnInhbtdDTP1 3710;
BA_ "SigType" SG_ 2566749438 DslPrtcltFltrActvRgnrtnInhbtdDTP1 4;
BA_ "SystemSignalLongSymbol" SG_ 2566749438 DslPrtcltFltrActvRgnrtnInhbtdDTP1 "DslPrtcltFltrActvRgnrtnInhbtdDTPrkngBrkNtSt";
BA_ "SPN" SG_ 2566749438 DslPrtcltFltrActvRgnrtnInhbtdDTV1 3709;
BA_ "SigType" SG_ 2566749438 DslPrtcltFltrActvRgnrtnInhbtdDTV1 4;
BA_ "SystemSignalLongSymbol" SG_ 2566749438 DslPrtcltFltrActvRgnrtnInhbtdDTV1 "DslPrtcltFltrActvRgnrtnInhbtdDTVhclSpdAbvAllwd";
BA_ "SPN" SG_ 2566749438 DslPrtcltFltrActvRgnrtnInhbtdDTO 3708;
BA_ "SigType" SG_ 2566749438 DslPrtcltFltrActvRgnrtnInhbtdDTO 4;
BA_ "SystemSignalLongSymbol" SG_ 2566749438 DslPrtcltFltrActvRgnrtnInhbtdDTO "DslPrtcltFltrActvRgnrtnInhbtdDTOtOfNtrl";
BA_ "SPN" SG_ 2566749438 DslPrtcltFltrActvRgnrtnInhbtdDTA 3707;
BA_ "SigType" SG_ 2566749438 DslPrtcltFltrActvRgnrtnInhbtdDTA 4;
BA_ "SystemSignalLongSymbol" SG_ 2566749438 DslPrtcltFltrActvRgnrtnInhbtdDTA "DslPrtcltFltrActvRgnrtnInhbtdDTAcclPdlOffIdl";
BA_ "SPN" SG_ 2566749438 DslPrtcltFltrActvRgnrtnInhbtdDTP2 3706;
BA_ "SigType" SG_ 2566749438 DslPrtcltFltrActvRgnrtnInhbtdDTP2 4;
BA_ "SystemSignalLongSymbol" SG_ 2566749438 DslPrtcltFltrActvRgnrtnInhbtdDTP2 "DslPrtcltFltrActvRgnrtnInhbtdDTPTOActv";
BA_ "SPN" SG_ 2566749438 DslPrtcltFltrActvRgnrtnInhbtdDTS2 3705;
BA_ "SigType" SG_ 2566749438 DslPrtcltFltrActvRgnrtnInhbtdDTS2 4;
BA_ "SystemSignalLongSymbol" SG_ 2566749438 DslPrtcltFltrActvRgnrtnInhbtdDTS2 "DslPrtcltFltrActvRgnrtnInhbtdDTSrvcBrkActv";
BA_ "SPN" SG_ 2566749438 DslPrtcltFltrActvRgnrtnInhbtdDTC 3704;
BA_ "SigType" SG_ 2566749438 DslPrtcltFltrActvRgnrtnInhbtdDTC 4;
BA_ "SystemSignalLongSymbol" SG_ 2566749438 DslPrtcltFltrActvRgnrtnInhbtdDTC "DslPrtcltFltrActvRgnrtnInhbtdDTCltchDsnggd";
BA_ "SPN" SG_ 2566749438 DslPrtcltFltrActvRgnrtnInhbtdDTI 3703;
BA_ "SigType" SG_ 2566749438 DslPrtcltFltrActvRgnrtnInhbtdDTI 4;
BA_ "SystemSignalLongSymbol" SG_ 2566749438 DslPrtcltFltrActvRgnrtnInhbtdDTI "DslPrtcltFltrActvRgnrtnInhbtdDTInhbtSwtch";
BA_ "SPN" SG_ 2566749438 DslPrtcltFltrActvRgnrtnInhbtdStt 3702;
BA_ "SigType" SG_ 2566749438 DslPrtcltFltrActvRgnrtnInhbtdStt 4;
BA_ "SystemSignalLongSymbol" SG_ 2566749438 DslPrtcltFltrActvRgnrtnInhbtdStt "DslPrtcltFltrActvRgnrtnInhbtdStts";
BA_ "SPN" SG_ 2566749438 DieselParticulateFilterStatus 3701;
BA_ "SigType" SG_ 2566749438 DieselParticulateFilterStatus 4;
BA_ "SPN" SG_ 2566749438 DslPrtcltFltrActvRgnrtionStatus 3700;
BA_ "SigType" SG_ 2566749438 DslPrtcltFltrActvRgnrtionStatus 4;
BA_ "SPN" SG_ 2566749438 DslPrtcltFltrPssvRgnrtionStatus 3699;
BA_ "SigType" SG_ 2566749438 DslPrtcltFltrPssvRgnrtionStatus 4;
BA_ "SPN" SG_ 2566749438 DieselParticulateFilterLampCmd 3697;
BA_ "SigType" SG_ 2566749438 DieselParticulateFilterLampCmd 4;
BA_ "SPN" SG_ 2561212158 TextDisplayIndex 3614;
BA_ "SigType" SG_ 2561212158 TextDisplayIndex 1;
BA_ "SPN" SG_ 2561212158 TextDisplayInstructions 3613;
BA_ "SigType" SG_ 2561212158 TextDisplayInstructions 4;
BA_ "SPN" SG_ 2566746366 RetractStatusOfRamp5 4457;
BA_ "SigType" SG_ 2566746366 RetractStatusOfRamp5 4;
BA_ "SPN" SG_ 2566746366 RetractStatusOfRamp4 4454;
BA_ "SigType" SG_ 2566746366 RetractStatusOfRamp4 4;
BA_ "SPN" SG_ 2566746366 MovementStatusOfRamp5 4459;
BA_ "SigType" SG_ 2566746366 MovementStatusOfRamp5 4;
BA_ "SPN" SG_ 2566746366 MovementStatusOfRamp4 4456;
BA_ "SigType" SG_ 2566746366 MovementStatusOfRamp4 4;
BA_ "SPN" SG_ 2566746366 EnableStatusOfRamp5 4458;
BA_ "SigType" SG_ 2566746366 EnableStatusOfRamp5 4;
BA_ "SPN" SG_ 2566746366 EnableStatusOfRamp4 4455;
BA_ "SigType" SG_ 2566746366 EnableStatusOfRamp4 4;
BA_ "SPN" SG_ 2566746366 MovementStatusOfRamp3 3818;
BA_ "SigType" SG_ 2566746366 MovementStatusOfRamp3 4;
BA_ "SPN" SG_ 2566746366 EnableStatusOfRamp3 3817;
BA_ "SigType" SG_ 2566746366 EnableStatusOfRamp3 4;
BA_ "SPN" SG_ 2566746366 RetractStatusOfRamp3 3816;
BA_ "SigType" SG_ 2566746366 RetractStatusOfRamp3 4;
BA_ "SPN" SG_ 2566746366 MovementStatusOfRamp2 3815;
BA_ "SigType" SG_ 2566746366 MovementStatusOfRamp2 4;
BA_ "SPN" SG_ 2566746366 EnableStatusOfRamp2 3814;
BA_ "SigType" SG_ 2566746366 EnableStatusOfRamp2 4;
BA_ "SPN" SG_ 2566746366 RetractStatusOfRamp2 3813;
BA_ "SigType" SG_ 2566746366 RetractStatusOfRamp2 4;
BA_ "SPN" SG_ 2566746366 MovementStatusOfRamp1 3812;
BA_ "SigType" SG_ 2566746366 MovementStatusOfRamp1 4;
BA_ "SPN" SG_ 2566746366 EnableStatusOfRamp1 3811;
BA_ "SigType" SG_ 2566746366 EnableStatusOfRamp1 4;
BA_ "SPN" SG_ 2566746366 RetractStatusOfRamp1 3810;
BA_ "SigType" SG_ 2566746366 RetractStatusOfRamp1 4;
BA_ "SPN" SG_ 2566750206 MaxCrankAttemptsPerStartAttempt 3670;
BA_ "SigType" SG_ 2566750206 MaxCrankAttemptsPerStartAttempt 1;
BA_ "SPN" SG_ 2566755582 EngExhstGsRcrculation1Valve2Pos 3822;
BA_ "SigType" SG_ 2566755582 EngExhstGsRcrculation1Valve2Pos 1;
BA_ "SPN" SG_ 2566755582 EngExhstGsRcirculation1ValvePos 27;
BA_ "SigType" SG_ 2566755582 EngExhstGsRcirculation1ValvePos 1;
BA_ "SPN" SG_ 2566755582 EngCrnkcsBrthrOilSeparatorSpeed 5444;
BA_ "SigType" SG_ 2566755582 EngCrnkcsBrthrOilSeparatorSpeed 1;
BA_ "SPN" SG_ 2566755582 CmdedEngIntakeManifoldPress 5312;
BA_ "SigType" SG_ 2566755582 CmdedEngIntakeManifoldPress 1;
BA_ "SPN" SG_ 2566746110 EngExhstGsRcrcltn1ClrIntkGsAbsPr 4751;
BA_ "SigType" SG_ 2566746110 EngExhstGsRcrcltn1ClrIntkGsAbsPr 1;
BA_ "SystemSignalLongSymbol" SG_ 2566746110 EngExhstGsRcrcltn1ClrIntkGsAbsPr "EngExhstGsRcrcltn1ClrIntkGsAbsPrss";
BA_ "SPN" SG_ 2566746110 EngExhstGsRcrcltn1ClrIntakeTemp 4750;
BA_ "SigType" SG_ 2566746110 EngExhstGsRcrcltn1ClrIntakeTemp 1;
BA_ "SPN" SG_ 2566746110 EngExhstGsRcrcltn1ClrEfficiency 4752;
BA_ "SigType" SG_ 2566746110 EngExhstGsRcrcltn1ClrEfficiency 1;
BA_ "SPN" SG_ 2566746110 EngExhstGsRcrclation1Valve2Ctrl 3821;
BA_ "SigType" SG_ 2566746110 EngExhstGsRcrclation1Valve2Ctrl 1;
BA_ "SPN" SG_ 2499641854 EGR1CoolerBypassActuatorPostion 3672;
BA_ "SigType" SG_ 2499641854 EGR1CoolerBypassActuatorPostion 1;
BA_ "SPN" SG_ 2566748158 EngSparkPlug4 1297;
BA_ "SigType" SG_ 2566748158 EngSparkPlug4 1;
BA_ "SPN" SG_ 2566748158 EngSparkPlug3 1296;
BA_ "SigType" SG_ 2566748158 EngSparkPlug3 1;
BA_ "SPN" SG_ 2566748158 EngSparkPlug2 1295;
BA_ "SigType" SG_ 2566748158 EngSparkPlug2 1;
BA_ "SPN" SG_ 2566748158 EngSparkPlug1 1294;
BA_ "SigType" SG_ 2566748158 EngSparkPlug1 1;
BA_ "SPN" SG_ 2566747902 EngSparkPlug8 1301;
BA_ "SigType" SG_ 2566747902 EngSparkPlug8 1;
BA_ "SPN" SG_ 2566747902 EngSparkPlug7 1300;
BA_ "SigType" SG_ 2566747902 EngSparkPlug7 1;
BA_ "SPN" SG_ 2566747902 EngSparkPlug6 1299;
BA_ "SigType" SG_ 2566747902 EngSparkPlug6 1;
BA_ "SPN" SG_ 2566747902 EngSparkPlug5 1298;
BA_ "SigType" SG_ 2566747902 EngSparkPlug5 1;
BA_ "SPN" SG_ 2566747646 EngSparkPlug12 1305;
BA_ "SigType" SG_ 2566747646 EngSparkPlug12 1;
BA_ "SPN" SG_ 2566747646 EngSparkPlug11 1304;
BA_ "SigType" SG_ 2566747646 EngSparkPlug11 1;
BA_ "SPN" SG_ 2566747646 EngSparkPlug10 1303;
BA_ "SigType" SG_ 2566747646 EngSparkPlug10 1;
BA_ "SPN" SG_ 2566747646 EngSparkPlug9 1302;
BA_ "SigType" SG_ 2566747646 EngSparkPlug9 1;
BA_ "SPN" SG_ 2566747390 EngSparkPlug16 1309;
BA_ "SigType" SG_ 2566747390 EngSparkPlug16 1;
BA_ "SPN" SG_ 2566747390 EngSparkPlug15 1308;
BA_ "SigType" SG_ 2566747390 EngSparkPlug15 1;
BA_ "SPN" SG_ 2566747390 EngSparkPlug14 1307;
BA_ "SigType" SG_ 2566747390 EngSparkPlug14 1;
BA_ "SPN" SG_ 2566747390 EngSparkPlug13 1306;
BA_ "SigType" SG_ 2566747390 EngSparkPlug13 1;
BA_ "SPN" SG_ 2566747134 EngSparkPlug20 1313;
BA_ "SigType" SG_ 2566747134 EngSparkPlug20 1;
BA_ "SPN" SG_ 2566747134 EngSparkPlug19 1312;
BA_ "SigType" SG_ 2566747134 EngSparkPlug19 1;
BA_ "SPN" SG_ 2566747134 EngSparkPlug18 1311;
BA_ "SigType" SG_ 2566747134 EngSparkPlug18 1;
BA_ "SPN" SG_ 2566747134 EngSparkPlug17 1310;
BA_ "SigType" SG_ 2566747134 EngSparkPlug17 1;
BA_ "SPN" SG_ 2566746878 EngSparkPlug24 1317;
BA_ "SigType" SG_ 2566746878 EngSparkPlug24 1;
BA_ "SPN" SG_ 2566746878 EngSparkPlug23 1316;
BA_ "SigType" SG_ 2566746878 EngSparkPlug23 1;
BA_ "SPN" SG_ 2566746878 EngSparkPlug22 1315;
BA_ "SigType" SG_ 2566746878 EngSparkPlug22 1;
BA_ "SPN" SG_ 2566746878 EngSparkPlug21 1314;
BA_ "SigType" SG_ 2566746878 EngSparkPlug21 1;
BA_ "SPN" SG_ 2561277694 LaneDepartureWarningEnableCmd 3564;
BA_ "SigType" SG_ 2561277694 LaneDepartureWarningEnableCmd 4;
BA_ "SPN" SG_ 2633861886 J2012DTCOccurrenceCount 3622;
BA_ "SPN" SG_ 2633861886 J2012DTCStatus 3621;
BA_ "SPN" SG_ 2633861886 NumberOfJ2012DTCs 3619;
BA_ "SigType" SG_ 2633861886 NumberOfJ2012DTCs 1;
BA_ "SPN" SG_ 2565873150 MessageChecksum 3690;
BA_ "SigType" SG_ 2565873150 MessageChecksum 4;
BA_ "SPN" SG_ 2565873150 MessageCounter 3689;
BA_ "SigType" SG_ 2565873150 MessageCounter 4;
BA_ "SPN" SG_ 2565873150 SteerAngleSensorCalibrated 3688;
BA_ "SigType" SG_ 2565873150 SteerAngleSensorCalibrated 4;
BA_ "SPN" SG_ 2565873150 SteerAngleSensorActiveMode 3687;
BA_ "SigType" SG_ 2565873150 SteerAngleSensorActiveMode 4;
BA_ "SPN" SG_ 2565873150 SteerWheelAngleRange 3686;
BA_ "SigType" SG_ 2565873150 SteerWheelAngleRange 1;
BA_ "SPN" SG_ 2565873150 SteerWheelAngleRangeCounterType 3685;
BA_ "SigType" SG_ 2565873150 SteerWheelAngleRangeCounterType 4;
BA_ "SPN" SG_ 2565873150 SteerWheelAngleRangeCounter 3684;
BA_ "SPN" SG_ 2565873150 SteerWheelAngle 3683;
BA_ "SigType" SG_ 2565873150 SteerWheelAngle 1;
BA_ "SPN" SG_ 2566745854 Aftrtrtmnt1SCRCtlystCnvrsnEffcnc 4364;
BA_ "SigType" SG_ 2566745854 Aftrtrtmnt1SCRCtlystCnvrsnEffcnc 1;
BA_ "SystemSignalLongSymbol" SG_ 2566745854 Aftrtrtmnt1SCRCtlystCnvrsnEffcnc "Aftrtrtmnt1SCRCtlystCnvrsnEffcncy";
BA_ "SPN" SG_ 2566745854 Aftrtrtmnt1SCRCmddCtlystRgntCnsm 3828;
BA_ "SigType" SG_ 2566745854 Aftrtrtmnt1SCRCmddCtlystRgntCnsm 1;
BA_ "SystemSignalLongSymbol" SG_ 2566745854 Aftrtrtmnt1SCRCmddCtlystRgntCnsm "Aftrtrtmnt1SCRCmddCtlystRgntCnsmptn";
BA_ "SPN" SG_ 2566745854 Aftrtrtmnt1SCRAvrgCtlystRgntCnsm 3826;
BA_ "SigType" SG_ 2566745854 Aftrtrtmnt1SCRAvrgCtlystRgntCnsm 1;
BA_ "SystemSignalLongSymbol" SG_ 2566745854 Aftrtrtmnt1SCRAvrgCtlystRgntCnsm "Aftrtrtmnt1SCRAvrgCtlystRgntCnsmptn";
BA_ "SPN" SG_ 2566745854 Aftrtrtmnt1DslExhstFldTnkLwLvlIn 5463;
BA_ "SigType" SG_ 2566745854 Aftrtrtmnt1DslExhstFldTnkLwLvlIn 1;
BA_ "SystemSignalLongSymbol" SG_ 2566745854 Aftrtrtmnt1DslExhstFldTnkLwLvlIn "Aftrtrtmnt1DslExhstFldTnkLwLvlIndctrTrvldDstnc";
BA_ "SPN" SG_ 2566751230 TransferCaseStatus 3645;
BA_ "SPN" SG_ 2566755838 TrnsTrqueConverterOilOutletTemp 3823;
BA_ "SigType" SG_ 2566755838 TrnsTrqueConverterOilOutletTemp 1;
BA_ "SPN" SG_ 2566755838 TransOverheatIndicator 5345;
BA_ "SigType" SG_ 2566755838 TransOverheatIndicator 4;
BA_ "SPN" SG_ 2566755838 TransOilLifeRemaining 4177;
BA_ "SigType" SG_ 2566755838 TransOilLifeRemaining 1;
BA_ "SPN" SG_ 2566755838 TransOilLevelSwitch 3533;
BA_ "SigType" SG_ 2566755838 TransOilLevelSwitch 4;
BA_ "SPN" SG_ 2566755838 TransOilFilterRestrictionSwitch 3359;
BA_ "SigType" SG_ 2566755838 TransOilFilterRestrictionSwitch 4;
BA_ "SPN" SG_ 2566752766 VehicleRoll 3623;
BA_ "SigType" SG_ 2566752766 VehicleRoll 1;
BA_ "SPN" SG_ 2633938942 TotalEngCruiseTime 1017;
BA_ "SigType" SG_ 2633938942 TotalEngCruiseTime 1;
BA_ "SPN" SG_ 2633938942 TotalDriveAverageLoadFactor 1016;
BA_ "SigType" SG_ 2633938942 TotalDriveAverageLoadFactor 1;
BA_ "SPN" SG_ 2633938942 TripDriveAverageLoadFactor 1015;
BA_ "SigType" SG_ 2633938942 TripDriveAverageLoadFactor 1;
BA_ "SPN" SG_ 2633938942 TripAverageEngSpeed 1014;
BA_ "SigType" SG_ 2633938942 TripAverageEngSpeed 1;
BA_ "SPN" SG_ 2633938942 TripMaxEngSpeed 1013;
BA_ "SigType" SG_ 2633938942 TripMaxEngSpeed 1;
BA_ "SPN" SG_ 2566799614 ImplementRearWorkLight 2394;
BA_ "SigType" SG_ 2566799614 ImplementRearWorkLight 4;
BA_ "SPN" SG_ 2566799614 ImplementLeftForwardWorkLight 2400;
BA_ "SigType" SG_ 2566799614 ImplementLeftForwardWorkLight 4;
BA_ "SPN" SG_ 2566799614 ImplementRightForwardWorkLight 2402;
BA_ "SigType" SG_ 2566799614 ImplementRightForwardWorkLight 4;
BA_ "SPN" SG_ 2566799614 ImplementLeftFacingWorkLight 2598;
BA_ "SigType" SG_ 2566799614 ImplementLeftFacingWorkLight 4;
BA_ "SPN" SG_ 2566799614 ImplementRightFacingWorkLight 2407;
BA_ "SigType" SG_ 2566799614 ImplementRightFacingWorkLight 4;
BA_ "SPN" SG_ 2566799614 ImplementOEMOption1Light 2396;
BA_ "SigType" SG_ 2566799614 ImplementOEMOption1Light 4;
BA_ "SPN" SG_ 2566799614 ImplementOEMOption2Light 2398;
BA_ "SigType" SG_ 2566799614 ImplementOEMOption2Light 4;
BA_ "SPN" SG_ 2566799614 TrctrFrontHighMountedWorkLights 2356;
BA_ "SigType" SG_ 2566799614 TrctrFrontHighMountedWorkLights 4;
BA_ "SPN" SG_ 2566799614 TrctorFrontLowMountedWorkLights 2354;
BA_ "SigType" SG_ 2566799614 TrctorFrontLowMountedWorkLights 4;
BA_ "SPN" SG_ 2566799614 TrctorSideHighMountedWorkLights 2366;
BA_ "SigType" SG_ 2566799614 TrctorSideHighMountedWorkLights 4;
BA_ "SPN" SG_ 2566799614 TractorSideLowMountedWorkLights 2364;
BA_ "SigType" SG_ 2566799614 TractorSideLowMountedWorkLights 4;
BA_ "SPN" SG_ 2566799614 TrctorRearHighMountedWorkLights 2362;
BA_ "SigType" SG_ 2566799614 TrctorRearHighMountedWorkLights 4;
BA_ "SPN" SG_ 2566799614 TractorRearLowMountedWorkLights 2360;
BA_ "SigType" SG_ 2566799614 TractorRearLowMountedWorkLights 4;
BA_ "SPN" SG_ 2566799614 TrctrUndersideMountedWorkLights 2358;
BA_ "SigType" SG_ 2566799614 TrctrUndersideMountedWorkLights 4;
BA_ "SPN" SG_ 2566799614 RearFogLights 2390;
BA_ "SigType" SG_ 2566799614 RearFogLights 4;
BA_ "SPN" SG_ 2566799614 TractorMarkerLight 2378;
BA_ "SigType" SG_ 2566799614 TractorMarkerLight 4;
BA_ "SPN" SG_ 2566799614 ImplementMarkerLight 2380;
BA_ "SigType" SG_ 2566799614 ImplementMarkerLight 4;
BA_ "SPN" SG_ 2566799614 TractorClearanceLight 2382;
BA_ "SigType" SG_ 2566799614 TractorClearanceLight 4;
BA_ "SPN" SG_ 2566799614 ImplementClearanceLight 2384;
BA_ "SigType" SG_ 2566799614 ImplementClearanceLight 4;
BA_ "SPN" SG_ 2566799614 LeftStopLight 2372;
BA_ "SigType" SG_ 2566799614 LeftStopLight 4;
BA_ "SPN" SG_ 2566799614 RightStopLight 2374;
BA_ "SigType" SG_ 2566799614 RightStopLight 4;
BA_ "SPN" SG_ 2566799614 CenterStopLight 2376;
BA_ "SigType" SG_ 2566799614 CenterStopLight 4;
BA_ "SPN" SG_ 2566799614 BackUpLightAndAlarmHorn 2392;
BA_ "SigType" SG_ 2566799614 BackUpLightAndAlarmHorn 4;
BA_ "SPN" SG_ 2566799614 LeftTurnSignalLights 2368;
BA_ "SigType" SG_ 2566799614 LeftTurnSignalLights 4;
BA_ "SPN" SG_ 2566799614 RightTurnSignalLights 2370;
BA_ "SigType" SG_ 2566799614 RightTurnSignalLights 4;
BA_ "SPN" SG_ 2566799614 RotatingBeaconLight 2386;
BA_ "SigType" SG_ 2566799614 RotatingBeaconLight 4;
BA_ "SPN" SG_ 2566799614 TractorFrontFogLights 2388;
BA_ "SigType" SG_ 2566799614 TractorFrontFogLights 4;
BA_ "SPN" SG_ 2566799614 HighBeamHeadLightData 2348;
BA_ "SigType" SG_ 2566799614 HighBeamHeadLightData 4;
BA_ "SPN" SG_ 2566799614 LowBeamHeadLightData 2350;
BA_ "SigType" SG_ 2566799614 LowBeamHeadLightData 4;
BA_ "SPN" SG_ 2566799614 AltBeamHeadLightData 2352;
BA_ "SigType" SG_ 2566799614 AltBeamHeadLightData 4;
BA_ "SPN" SG_ 2566799614 RunningLight 2404;
BA_ "SigType" SG_ 2566799614 RunningLight 4;
BA_ "SPN" SG_ 2365473278 ImplementRearWorkLightCmd 2405;
BA_ "SigType" SG_ 2365473278 ImplementRearWorkLightCmd 4;
BA_ "SPN" SG_ 2365473278 ImplmentLeftForwardWorkLightCmd 2399;
BA_ "SigType" SG_ 2365473278 ImplmentLeftForwardWorkLightCmd 4;
BA_ "SPN" SG_ 2365473278 ImplmntRightForwardWorkLightCmd 2401;
BA_ "SigType" SG_ 2365473278 ImplmntRightForwardWorkLightCmd 4;
BA_ "SPN" SG_ 2365473278 LightingDataRqCmd 2393;
BA_ "SigType" SG_ 2365473278 LightingDataRqCmd 4;
BA_ "SPN" SG_ 2365473278 ImplementLeftFacingWorkLightCmd 2597;
BA_ "SigType" SG_ 2365473278 ImplementLeftFacingWorkLightCmd 4;
BA_ "SPN" SG_ 2365473278 ImplmentRightFacingWorkLightCmd 2406;
BA_ "SigType" SG_ 2365473278 ImplmentRightFacingWorkLightCmd 4;
BA_ "SPN" SG_ 2365473278 ImplementOEMOption1LightCmd 2395;
BA_ "SigType" SG_ 2365473278 ImplementOEMOption1LightCmd 4;
BA_ "SPN" SG_ 2365473278 ImplementOEMOption2LightCmd 2397;
BA_ "SigType" SG_ 2365473278 ImplementOEMOption2LightCmd 4;
BA_ "SPN" SG_ 2365473278 TrctrFrntHghMuntedWorkLightsCmd 2355;
BA_ "SigType" SG_ 2365473278 TrctrFrntHghMuntedWorkLightsCmd 4;
BA_ "SPN" SG_ 2365473278 TrctrFrntLwMountedWorkLightsCmd 2353;
BA_ "SigType" SG_ 2365473278 TrctrFrntLwMountedWorkLightsCmd 4;
BA_ "SPN" SG_ 2365473278 TrctrSdHighMountedWorkLightsCmd 2365;
BA_ "SigType" SG_ 2365473278 TrctrSdHighMountedWorkLightsCmd 4;
BA_ "SPN" SG_ 2365473278 TrctrSdeLowMountedWorkLightsCmd 2363;
BA_ "SigType" SG_ 2365473278 TrctrSdeLowMountedWorkLightsCmd 4;
BA_ "SPN" SG_ 2365473278 TrctrRrHighMountedWorkLightsCmd 2361;
BA_ "SigType" SG_ 2365473278 TrctrRrHighMountedWorkLightsCmd 4;
BA_ "SPN" SG_ 2365473278 TrctrRarLowMountedWorkLightsCmd 2359;
BA_ "SigType" SG_ 2365473278 TrctrRarLowMountedWorkLightsCmd 4;
BA_ "SPN" SG_ 2365473278 TrctrUndrsdMountedWorkLightsCmd 2357;
BA_ "SigType" SG_ 2365473278 TrctrUndrsdMountedWorkLightsCmd 4;
BA_ "SPN" SG_ 2365473278 RearFogLightCmd 2389;
BA_ "SigType" SG_ 2365473278 RearFogLightCmd 4;
BA_ "SPN" SG_ 2365473278 TractorMarkerLightCmd 2377;
BA_ "SigType" SG_ 2365473278 TractorMarkerLightCmd 4;
BA_ "SPN" SG_ 2365473278 ImplementMarkerLightCmd 2379;
BA_ "SigType" SG_ 2365473278 ImplementMarkerLightCmd 4;
BA_ "SPN" SG_ 2365473278 TractorClearanceLightCmd 2381;
BA_ "SigType" SG_ 2365473278 TractorClearanceLightCmd 4;
BA_ "SPN" SG_ 2365473278 ImplementClearanceLightCmd 2383;
BA_ "SigType" SG_ 2365473278 ImplementClearanceLightCmd 4;
BA_ "SPN" SG_ 2365473278 LeftStopLightCmd 2371;
BA_ "SigType" SG_ 2365473278 LeftStopLightCmd 4;
BA_ "SPN" SG_ 2365473278 RightStopLightCmd 2373;
BA_ "SigType" SG_ 2365473278 RightStopLightCmd 4;
BA_ "SPN" SG_ 2365473278 CenterStopLightCmd 2375;
BA_ "SigType" SG_ 2365473278 CenterStopLightCmd 4;
BA_ "SPN" SG_ 2365473278 BackUpLightAndAlarmHornCmd 2391;
BA_ "SigType" SG_ 2365473278 BackUpLightAndAlarmHornCmd 4;
BA_ "SPN" SG_ 2365473278 LeftTurnSignalLightsCmd 2367;
BA_ "SigType" SG_ 2365473278 LeftTurnSignalLightsCmd 4;
BA_ "SPN" SG_ 2365473278 RightTurnSignalLightsCmd 2369;
BA_ "SigType" SG_ 2365473278 RightTurnSignalLightsCmd 4;
BA_ "SPN" SG_ 2365473278 RotatingBeaconLightCmd 2385;
BA_ "SigType" SG_ 2365473278 RotatingBeaconLightCmd 4;
BA_ "SPN" SG_ 2365473278 TractorFrontFogLightsCmd 2387;
BA_ "SigType" SG_ 2365473278 TractorFrontFogLightsCmd 4;
BA_ "SPN" SG_ 2365473278 HighBeamHeadLightCmd 2347;
BA_ "SigType" SG_ 2365473278 HighBeamHeadLightCmd 4;
BA_ "SPN" SG_ 2365473278 LowBeamHeadLightCmd 2349;
BA_ "SigType" SG_ 2365473278 LowBeamHeadLightCmd 4;
BA_ "SPN" SG_ 2365473278 AltBeamHeadLightCmd 2351;
BA_ "SigType" SG_ 2365473278 AltBeamHeadLightCmd 4;
BA_ "SPN" SG_ 2365473278 RunningLightCmd 2403;
BA_ "SigType" SG_ 2365473278 RunningLightCmd 4;
BA_ "SPN" SG_ 2365485822 BladeCtrlMode 1578;
BA_ "SigType" SG_ 2365485822 BladeCtrlMode 1;
BA_ "SPN" SG_ 2365485822 BladeDurationAndDirection 1577;
BA_ "SigType" SG_ 2365485822 BladeDurationAndDirection 1;
BA_ "SPN" SG_ 2365485822 LandLevelingSystemEnableStatus 5409;
BA_ "SigType" SG_ 2365485822 LandLevelingSystemEnableStatus 4;
BA_ "SPN" SG_ 2365485822 BladeCtrlModeRight 5408;
BA_ "SigType" SG_ 2365485822 BladeCtrlModeRight 4;
BA_ "SPN" SG_ 2365485822 BladeCtrlModeLeft 5407;
BA_ "SigType" SG_ 2365485822 BladeCtrlModeLeft 4;
BA_ "SPN" SG_ 2633926654 EngActualIgntTiming 1436;
BA_ "SigType" SG_ 2633926654 EngActualIgntTiming 1;
BA_ "SPN" SG_ 2633926654 EngDesiredIgntTiming3 1435;
BA_ "SigType" SG_ 2633926654 EngDesiredIgntTiming3 1;
BA_ "SPN" SG_ 2633926654 EngDesiredIgntTiming2 1434;
BA_ "SigType" SG_ 2633926654 EngDesiredIgntTiming2 1;
BA_ "SPN" SG_ 2633926654 EngDesiredIgntTiming1 1433;
BA_ "SigType" SG_ 2633926654 EngDesiredIgntTiming1 1;
BA_ "SPN" SG_ 2633926398 EngCyl20IgntTiming 1432;
BA_ "SigType" SG_ 2633926398 EngCyl20IgntTiming 1;
BA_ "SPN" SG_ 2633926398 EngCyl19IgntTiming 1431;
BA_ "SigType" SG_ 2633926398 EngCyl19IgntTiming 1;
BA_ "SPN" SG_ 2633926398 EngCyl18IgntTiming 1430;
BA_ "SigType" SG_ 2633926398 EngCyl18IgntTiming 1;
BA_ "SPN" SG_ 2633926398 EngCyl17IgntTiming 1429;
BA_ "SigType" SG_ 2633926398 EngCyl17IgntTiming 1;
BA_ "SPN" SG_ 2633926142 EngCyl16IgntTiming 1428;
BA_ "SigType" SG_ 2633926142 EngCyl16IgntTiming 1;
BA_ "SPN" SG_ 2633926142 EngCyl15IgntTiming 1427;
BA_ "SigType" SG_ 2633926142 EngCyl15IgntTiming 1;
BA_ "SPN" SG_ 2633926142 EngCyl14IgntTiming 1426;
BA_ "SigType" SG_ 2633926142 EngCyl14IgntTiming 1;
BA_ "SPN" SG_ 2633926142 EngCyl13IgntTiming 1425;
BA_ "SigType" SG_ 2633926142 EngCyl13IgntTiming 1;
BA_ "SPN" SG_ 2633925886 EngCyl12IgntTiming 1424;
BA_ "SigType" SG_ 2633925886 EngCyl12IgntTiming 1;
BA_ "SPN" SG_ 2633925886 EngCyl11IgntTiming 1423;
BA_ "SigType" SG_ 2633925886 EngCyl11IgntTiming 1;
BA_ "SPN" SG_ 2633925886 EngCyl10IgntTiming 1422;
BA_ "SigType" SG_ 2633925886 EngCyl10IgntTiming 1;
BA_ "SPN" SG_ 2633925886 EngCyl9IgntTiming 1421;
BA_ "SigType" SG_ 2633925886 EngCyl9IgntTiming 1;
BA_ "SPN" SG_ 2633925630 EngCyl8IgntTiming 1420;
BA_ "SigType" SG_ 2633925630 EngCyl8IgntTiming 1;
BA_ "SPN" SG_ 2633925630 EngCyl7IgntTiming 1419;
BA_ "SigType" SG_ 2633925630 EngCyl7IgntTiming 1;
BA_ "SPN" SG_ 2633925630 EngCyl6IgntTiming 1418;
BA_ "SigType" SG_ 2633925630 EngCyl6IgntTiming 1;
BA_ "SPN" SG_ 2633925630 EngCyl5IgntTiming 1417;
BA_ "SigType" SG_ 2633925630 EngCyl5IgntTiming 1;
BA_ "SPN" SG_ 2633925374 EngCyl4IgntTiming 1416;
BA_ "SigType" SG_ 2633925374 EngCyl4IgntTiming 1;
BA_ "SPN" SG_ 2633925374 EngCyl3IgntTiming 1415;
BA_ "SigType" SG_ 2633925374 EngCyl3IgntTiming 1;
BA_ "SPN" SG_ 2633925374 EngCyl2IgntTiming 1414;
BA_ "SigType" SG_ 2633925374 EngCyl2IgntTiming 1;
BA_ "SPN" SG_ 2633925374 EngCyl1IgntTiming 1413;
BA_ "SigType" SG_ 2633925374 EngCyl1IgntTiming 1;
BA_ "SPN" SG_ 2633927422 EngCyl20IgntTransSecondOutput 1412;
BA_ "SigType" SG_ 2633927422 EngCyl20IgntTransSecondOutput 1;
BA_ "SPN" SG_ 2633927422 EngCyl19IgntTransSecondOutput 1411;
BA_ "SigType" SG_ 2633927422 EngCyl19IgntTransSecondOutput 1;
BA_ "SPN" SG_ 2633927422 EngCyl18IgntTransSecondOutput 1410;
BA_ "SigType" SG_ 2633927422 EngCyl18IgntTransSecondOutput 1;
BA_ "SPN" SG_ 2633927422 EngCyl17IgntTransSecondOutput 1409;
BA_ "SigType" SG_ 2633927422 EngCyl17IgntTransSecondOutput 1;
BA_ "SPN" SG_ 2633927166 EngCyl16IgntTransSecondOutput 1408;
BA_ "SigType" SG_ 2633927166 EngCyl16IgntTransSecondOutput 1;
BA_ "SPN" SG_ 2633927166 EngCyl15IgntTransSecondOutput 1407;
BA_ "SigType" SG_ 2633927166 EngCyl15IgntTransSecondOutput 1;
BA_ "SPN" SG_ 2633927166 EngCyl14IgntTransSecondOutput 1406;
BA_ "SigType" SG_ 2633927166 EngCyl14IgntTransSecondOutput 1;
BA_ "SPN" SG_ 2633927166 EngCyl13IgntTransSecondOutput 1405;
BA_ "SigType" SG_ 2633927166 EngCyl13IgntTransSecondOutput 1;
BA_ "SPN" SG_ 2633927166 EngCyl12IgntTransSecondOutput 1404;
BA_ "SigType" SG_ 2633927166 EngCyl12IgntTransSecondOutput 1;
BA_ "SPN" SG_ 2633927166 EngCyl11IgntTransSecondOutput 1403;
BA_ "SigType" SG_ 2633927166 EngCyl11IgntTransSecondOutput 1;
BA_ "SPN" SG_ 2633927166 EngCyl10IgntTransSecondOutput 1402;
BA_ "SigType" SG_ 2633927166 EngCyl10IgntTransSecondOutput 1;
BA_ "SPN" SG_ 2633927166 EngCyl9IgntTransSecondOutput 1401;
BA_ "SigType" SG_ 2633927166 EngCyl9IgntTransSecondOutput 1;
BA_ "SPN" SG_ 2633926910 EngCyl8IgntTransSecondOutput 1400;
BA_ "SigType" SG_ 2633926910 EngCyl8IgntTransSecondOutput 1;
BA_ "SPN" SG_ 2633926910 EngCyl7IgntTransSecondOutput 1399;
BA_ "SigType" SG_ 2633926910 EngCyl7IgntTransSecondOutput 1;
BA_ "SPN" SG_ 2633926910 EngCyl6IgntTransSecondOutput 1398;
BA_ "SigType" SG_ 2633926910 EngCyl6IgntTransSecondOutput 1;
BA_ "SPN" SG_ 2633926910 EngCyl5IgntTransSecondOutput 1397;
BA_ "SigType" SG_ 2633926910 EngCyl5IgntTransSecondOutput 1;
BA_ "SPN" SG_ 2633926910 EngCyl4IgntTransSecondOutput 1396;
BA_ "SigType" SG_ 2633926910 EngCyl4IgntTransSecondOutput 1;
BA_ "SPN" SG_ 2633926910 EngCyl3IgntTransSecondOutput 1395;
BA_ "SigType" SG_ 2633926910 EngCyl3IgntTransSecondOutput 1;
BA_ "SPN" SG_ 2633926910 EngCyl2IgntTransSecondOutput 1394;
BA_ "SigType" SG_ 2633926910 EngCyl2IgntTransSecondOutput 1;
BA_ "SPN" SG_ 2633926910 EngCyl1IgntTransSecondOutput 1393;
BA_ "SigType" SG_ 2633926910 EngCyl1IgntTransSecondOutput 1;
BA_ "SPN" SG_ 2566768894 EngOprtrPrmryIntrmdtSpdSlctStte 2892;
BA_ "SigType" SG_ 2566768894 EngOprtrPrmryIntrmdtSpdSlctStte 4;
BA_ "SPN" SG_ 2566769406 EngOprtrPrmryIntrmdtSpeedSelect 2880;
BA_ "SigType" SG_ 2566769406 EngOprtrPrmryIntrmdtSpeedSelect 4;
BA_ "SPN" SG_ 2566839550 EngTotalIdleHours 235;
BA_ "SigType" SG_ 2566839550 EngTotalIdleHours 1;
BA_ "SPN" SG_ 2566839550 EngTotalIdleFuelUsed 236;
BA_ "SigType" SG_ 2566839550 EngTotalIdleFuelUsed 1;
BA_ "SPN" SG_ 2633934334 EngIntakeManifold6Temp 1803;
BA_ "SigType" SG_ 2633934334 EngIntakeManifold6Temp 1;
BA_ "SPN" SG_ 2633934334 EngIntakeManifold5Temp 1802;
BA_ "SigType" SG_ 2633934334 EngIntakeManifold5Temp 1;
BA_ "SPN" SG_ 2633934334 EngIntakeManifold4Temp 1133;
BA_ "SigType" SG_ 2633934334 EngIntakeManifold4Temp 1;
BA_ "SPN" SG_ 2633934334 EngIntakeManifold3Temp 1132;
BA_ "SigType" SG_ 2633934334 EngIntakeManifold3Temp 1;
BA_ "SPN" SG_ 2633934334 EngIntakeManifold2Temp 1131;
BA_ "SigType" SG_ 2633934334 EngIntakeManifold2Temp 1;
BA_ "SPN" SG_ 2566825726 EngTurbo4BoostPress 1130;
BA_ "SigType" SG_ 2566825726 EngTurbo4BoostPress 1;
BA_ "SPN" SG_ 2566825726 EngTurbo3BoostPress 1129;
BA_ "SigType" SG_ 2566825726 EngTurbo3BoostPress 1;
BA_ "SPN" SG_ 2566825726 EngTurbo2BoostPress 1128;
BA_ "SigType" SG_ 2566825726 EngTurbo2BoostPress 1;
BA_ "SPN" SG_ 2566825726 EngTurbo1BoostPress 1127;
BA_ "SigType" SG_ 2566825726 EngTurbo1BoostPress 1;
BA_ "SPN" SG_ 2566770942 EngAirFilter4DiffPress 2811;
BA_ "SigType" SG_ 2566770942 EngAirFilter4DiffPress 1;
BA_ "SPN" SG_ 2566770942 EngAirFilter3DiffPress 2810;
BA_ "SigType" SG_ 2566770942 EngAirFilter3DiffPress 1;
BA_ "SPN" SG_ 2566770942 EngAirFilter2DiffPress 2809;
BA_ "SigType" SG_ 2566770942 EngAirFilter2DiffPress 1;
BA_ "SPN" SG_ 2566770942 EngIntakeManifold1AbsPress 4817;
BA_ "SigType" SG_ 2566770942 EngIntakeManifold1AbsPress 1;
BA_ "SPN" SG_ 2566770942 EngIntakeManifold2AbsPress 5422;
BA_ "SigType" SG_ 2566770942 EngIntakeManifold2AbsPress 1;
BA_ "SPN" SG_ 2566770942 EngIntakeManifold2Press 3562;
BA_ "SigType" SG_ 2566770942 EngIntakeManifold2Press 1;
BA_ "SPN" SG_ 2566770942 EngIntakeManifold1AbsPressHiRes 4817;
BA_ "SigType" SG_ 2566770942 EngIntakeManifold1AbsPressHiRes 1;
BA_ "SPN" SG_ 2566846206 EngCoolantFilterDiffPress 112;
BA_ "SigType" SG_ 2566846206 EngCoolantFilterDiffPress 1;
BA_ "SPN" SG_ 2566846206 EngExhaustGasTemp 173;
BA_ "SigType" SG_ 2566846206 EngExhaustGasTemp 1;
BA_ "SPN" SG_ 2566846206 EngAirFilter1DiffPress 107;
BA_ "SigType" SG_ 2566846206 EngAirFilter1DiffPress 1;
BA_ "SPN" SG_ 2566846206 EngIntakeManifold1Temp 105;
BA_ "SigType" SG_ 2566846206 EngIntakeManifold1Temp 1;
BA_ "SPN" SG_ 2566846206 EngIntakeManifold1Press 102;
BA_ "SigType" SG_ 2566846206 EngIntakeManifold1Press 1;
BA_ "SPN" SG_ 2566846206 EngDslPrtclateFilterIntakePress 81;
BA_ "SigType" SG_ 2566846206 EngDslPrtclateFilterIntakePress 1;
BA_ "SPN" SG_ 2566846206 EngAirIntakePress 106;
BA_ "SigType" SG_ 2566846206 EngAirIntakePress 1;
BA_ "SPN" SG_ 2566811134 CabHeatingZone 1680;
BA_ "SigType" SG_ 2566811134 CabHeatingZone 4;
BA_ "SPN" SG_ 2566811134 EngHeatingZone 1679;
BA_ "SigType" SG_ 2566811134 EngHeatingZone 4;
BA_ "SPN" SG_ 2566811134 CabVentilation 1678;
BA_ "SigType" SG_ 2566811134 CabVentilation 4;
BA_ "SPN" SG_ 2566811134 AuxHeaterMode 1677;
BA_ "SigType" SG_ 2566811134 AuxHeaterMode 4;
BA_ "SPN" SG_ 2566811134 AuxHeaterOutputPowerPercent 1689;
BA_ "SigType" SG_ 2566811134 AuxHeaterOutputPowerPercent 1;
BA_ "SPN" SG_ 2566811134 AuxHeaterInputAirTemp 1688;
BA_ "SigType" SG_ 2566811134 AuxHeaterInputAirTemp 1;
BA_ "SPN" SG_ 2566811134 AuxHeaterOutputCoolantTemp 1687;
BA_ "SigType" SG_ 2566811134 AuxHeaterOutputCoolantTemp 1;
BA_ "SPN" SG_ 2566811134 AuxHeaterWaterPumpStatus 1676;
BA_ "SigType" SG_ 2566811134 AuxHeaterWaterPumpStatus 4;
BA_ "SPN" SG_ 2298375934 RearAxleRightWheelSpeed 1595;
BA_ "SigType" SG_ 2298375934 RearAxleRightWheelSpeed 1;
BA_ "SPN" SG_ 2298375934 RearAxleLeftWheelSpeed 1594;
BA_ "SigType" SG_ 2298375934 RearAxleLeftWheelSpeed 1;
BA_ "SPN" SG_ 2298375934 FrontAxleRightWheelSpeed 1593;
BA_ "SigType" SG_ 2298375934 FrontAxleRightWheelSpeed 1;
BA_ "SPN" SG_ 2298375934 FrontAxleLeftWheelSpeed 1592;
BA_ "SigType" SG_ 2298375934 FrontAxleLeftWheelSpeed 1;
BA_ "SPN" SG_ 2565867774 FireApparatusPumpEngagement 2599;
BA_ "SigType" SG_ 2565867774 FireApparatusPumpEngagement 4;
BA_ "SPN" SG_ 2565867774 EngHydPressGovernorSwitch 1764;
BA_ "SigType" SG_ 2565867774 EngHydPressGovernorSwitch 4;
BA_ "SPN" SG_ 2565867774 EngHydPrssGovernorModeIndicator 1763;
BA_ "SigType" SG_ 2565867774 EngHydPrssGovernorModeIndicator 4;
BA_ "SPN" SG_ 2565867774 HydPress 1762;
BA_ "SigType" SG_ 2565867774 HydPress 1;
BA_ "SPN" SG_ 2566841854 EngTotalRevolutions 249;
BA_ "SigType" SG_ 2566841854 EngTotalRevolutions 1;
BA_ "SPN" SG_ 2566841854 EngTotalHoursOfOperation 247;
BA_ "SigType" SG_ 2566841854 EngTotalHoursOfOperation 1;
BA_ "SPN" SG_ 2365449982 HydBrakeFluidLevelSwitch 2931;
BA_ "SigType" SG_ 2365449982 HydBrakeFluidLevelSwitch 4;
BA_ "SPN" SG_ 2365449982 HydBrakeSystemAudibleWarningCmd 2930;
BA_ "SigType" SG_ 2365449982 HydBrakeSystemAudibleWarningCmd 4;
BA_ "SPN" SG_ 2365449982 HydBrkePressSupplyStateCircuit2 2583;
BA_ "SigType" SG_ 2365449982 HydBrkePressSupplyStateCircuit2 4;
BA_ "SPN" SG_ 2365449982 HydBrkePressSupplyStateCircuit1 2582;
BA_ "SigType" SG_ 2365449982 HydBrkePressSupplyStateCircuit1 4;
BA_ "SPN" SG_ 2365449982 HydBrkPressWarningStateCircuit2 2585;
BA_ "SigType" SG_ 2365449982 HydBrkPressWarningStateCircuit2 4;
BA_ "SPN" SG_ 2365449982 HydBrkPressWarningStateCircuit1 2584;
BA_ "SigType" SG_ 2365449982 HydBrkPressWarningStateCircuit1 4;
BA_ "SPN" SG_ 2365449982 HydBrakePressCircuit2 2581;
BA_ "SigType" SG_ 2365449982 HydBrakePressCircuit2 1;
BA_ "SPN" SG_ 2365449982 HydBrakePressCircuit1 2580;
BA_ "SigType" SG_ 2365449982 HydBrakePressCircuit1 1;
BA_ "SPN" SG_ 2633939198 TripDriveFuelEconomy 1012;
BA_ "SigType" SG_ 2633939198 TripDriveFuelEconomy 1;
BA_ "SPN" SG_ 2633939198 TrpPTOGovernorNonmovingFuelUsed 1009;
BA_ "SigType" SG_ 2633939198 TrpPTOGovernorNonmovingFuelUsed 1;
BA_ "SPN" SG_ 2633939198 TripVehicleIdleFuelUsed 1010;
BA_ "SigType" SG_ 2633939198 TripVehicleIdleFuelUsed 1;
BA_ "SPN" SG_ 2633939198 TripCruiseFuelUsed 1011;
BA_ "SigType" SG_ 2633939198 TripCruiseFuelUsed 1;
BA_ "SPN" SG_ 2633939198 TripDriveFuelUsed 1007;
BA_ "SigType" SG_ 2633939198 TripDriveFuelUsed 1;
BA_ "SPN" SG_ 2633939198 TripPTOGovernorMovingFuelUsed 1008;
BA_ "SigType" SG_ 2633939198 TripPTOGovernorMovingFuelUsed 1;
BA_ "SPN" SG_ 2633927678 EngFuelValve1OutletAbsPress 2980;
BA_ "SigType" SG_ 2633927678 EngFuelValve1OutletAbsPress 1;
BA_ "SPN" SG_ 2633927678 EngAirToFuelDiffPress 1392;
BA_ "SigType" SG_ 2633927678 EngAirToFuelDiffPress 1;
BA_ "SPN" SG_ 2633927678 EngFuelValveDiffPress 1391;
BA_ "SigType" SG_ 2633927678 EngFuelValveDiffPress 1;
BA_ "SPN" SG_ 2633927678 EngFuelValve1IntakeAbsPress 1390;
BA_ "SigType" SG_ 2633927678 EngFuelValve1IntakeAbsPress 1;
BA_ "SPN" SG_ 2633925118 EngFuelFlowRate2 1441;
BA_ "SigType" SG_ 2633925118 EngFuelFlowRate2 1;
BA_ "SPN" SG_ 2633925118 EngFuelFlowRate1 1440;
BA_ "SigType" SG_ 2633925118 EngFuelFlowRate1 1;
BA_ "SPN" SG_ 2633925118 EngRqedFuelValve2Pos 1766;
BA_ "SigType" SG_ 2633925118 EngRqedFuelValve2Pos 1;
BA_ "SPN" SG_ 2633925118 EngRqedFuelValve1Pos 1765;
BA_ "SigType" SG_ 2633925118 EngRqedFuelValve1Pos 1;
BA_ "SPN" SG_ 2633925118 EngFuelValve2Pos 1443;
BA_ "SigType" SG_ 2633925118 EngFuelValve2Pos 1;
BA_ "SPN" SG_ 2633925118 EngFuelValve1Pos 1442;
BA_ "SigType" SG_ 2633925118 EngFuelValve1Pos 1;
BA_ "SPN" SG_ 2633937662 TotalEngPTOGovernorFuelUsed 1030;
BA_ "SigType" SG_ 2633937662 TotalEngPTOGovernorFuelUsed 1;
BA_ "SPN" SG_ 2633937662 TripAverageFuelRate 1031;
BA_ "SigType" SG_ 2633937662 TripAverageFuelRate 1;
BA_ "SPN" SG_ 2633937662 EngFuelSpecificGravity 1389;
BA_ "SigType" SG_ 2633937662 EngFuelSpecificGravity 1;
BA_ "SPN" SG_ 2566804990 SpecificHeatRatio 1767;
BA_ "SigType" SG_ 2566804990 SpecificHeatRatio 1;

VAL_ 2358902526 Joystick3Lamp10Cmd 0 "Off" 1 "On" 2 "Blinking" 3 "NotAvailableNotInstalled";
VAL_ 2358902526 Joystick3Lamp9Cmd 0 "Off" 1 "On" 2 "Blinking" 3 "NotAvailableNotInstalled";
VAL_ 2358902526 Joystick3Lamp8Cmd 0 "Off" 1 "On" 2 "Blinking" 3 "NotAvailableNotInstalled";
VAL_ 2358902526 Joystick3Lamp7Cmd 0 "Off" 1 "On" 2 "Blinking" 3 "NotAvailableNotInstalled";
VAL_ 2358902526 Joystick3Lamp6Cmd 0 "Off" 1 "On" 2 "Blinking" 3 "NotAvailableNotInstalled";
VAL_ 2358902526 Joystick3Lamp5Cmd 0 "Off" 1 "On" 2 "Blinking" 3 "NotAvailableNotInstalled";
VAL_ 2358902526 Joystick3Lamp4Cmd 0 "Off" 1 "On" 2 "Blinking" 3 "NotAvailableNotInstalled";
VAL_ 2358902526 Joystick3Lamp3Cmd 0 "Off" 1 "On" 2 "Blinking" 3 "NotAvailableNotInstalled";
VAL_ 2358902526 Joystick3Lamp2Cmd 0 "Off" 1 "On" 2 "Blinking" 3 "NotAvailableNotInstalled";
VAL_ 2358902526 Joystick3Lamp1Cmd 0 "Off" 1 "On" 2 "Blinking" 3 "NotAvailableNotInstalled";
VAL_ 2358902526 Joystick2Lamp10Cmd 0 "Off" 1 "On" 2 "Blinking" 3 "NotAvailableNotInstalled";
VAL_ 2358902526 Joystick2Lamp9Cmd 0 "Off" 1 "On" 2 "Blinking" 3 "NotAvailableNotInstalled";
VAL_ 2358902526 Joystick2Lamp8Cmd 0 "Off" 1 "On" 2 "Blinking" 3 "NotAvailableNotInstalled";
VAL_ 2358902526 Joystick2Lamp7Cmd 0 "Off" 1 "On" 2 "Blinking" 3 "NotAvailableNotInstalled";
VAL_ 2358902526 Joystick2Lamp6Cmd 0 "Off" 1 "On" 2 "Blinking" 3 "NotAvailableNotInstalled";
VAL_ 2358902526 Joystick2Lamp5Cmd 0 "Off" 1 "On" 2 "Blinking" 3 "NotAvailableNotInstalled";
VAL_ 2358902526 Joystick2Lamp4Cmd 0 "Off" 1 "On" 2 "Blinking" 3 "NotAvailableNotInstalled";
VAL_ 2358902526 Joystick2Lamp3Cmd 0 "Off" 1 "On" 2 "Blinking" 3 "NotAvailableNotInstalled";
VAL_ 2358902526 Joystick2Lamp2Cmd 0 "Off" 1 "On" 2 "Blinking" 3 "NotAvailableNotInstalled";
VAL_ 2358902526 Joystick2Lamp1Cmd 0 "Off" 1 "On" 2 "Blinking" 3 "NotAvailableNotInstalled";
VAL_ 2358902526 Joystick1Lamp10Cmd 0 "Off" 1 "On" 2 "Blinking" 3 "NotAvailableNotInstalled";
VAL_ 2358902526 Joystick1Lamp9Cmd 0 "Off" 1 "On" 2 "Blinking" 3 "NotAvailableNotInstalled";
VAL_ 2358902526 Joystick1Lamp8Cmd 0 "Off" 1 "On" 2 "Blinking" 3 "NotAvailableNotInstalled";
VAL_ 2358902526 Joystick1Lamp7Cmd 0 "Off" 1 "On" 2 "Blinking" 3 "NotAvailableNotInstalled";
VAL_ 2358902526 Joystick1Lamp6Cmd 0 "Off" 1 "On" 2 "Blinking" 3 "NotAvailableNotInstalled";
VAL_ 2358902526 Joystick1Lamp5Cmd 0 "Off" 1 "On" 2 "Blinking" 3 "NotAvailableNotInstalled";
VAL_ 2358902526 Joystick1Lamp4Cmd 0 "Off" 1 "On" 2 "Blinking" 3 "NotAvailableNotInstalled";
VAL_ 2358902526 Joystick1Lamp3Cmd 0 "Off" 1 "On" 2 "Blinking" 3 "NotAvailableNotInstalled";
VAL_ 2358902526 Joystick1Lamp2Cmd 0 "Off" 1 "On" 2 "Blinking" 3 "NotAvailableNotInstalled";
VAL_ 2358902526 Joystick1Lamp1Cmd 0 "Off" 1 "On" 2 "Blinking" 3 "NotAvailableNotInstalled";
VAL_ 2365400574 Jystck9GripXAxisDetentPosStatus 0 "NotInDetentPos" 1 "InDetentPos" 2 "ErrorIndicator" 3 "NotAvailable";
VAL_ 2365400574 Jystck9GripYAxisDetentPosStatus 0 "NotInDetentPos" 1 "InDetentPos" 2 "ErrorIndicator" 3 "NotAvailable";
VAL_ 2365400574 Jystck9ThetaAxisDetentPosStatus 0 "NotInDetentPos" 1 "InDetentPos" 2 "ErrorIndicator" 3 "NotAvailable";
VAL_ 2365400574 Jystck9ThtAxsClckwsPstvPsStatus 0 "NotOnPositiveSideOfNeutral" 1 "OnPositiveSideOfNeutral" 2 "ErrorIndicator" 3 "NotAvailable";
VAL_ 2365400574 Jystck9ThtAxsCntrClckwsNgtvPsStt 0 "NotOnNegativeSideOfNeutral" 1 "OnNegativeSideOfNeutral" 2 "ErrorIndicator" 3 "NotAvailable";
VAL_ 2365400574 Jystck9ThtaAxisNeutralPosStatus 0 "NotInNeutralPos" 1 "InNeutralPos" 2 "ErrorIndicator" 3 "NotAvailable";
VAL_ 2365400574 Jystck9GrpYAxsLvrFrwrdPstvPsStts 0 "NotOnPositiveSideOfNeutral" 1 "OnPositiveSideOfNeutral" 2 "ErrorIndicator" 3 "NotAvailable";
VAL_ 2365400574 Jystck9GrpYAxsLvrBckNgtvPsSttus 0 "NotOnNegativeSideOfNeutral" 1 "OnNegativeSideOfNeutral" 2 "ErrorIndicator" 3 "NotAvailable";
VAL_ 2365400574 Jystck9GrpYAxisNeutralPosStatus 0 "NotInNeutralPos" 1 "InNeutralPos" 2 "ErrorIndicator" 3 "NotAvailable";
VAL_ 2365400574 Jystck9GrpXAxsLvrRghtPstvPsStts 0 "NotOnPositiveSideOfNeutral" 1 "OnPositiveSideOfNeutral" 2 "ErrorIndicator" 3 "NotAvailable";
VAL_ 2365400574 Jystck9GrpXAxsLvrLftNgtvPsSttus 0 "NotOnNegativeSideOfNeutral" 1 "OnNegativeSideOfNeutral" 2 "ErrorIndicator" 3 "NotAvailable";
VAL_ 2365400574 Jystck9GrpXAxisNeutralPosStatus 0 "NotInNeutralPos" 1 "InNeutralPos" 2 "ErrorIndicator" 3 "NotAvailable";
VAL_ 2365401086 Jystck8GripXAxisDetentPosStatus 0 "NotInDetentPos" 1 "InDetentPos" 2 "ErrorIndicator" 3 "NotAvailable";
VAL_ 2365401086 Jystck8GripYAxisDetentPosStatus 0 "NotInDetentPos" 1 "InDetentPos" 2 "ErrorIndicator" 3 "NotAvailable";
VAL_ 2365401086 Jystck8ThetaAxisDetentPosStatus 0 "NotInDetentPos" 1 "InDetentPos" 2 "ErrorIndicator" 3 "NotAvailable";
VAL_ 2365401086 Jystck8ThtAxsClckwsPstvPsStatus 0 "NotOnPositiveSideOfNeutral" 1 "OnPositiveSideOfNeutral" 2 "ErrorIndicator" 3 "NotAvailable";
VAL_ 2365401086 Jystck8ThtAxsCntrClckwsNgtvPsStt 0 "NotOnNegativeSideOfNeutral" 1 "OnNegativeSideOfNeutral" 2 "ErrorIndicator" 3 "NotAvailable";
VAL_ 2365401086 Jystck8ThtaAxisNeutralPosStatus 0 "NotInNeutralPos" 1 "InNeutralPos" 2 "ErrorIndicator" 3 "NotAvailable";
VAL_ 2365401086 Jystck8GrpYAxsLvrFrwrdPstvPsStts 0 "NotOnPositiveSideOfNeutral" 1 "OnPositiveSideOfNeutral" 2 "ErrorIndicator" 3 "NotAvailable";
VAL_ 2365401086 Jystck8GrpYAxsLvrBckNgtvPsSttus 0 "NotOnNegativeSideOfNeutral" 1 "OnNegativeSideOfNeutral" 2 "ErrorIndicator" 3 "NotAvailable";
VAL_ 2365401086 Jystck8GrpYAxisNeutralPosStatus 0 "NotInNeutralPos" 1 "InNeutralPos" 2 "ErrorIndicator" 3 "NotAvailable";
VAL_ 2365401086 Jystck8GrpXAxsLvrRghtPstvPsStts 0 "NotOnPositiveSideOfNeutral" 1 "OnPositiveSideOfNeutral" 2 "ErrorIndicator" 3 "NotAvailable";
VAL_ 2365401086 Jystck8GrpXAxsLvrLftNgtvPsSttus 0 "NotOnNegativeSideOfNeutral" 1 "OnNegativeSideOfNeutral" 2 "ErrorIndicator" 3 "NotAvailable";
VAL_ 2365401086 Jystck8GrpXAxisNeutralPosStatus 0 "NotInNeutralPos" 1 "InNeutralPos" 2 "ErrorIndicator" 3 "NotAvailable";
VAL_ 2365401598 Jystck7GripXAxisDetentPosStatus 0 "NotInDetentPos" 1 "InDetentPos" 2 "ErrorIndicator" 3 "NotAvailable";
VAL_ 2365401598 Jystck7GripYAxisDetentPosStatus 0 "NotInDetentPos" 1 "InDetentPos" 2 "ErrorIndicator" 3 "NotAvailable";
VAL_ 2365401598 Jystck7ThetaAxisDetentPosStatus 0 "NotInDetentPos" 1 "InDetentPos" 2 "ErrorIndicator" 3 "NotAvailable";
VAL_ 2365401598 Jystck7ThtAxsClckwsPstvPsStatus 0 "NotOnPositiveSideOfNeutral" 1 "OnPositiveSideOfNeutral" 2 "ErrorIndicator" 3 "NotAvailable";
VAL_ 2365401598 Jystck7ThtAxsCntrClckwsNgtvPsStt 0 "NotOnNegativeSideOfNeutral" 1 "OnNegativeSideOfNeutral" 2 "ErrorIndicator" 3 "NotAvailable";
VAL_ 2365401598 Jystck7ThtaAxisNeutralPosStatus 0 "NotInNeutralPos" 1 "InNeutralPos" 2 "ErrorIndicator" 3 "NotAvailable";
VAL_ 2365401598 Jystck7GrpYAxsLvrFrwrdPstvPsStts 0 "NotOnPositiveSideOfNeutral" 1 "OnPositiveSideOfNeutral" 2 "ErrorIndicator" 3 "NotAvailable";
VAL_ 2365401598 Jystck7GrpYAxsLvrBckNgtvPsSttus 0 "NotOnNegativeSideOfNeutral" 1 "OnNegativeSideOfNeutral" 2 "ErrorIndicator" 3 "NotAvailable";
VAL_ 2365401598 Jystck7GrpYAxisNeutralPosStatus 0 "NotInNeutralPos" 1 "InNeutralPos" 2 "ErrorIndicator" 3 "NotAvailable";
VAL_ 2365401598 Jystck7GrpXAxsLvrRghtPstvPsStts 0 "NotOnPositiveSideOfNeutral" 1 "OnPositiveSideOfNeutral" 2 "ErrorIndicator" 3 "NotAvailable";
VAL_ 2365401598 Jystck7GrpXAxsLvrLftNgtvPsSttus 0 "NotOnNegativeSideOfNeutral" 1 "OnNegativeSideOfNeutral" 2 "ErrorIndicator" 3 "NotAvailable";
VAL_ 2365401598 Jystck7GrpXAxisNeutralPosStatus 0 "NotInNeutralPos" 1 "InNeutralPos" 2 "ErrorIndicator" 3 "NotAvailable";
VAL_ 2365402110 Jystck6GripXAxisDetentPosStatus 0 "NotInDetentPos" 1 "InDetentPos" 2 "ErrorIndicator" 3 "NotAvailable";
VAL_ 2365402110 Jystck6GripYAxisDetentPosStatus 0 "NotInDetentPos" 1 "InDetentPos" 2 "ErrorIndicator" 3 "NotAvailable";
VAL_ 2365402110 Jystck6ThetaAxisDetentPosStatus 0 "NotInDetentPos" 1 "InDetentPos" 2 "ErrorIndicator" 3 "NotAvailable";
VAL_ 2365402110 Jystck6ThtAxsClckwsPstvPsStatus 0 "NotOnPositiveSideOfNeutral" 1 "OnPositiveSideOfNeutral" 2 "ErrorIndicator" 3 "NotAvailable";
VAL_ 2365402110 Jystck6ThtAxsCntrClckwsNgtvPsStt 0 "NotOnNegativeSideOfNeutral" 1 "OnNegativeSideOfNeutral" 2 "ErrorIndicator" 3 "NotAvailable";
VAL_ 2365402110 Jystck6ThtaAxisNeutralPosStatus 0 "NotInNeutralPos" 1 "InNeutralPos" 2 "ErrorIndicator" 3 "NotAvailable";
VAL_ 2365402110 Jystck6GrpYAxsLvrFrwrdPstvPsStts 0 "NotOnPositiveSideOfNeutral" 1 "OnPositiveSideOfNeutral" 2 "ErrorIndicator" 3 "NotAvailable";
VAL_ 2365402110 Jystck6GrpYAxsLvrBckNgtvPsSttus 0 "NotOnNegativeSideOfNeutral" 1 "OnNegativeSideOfNeutral" 2 "ErrorIndicator" 3 "NotAvailable";
VAL_ 2365402110 Jystck6GrpYAxisNeutralPosStatus 0 "NotInNeutralPos" 1 "InNeutralPos" 2 "ErrorIndicator" 3 "NotAvailable";
VAL_ 2365402110 Jystck6GrpXAxsLvrRghtPstvPsStts 0 "NotOnPositiveSideOfNeutral" 1 "OnPositiveSideOfNeutral" 2 "ErrorIndicator" 3 "NotAvailable";
VAL_ 2365402110 Jystck6GrpXAxsLvrLftNgtvPsSttus 0 "NotOnNegativeSideOfNeutral" 1 "OnNegativeSideOfNeutral" 2 "ErrorIndicator" 3 "NotAvailable";
VAL_ 2365402110 Jystck6GrpXAxisNeutralPosStatus 0 "NotInNeutralPos" 1 "InNeutralPos" 2 "ErrorIndicator" 3 "NotAvailable";
VAL_ 2365402622 Jystck5GripXAxisDetentPosStatus 0 "NotInDetentPos" 1 "InDetentPos" 2 "ErrorIndicator" 3 "NotAvailable";
VAL_ 2365402622 Jystck5GripYAxisDetentPosStatus 0 "NotInDetentPos" 1 "InDetentPos" 2 "ErrorIndicator" 3 "NotAvailable";
VAL_ 2365402622 Jystck5ThetaAxisDetentPosStatus 0 "NotInDetentPos" 1 "InDetentPos" 2 "ErrorIndicator" 3 "NotAvailable";
VAL_ 2365402622 Jystck5ThtAxsClckwsPstvPsStatus 0 "NotOnPositiveSideOfNeutral" 1 "OnPositiveSideOfNeutral" 2 "ErrorIndicator" 3 "NotAvailable";
VAL_ 2365402622 Jystck5ThtAxsCntrClckwsNgtvPsStt 0 "NotOnNegativeSideOfNeutral" 1 "OnNegativeSideOfNeutral" 2 "ErrorIndicator" 3 "NotAvailable";
VAL_ 2365402622 Jystck5ThtaAxisNeutralPosStatus 0 "NotInNeutralPos" 1 "InNeutralPos" 2 "ErrorIndicator" 3 "NotAvailable";
VAL_ 2365402622 Jystck5GrpYAxsLvrFrwrdPstvPsStts 0 "NotOnPositiveSideOfNeutral" 1 "OnPositiveSideOfNeutral" 2 "ErrorIndicator" 3 "NotAvailable";
VAL_ 2365402622 Jystck5GrpYAxsLvrBckNgtvPsSttus 0 "NotOnNegativeSideOfNeutral" 1 "OnNegativeSideOfNeutral" 2 "ErrorIndicator" 3 "NotAvailable";
VAL_ 2365402622 Jystck5GrpYAxisNeutralPosStatus 0 "NotInNeutralPos" 1 "InNeutralPos" 2 "ErrorIndicator" 3 "NotAvailable";
VAL_ 2365402622 Jystck5GrpXAxsLvrRghtPstvPsStts 0 "NotOnPositiveSideOfNeutral" 1 "OnPositiveSideOfNeutral" 2 "ErrorIndicator" 3 "NotAvailable";
VAL_ 2365402622 Jystck5GrpXAxsLvrLftNgtvPsSttus 0 "NotOnNegativeSideOfNeutral" 1 "OnNegativeSideOfNeutral" 2 "ErrorIndicator" 3 "NotAvailable";
VAL_ 2365402622 Jystck5GrpXAxisNeutralPosStatus 0 "NotInNeutralPos" 1 "InNeutralPos" 2 "ErrorIndicator" 3 "NotAvailable";
VAL_ 2365403134 Jystck4GripXAxisDetentPosStatus 0 "NotInDetentPos" 1 "InDetentPos" 2 "ErrorIndicator" 3 "NotAvailable";
VAL_ 2365403134 Jystck4GripYAxisDetentPosStatus 0 "NotInDetentPos" 1 "InDetentPos" 2 "ErrorIndicator" 3 "NotAvailable";
VAL_ 2365403134 Jystck4ThetaAxisDetentPosStatus 0 "NotInDetentPos" 1 "InDetentPos" 2 "ErrorIndicator" 3 "NotAvailable";
VAL_ 2365403134 Jystck4ThtAxsClckwsPstvPsStatus 0 "NotOnPositiveSideOfNeutral" 1 "OnPositiveSideOfNeutral" 2 "ErrorIndicator" 3 "NotAvailable";
VAL_ 2365403134 Jystck4ThtAxsCntrClckwsNgtvPsStt 0 "NotOnNegativeSideOfNeutral" 1 "OnNegativeSideOfNeutral" 2 "ErrorIndicator" 3 "NotAvailable";
VAL_ 2365403134 Jystck4ThtaAxisNeutralPosStatus 0 "NotInNeutralPos" 1 "InNeutralPos" 2 "ErrorIndicator" 3 "NotAvailable";
VAL_ 2365403134 Jystck4GrpYAxsLvrFrwrdPstvPsStts 0 "NotOnPositiveSideOfNeutral" 1 "OnPositiveSideOfNeutral" 2 "ErrorIndicator" 3 "NotAvailable";
VAL_ 2365403134 Jystck4GrpYAxsLvrBckNgtvPsSttus 0 "NotOnNegativeSideOfNeutral" 1 "OnNegativeSideOfNeutral" 2 "ErrorIndicator" 3 "NotAvailable";
VAL_ 2365403134 Jystck4GrpYAxisNeutralPosStatus 0 "NotInNeutralPos" 1 "InNeutralPos" 2 "ErrorIndicator" 3 "NotAvailable";
VAL_ 2365403134 Jystck4GrpXAxsLvrRghtPstvPsStts 0 "NotOnPositiveSideOfNeutral" 1 "OnPositiveSideOfNeutral" 2 "ErrorIndicator" 3 "NotAvailable";
VAL_ 2365403134 Jystck4GrpXAxsLvrLftNgtvPsSttus 0 "NotOnNegativeSideOfNeutral" 1 "OnNegativeSideOfNeutral" 2 "ErrorIndicator" 3 "NotAvailable";
VAL_ 2365403134 Jystck4GrpXAxisNeutralPosStatus 0 "NotInNeutralPos" 1 "InNeutralPos" 2 "ErrorIndicator" 3 "NotAvailable";
VAL_ 2365400062 Jystck10GrpXAxisDetentPosStatus 0 "NotInDetentPos" 1 "InDetentPos" 2 "ErrorIndicator" 3 "NotAvailable";
VAL_ 2365400062 Jystck10GrpYAxisDetentPosStatus 0 "NotInDetentPos" 1 "InDetentPos" 2 "ErrorIndicator" 3 "NotAvailable";
VAL_ 2365400062 Jystck10ThtaAxisDetentPosStatus 0 "NotInDetentPos" 1 "InDetentPos" 2 "ErrorIndicator" 3 "NotAvailable";
VAL_ 2365400062 Jystck10ThtAxsClckwsPstvPsSttus 0 "NotOnPositiveSideOfNeutral" 1 "OnPositiveSideOfNeutral" 2 "ErrorIndicator" 3 "NotAvailable";
VAL_ 2365400062 Jystck10ThtAxsCntrClckwsNgtvPsSt 0 "NotOnNegativeSideOfNeutral" 1 "OnNegativeSideOfNeutral" 2 "ErrorIndicator" 3 "NotAvailable";
VAL_ 2365400062 Jystck10ThtAxisNeutralPosStatus 0 "NotInNeutralPos" 1 "InNeutralPos" 2 "ErrorIndicator" 3 "NotAvailable";
VAL_ 2365400062 Jystck10GrpYAxsLvrFrwrdPstvPsStt 0 "NotOnPositiveSideOfNeutral" 1 "OnPositiveSideOfNeutral" 2 "ErrorIndicator" 3 "NotAvailable";
VAL_ 2365400062 Jystck10GrpYAxsLvrBckNgtvPsStts 0 "NotOnNegativeSideOfNeutral" 1 "OnNegativeSideOfNeutral" 2 "ErrorIndicator" 3 "NotAvailable";
VAL_ 2365400062 Jystck10GrpYAxsNeutralPosStatus 0 "NotInNeutralPos" 1 "InNeutralPos" 2 "ErrorIndicator" 3 "NotAvailable";
VAL_ 2365400062 Jystck10GrpXAxsLvrRghtPstvPsStts 0 "NotOnPositiveSideOfNeutral" 1 "OnPositiveSideOfNeutral" 2 "ErrorIndicator" 3 "NotAvailable";
VAL_ 2365400062 Jystck10GrpXAxsLvrLftNgtvPsStts 0 "NotOnNegativeSideOfNeutral" 1 "OnNegativeSideOfNeutral" 2 "ErrorIndicator" 3 "NotAvailable";
VAL_ 2365400062 Jystck10GrpXAxsNeutralPosStatus 0 "NotInNeutralPos" 1 "InNeutralPos" 2 "ErrorIndicator" 3 "NotAvailable";
VAL_ 2566749438 DslPrtcltFltrActvRgnrtnFrcdStts 0 "NotActive" 1 "ActiveForcedBySwitch" 2 "ActiveForcedByServiceTool" 6 "ReservedForSAEAssignment" 7 "notAvailable";
VAL_ 2566749438 ExhaustSystemHighTempLampCmd 0 "Off" 1 "OnSolid" 6 "reservedForSAEAssignment" 7 "notAvailable";
VAL_ 2566749438 DslPrtcltFltrAtmtcActvRgnrtnIntt 0 "notEnabled" 1 "enabled" 2 "reservedForSAEAssignment" 3 "notAvailable";
VAL_ 2566749438 DslPrtcltFltrActvRgnrtnInhbtdDTV0 0 "notInhibited" 1 "inhibited" 2 "reservedForSAEAssignment" 3 "notAvailable";
VAL_ 2566749438 DslPrtcltFltrActvRgnrtnInhbtdDTE 0 "notInhibited" 1 "inhibited" 2 "reservedForSAEAssignment" 3 "notAvailable";
VAL_ 2566749438 DslPrtcltFltrActvRgnrtnInhbtdDTP0 0 "notInhibited" 1 "inhibited" 2 "reservedForSAEAssignment" 3 "notAvailable";
VAL_ 2566749438 DslPrtcltFltrActvRgnrtnInhbtdDTT 0 "notInhibited" 1 "inhibited" 2 "reservedForSAEAssignment" 3 "notAvailable";
VAL_ 2566749438 DslPrtcltFltrActvRgnrtnInhbtdDTS0 0 "notInhibited" 1 "inhibited" 2 "reservedForSAEAssignment" 3 "notAvailable";
VAL_ 2566749438 DslPrtcltFltrActvRgnrtnInhbtdDTS1 0 "notInhibited" 1 "inhibited" 2 "reservedForSAEAssignment" 3 "notAvailable";
VAL_ 2566749438 DslPrtcltFltrActvRgnrtnInhbtdDTL 0 "notInhibited" 1 "inhibited" 2 "reservedForSAEAssignment" 3 "notAvailable";
VAL_ 2566749438 DslPrtcltFltrActvRgnrtnInhbtdDTP1 0 "notInhibited" 1 "inhibited" 2 "reservedForSAEAssignment" 3 "notAvailable";
VAL_ 2566749438 DslPrtcltFltrActvRgnrtnInhbtdDTV1 0 "notInhibited" 1 "inhibited" 2 "reservedForSAEAssignment" 3 "notAvailable";
VAL_ 2566749438 DslPrtcltFltrActvRgnrtnInhbtdDTO 0 "notInhibited" 1 "inhibited" 2 "reservedForSAEAssignment" 3 "notAvailable";
VAL_ 2566749438 DslPrtcltFltrActvRgnrtnInhbtdDTA 0 "notInhibited" 1 "inhibited" 2 "reservedForSAEAssignment" 3 "notAvailable";
VAL_ 2566749438 DslPrtcltFltrActvRgnrtnInhbtdDTP2 0 "notInhibited" 1 "inhibited" 2 "reservedForSAEAssignment" 3 "notAvailable";
VAL_ 2566749438 DslPrtcltFltrActvRgnrtnInhbtdDTS2 0 "notInhibited" 1 "inhibited" 2 "reservedForSAEAssignment" 3 "notAvailable";
VAL_ 2566749438 DslPrtcltFltrActvRgnrtnInhbtdDTC 0 "notInhibited" 1 "inhibited" 2 "reservedForSAEAssignment" 3 "notAvailable";
VAL_ 2566749438 DslPrtcltFltrActvRgnrtnInhbtdDTI 0 "notInhibited" 1 "inhibited" 2 "reservedForSAEAssignment" 3 "notAvailable";
VAL_ 2566749438 DslPrtcltFltrActvRgnrtnInhbtdStt 0 "notInhibited" 1 "inhibited" 2 "reservedForSAEAssignment" 3 "notAvailable";
VAL_ 2566749438 DieselParticulateFilterStatus 0 "RegenerationNotNeeded" 1 "RegenerationNeededLowestLevel" 2 "RegenerationNeededModerateLevel" 3 "RegenerationNeededHighestLevel" 6 "reservedForSAEAssignment" 7 "notAvailable";
VAL_ 2566749438 DslPrtcltFltrActvRgnrtionStatus 0 "notActive" 1 "active" 2 "rgnrtnNddAtmtcllyInttdActvRgnrt" 3 "notAvailable";
VAL_ 2566749438 DslPrtcltFltrPssvRgnrtionStatus 0 "notActive" 1 "active" 2 "reservedForSAEAssignment" 3 "notAvailable";
VAL_ 2566749438 DieselParticulateFilterLampCmd 0 "Off" 1 "OnSolid" 4 "OnFastBlink" 6 "reservedForSAEAssignment" 7 "notAvailable";
VAL_ 2561212158 TextDisplayInstructions 0 "ClrDsplyDsplydInfrmtnShldBDltdN" 1 "HldDsplyPrsntlyDsplydInfrmtnShl" 2 "AppndAtEndOfDsplyTrnsmttdInfrmt" 3 "OvrwrtDsplyPrsntlyDsplydInfrmtn" 4 "OvrwrtSbstrngAPrtnOfPrsntlyDspl" 5 "HighlightSubstring" 6 "BlinkSubstring" 7 "1110Reserved" 15 "NotApplicable";
VAL_ 2566746366 RetractStatusOfRamp5 0 "rampRetracted" 1 "rampEx" 2 "error" 3 "notAvailable";
VAL_ 2566746366 RetractStatusOfRamp4 0 "rampRetracted" 1 "rampEx" 2 "error" 3 "notAvailable";
VAL_ 2566746366 MovementStatusOfRamp5 0 "rampNotBeingMoved" 1 "rampBeingMoved" 2 "error" 3 "notAvailable";
VAL_ 2566746366 MovementStatusOfRamp4 0 "rampNotBeingMoved" 1 "rampBeingMoved" 2 "error" 3 "notAvailable";
VAL_ 2566746366 EnableStatusOfRamp5 0 "rampDisabled" 1 "rampEnabled" 2 "error" 3 "notAvailable";
VAL_ 2566746366 EnableStatusOfRamp4 0 "rampDisabled" 1 "rampEnabled" 2 "error" 3 "notAvailable";
VAL_ 2566746366 MovementStatusOfRamp3 0 "rampNotBeingMoved" 1 "rampBeingMoved" 2 "error" 3 "notAvailable";
VAL_ 2566746366 EnableStatusOfRamp3 0 "rampDisabled" 1 "rampEnabled" 2 "error" 3 "notAvailable";
VAL_ 2566746366 RetractStatusOfRamp3 0 "rampRetracted" 1 "rampEx" 2 "error" 3 "notAvailable";
VAL_ 2566746366 MovementStatusOfRamp2 0 "rampNotBeingMoved" 1 "rampBeingMoved" 2 "error" 3 "notAvailable";
VAL_ 2566746366 EnableStatusOfRamp2 0 "rampDisabled" 1 "rampEnabled" 2 "error" 3 "notAvailable";
VAL_ 2566746366 RetractStatusOfRamp2 0 "rampRetracted" 1 "rampEx" 2 "error" 3 "notAvailable";
VAL_ 2566746366 MovementStatusOfRamp1 0 "rampNotBeingMoved" 1 "rampBeingMoved" 2 "error" 3 "notAvailable";
VAL_ 2566746366 EnableStatusOfRamp1 0 "rampDisabled" 1 "rampEnabled" 2 "error" 3 "notAvailable";
VAL_ 2566746366 RetractStatusOfRamp1 0 "rampRetracted" 1 "rampEx" 2 "error" 3 "notAvailable";
VAL_ 2566746110 EngExhstGsRcrclation1Valve2Ctrl 4 "MeansMaxValveOpening";
VAL_ 2561277694 LaneDepartureWarningEnableCmd 0 "DisableLaneDepartureWarning" 1 "EnableLaneDepartureWarning" 2 "Reserved" 3 "DonTCare";
VAL_ 2633861886 J2012DTCStatus 0 "DTCIsPreviouslyActive" 1 "DTCIsActive";
VAL_ 2565873150 SteerAngleSensorCalibrated 0 "SASNotCalibrated" 1 "SASCalibrated" 2 "Reserved" 3 "NotAvailable";
VAL_ 2565873150 SteerAngleSensorActiveMode 0 "ProgrammingModeActive" 1 "NormalModeActive" 2 "Reserved" 3 "NotAvailable";
VAL_ 2565873150 SteerWheelAngleRangeCounterType 0 "RelativeNumberOfCounts" 1 "AbsNumberOfCounts" 2 "NotDefined" 3 "SignalNotAvailable";
VAL_ 2566751230 TransferCaseStatus 1 "WheelHigh" 2 "neutral" 4 "WheelLow" 5 "TrnsfrCsShftInPrgrssGrNtCnfrmed" 6 "error" 7 "notAvailable";
VAL_ 2566755838 TransOverheatIndicator 0 "TransOverheatIndicatorIsOff" 1 "TrnsOvrhtIndctrIsOnContinuously" 2 "TrnsOverheatIndicatorIsFlashing" 3 "NotAvailable";
VAL_ 2566755838 TransOilLevelSwitch 0 "Empty" 1 "FullNotEmpty" 2 "Error" 3 "NotAvailable";
VAL_ 2566755838 TransOilFilterRestrictionSwitch 0 "NoRestriction" 1 "RestrictionExistsOnOilFilter" 2 "Error" 3 "NotAvailable";
VAL_ 2566799614 ImplementRearWorkLight 0 "Deactivated" 1 "Activated" 2 "FaultDetected" 3 "NotAvailable";
VAL_ 2566799614 ImplementLeftForwardWorkLight 0 "Deactivated" 1 "Activated" 2 "FaultDetected" 3 "NotAvailable";
VAL_ 2566799614 ImplementRightForwardWorkLight 0 "Deactivated" 1 "Activated" 2 "FaultDetected" 3 "NotAvailable";
VAL_ 2566799614 ImplementLeftFacingWorkLight 0 "Deactivate" 1 "Activate" 2 "FaultDetected" 3 "NotAvailable";
VAL_ 2566799614 ImplementRightFacingWorkLight 0 "Deactivated" 1 "Activated" 2 "FaultDetected" 3 "NotAvailable";
VAL_ 2566799614 ImplementOEMOption1Light 0 "Deactivated" 1 "Activated" 2 "FaultDetected" 3 "NotAvailable";
VAL_ 2566799614 ImplementOEMOption2Light 0 "Deactivated" 1 "Activated" 2 "FaultDetected" 3 "NotAvailable";
VAL_ 2566799614 TrctrFrontHighMountedWorkLights 0 "Deactivated" 1 "Activated" 2 "FaultDetected" 3 "NotAvailable";
VAL_ 2566799614 TrctorFrontLowMountedWorkLights 0 "Deactivated" 1 "Activated" 2 "FaultDetected" 3 "NotAvailable";
VAL_ 2566799614 TrctorSideHighMountedWorkLights 0 "Deactivated" 1 "Activated" 2 "FaultDetected" 3 "NotAvailable";
VAL_ 2566799614 TractorSideLowMountedWorkLights 0 "Deactivated" 1 "Activated" 2 "FaultDetected" 3 "NotAvailable";
VAL_ 2566799614 TrctorRearHighMountedWorkLights 0 "Deactivated" 1 "Activated" 2 "FaultDetected" 3 "NotAvailable";
VAL_ 2566799614 TractorRearLowMountedWorkLights 0 "Deactivated" 1 "Activated" 2 "FaultDetected" 3 "NotAvailable";
VAL_ 2566799614 TrctrUndersideMountedWorkLights 0 "Deactivated" 1 "Activated" 2 "FaultDetected" 3 "NotAvailable";
VAL_ 2566799614 RearFogLights 0 "Deactivated" 1 "Activated" 2 "FaultDetected" 3 "NotAvailable";
VAL_ 2566799614 TractorMarkerLight 0 "Deactivated" 1 "Activated" 2 "FaultDetected" 3 "NotAvailable";
VAL_ 2566799614 ImplementMarkerLight 0 "Deactivated" 1 "Activated" 2 "FaultDetected" 3 "NotAvailable";
VAL_ 2566799614 TractorClearanceLight 0 "Deactivated" 1 "Activated" 2 "FaultDetected" 3 "NotAvailable";
VAL_ 2566799614 ImplementClearanceLight 0 "Deactivated" 1 "Activated" 2 "FaultDetected" 3 "NotAvailable";
VAL_ 2566799614 LeftStopLight 0 "Deactivated" 1 "Activated" 2 "FaultDetected" 3 "NotAvailable";
VAL_ 2566799614 RightStopLight 0 "Deactivated" 1 "Activated" 2 "FaultDetected" 3 "NotAvailable";
VAL_ 2566799614 CenterStopLight 0 "Deactivated" 1 "Activated" 2 "FaultDetected" 3 "NotAvailable";
VAL_ 2566799614 BackUpLightAndAlarmHorn 0 "Deactivated" 1 "Activated" 2 "FaultDetected" 3 "NotAvailable";
VAL_ 2566799614 LeftTurnSignalLights 0 "Deactivated" 1 "Activated" 2 "FaultDetected" 3 "NotAvailable";
VAL_ 2566799614 RightTurnSignalLights 0 "Deactivated" 1 "Activated" 2 "FaultDetected" 3 "NotAvailable";
VAL_ 2566799614 RotatingBeaconLight 0 "Deactivated" 1 "Activated" 2 "FaultDetected" 3 "NotAvailable";
VAL_ 2566799614 TractorFrontFogLights 0 "Deactivated" 1 "Activated" 2 "FaultDetected" 3 "NotAvailable";
VAL_ 2566799614 HighBeamHeadLightData 0 "Deactivated" 1 "Activated" 2 "FaultDetected" 3 "NotAvailable";
VAL_ 2566799614 LowBeamHeadLightData 0 "Deactivated" 1 "Activated" 2 "FaultDetected" 3 "NotAvailable";
VAL_ 2566799614 AltBeamHeadLightData 0 "Deactivated" 1 "Activated" 2 "FaultDetected" 3 "NotAvailable";
VAL_ 2566799614 RunningLight 0 "Deactivated" 1 "Activated" 2 "FaultDetected" 3 "NotAvailable";
VAL_ 2365473278 ImplementRearWorkLightCmd 0 "Deactivate" 1 "Activate" 2 "Reserved" 3 "DonTCare";
VAL_ 2365473278 ImplmentLeftForwardWorkLightCmd 0 "Deactivate" 1 "Activate" 2 "Reserved" 3 "DonTCare";
VAL_ 2365473278 ImplmntRightForwardWorkLightCmd 0 "Deactivate" 1 "Activate" 2 "Reserved" 3 "DonTCare";
VAL_ 2365473278 LightingDataRqCmd 0 "Deactivate" 1 "Activate" 2 "Reserved" 3 "DonTCare";
VAL_ 2365473278 ImplementLeftFacingWorkLightCmd 0 "Deactivate" 1 "Activate" 2 "Reserved" 3 "DonTCare";
VAL_ 2365473278 ImplmentRightFacingWorkLightCmd 0 "Deactivate" 1 "Activate" 2 "Reserved" 3 "DonTCare";
VAL_ 2365473278 ImplementOEMOption1LightCmd 0 "Deactivate" 1 "Activate" 2 "Reserved" 3 "DonTCare";
VAL_ 2365473278 ImplementOEMOption2LightCmd 0 "Deactivate" 1 "Activate" 2 "Reserved" 3 "DonTCare";
VAL_ 2365473278 TrctrFrntHghMuntedWorkLightsCmd 0 "Deactivate" 1 "Activate" 2 "Reserved" 3 "DonTCare";
VAL_ 2365473278 TrctrFrntLwMountedWorkLightsCmd 0 "Deactivate" 1 "Activate" 2 "Reserved" 3 "DonTCare";
VAL_ 2365473278 TrctrSdHighMountedWorkLightsCmd 0 "Deactivate" 1 "Activate" 2 "Reserved" 3 "DonTCare";
VAL_ 2365473278 TrctrSdeLowMountedWorkLightsCmd 0 "Deactivate" 1 "Activate" 2 "Reserved" 3 "DonTCare";
VAL_ 2365473278 TrctrRrHighMountedWorkLightsCmd 0 "Deactivate" 1 "Activate" 2 "Reserved" 3 "DonTCare";
VAL_ 2365473278 TrctrRarLowMountedWorkLightsCmd 0 "Deactivate" 1 "Activate" 2 "Reserved" 3 "DonTCare";
VAL_ 2365473278 TrctrUndrsdMountedWorkLightsCmd 0 "Deactivate" 1 "Activate" 2 "Reserved" 3 "DonTCare";
VAL_ 2365473278 RearFogLightCmd 0 "Deactivate" 1 "Activate" 2 "Reserved" 3 "DonTCare";
VAL_ 2365473278 TractorMarkerLightCmd 0 "Deactivate" 1 "Activate" 2 "Reserved" 3 "DonTCare";
VAL_ 2365473278 ImplementMarkerLightCmd 0 "Deactivate" 1 "Activate" 2 "Reserved" 3 "DonTCare";
VAL_ 2365473278 TractorClearanceLightCmd 0 "Deactivate" 1 "Activate" 2 "Reserved" 3 "DonTCare";
VAL_ 2365473278 ImplementClearanceLightCmd 0 "Deactivate" 1 "Activate" 2 "Reserved" 3 "DonTCare";
VAL_ 2365473278 LeftStopLightCmd 0 "Deactivate" 1 "Activate" 2 "Reserved" 3 "DonTCare";
VAL_ 2365473278 RightStopLightCmd 0 "Deactivate" 1 "Activate" 2 "Reserved" 3 "DonTCare";
VAL_ 2365473278 CenterStopLightCmd 0 "Deactivate" 1 "Activate" 2 "Reserved" 3 "DonTCare";
VAL_ 2365473278 BackUpLightAndAlarmHornCmd 0 "Deactivate" 1 "Activate" 2 "Reserved" 3 "DonTCare";
VAL_ 2365473278 LeftTurnSignalLightsCmd 0 "Deactivate" 1 "Activate" 2 "Reserved" 3 "DonTCare";
VAL_ 2365473278 RightTurnSignalLightsCmd 0 "Deactivate" 1 "Activate" 2 "Reserved" 3 "DonTCare";
VAL_ 2365473278 RotatingBeaconLightCmd 0 "Deactivate" 1 "Activate" 2 "Reserved" 3 "DonTCare";
VAL_ 2365473278 TractorFrontFogLightsCmd 0 "Deactivate" 1 "Activate" 2 "Reserved" 3 "DonTCare";
VAL_ 2365473278 HighBeamHeadLightCmd 0 "Deactivate" 1 "Activate" 2 "Reserved" 3 "DonTCare";
VAL_ 2365473278 LowBeamHeadLightCmd 0 "Deactivate" 1 "Activate" 2 "Reserved" 3 "DonTCare";
VAL_ 2365473278 AltBeamHeadLightCmd 0 "Deactivate" 1 "Activate" 2 "Reserved" 3 "DonTCare";
VAL_ 2365473278 RunningLightCmd 0 "Deactivate" 1 "Activate" 2 "Reserved" 3 "DonTCare";
VAL_ 2365485822 BladeCtrlMode 0 "ManualMode" 1 "AutomaticMode" 2 "InactiveAutomaticMode";
VAL_ 2365485822 LandLevelingSystemEnableStatus 0 "Disabled" 1 "Enabled" 2 "Error" 3 "NotAvailable_NotInstalled";
VAL_ 2365485822 BladeCtrlModeRight 0 "Manual" 1 "Auto" 2 "InactiveAuto" 3 "1101Reserved" 14 "Error" 15 "NotAvailable";
VAL_ 2365485822 BladeCtrlModeLeft 0 "Manual" 1 "Auto" 2 "InactiveAuto" 3 "1101Reserved" 14 "Error" 15 "NotAvailable";
VAL_ 2566768894 EngOprtrPrmryIntrmdtSpdSlctStte 0 "CtrlSttIsISCFnctnltyIsNtRqdEngO" 1 "thr1101CtrlSttIsISCSttng1Thru13" 14 "SAEReserved" 15 "NotAvailable";
VAL_ 2566769406 EngOprtrPrmryIntrmdtSpeedSelect 0 "IndctsThtISCFnctnltyIsNtRqdEngO" 1 "thr1101IndctsThtISCSttng1Thr13I" 14 "ErrorCondition" 15 "NotAvailable";
VAL_ 2566811134 CabHeatingZone 0 "CabHeatingZoneOff" 1 "CabHeatingZoneOn" 2 "Reserved" 3 "NotAvailable";
VAL_ 2566811134 EngHeatingZone 0 "EngHeatingZoneOff" 1 "EngHeatingZoneOn" 2 "Reserved" 3 "NotAvailable";
VAL_ 2566811134 CabVentilation 0 "CabNotVentilated" 1 "CabIsVentilated" 2 "Reserved" 3 "NotAvailable";
VAL_ 2566811134 AuxHeaterMode 0 "HeaterNotActive" 1 "OffDTADRPrErpnRgltnsFrTrnsprtOf" 2 "EconomyMode" 3 "NormalMode" 4 "1101NotDefined" 14 "Error" 15 "NotAvailable";
VAL_ 2566811134 AuxHeaterWaterPumpStatus 0 "WaterPumpIsNotRunning" 1 "WaterPumpIsRunning" 2 "Reserved" 3 "NotAvailable";
VAL_ 2565867774 FireApparatusPumpEngagement 0 "PumpNotEngaged" 1 "PumpEngaged" 2 "Error" 3 "NotAvailableNotInstalled";
VAL_ 2565867774 EngHydPressGovernorSwitch 0 "PressModeInactive" 1 "PressModeActive" 2 "ErrorIndicator" 3 "NotAvailable";
VAL_ 2565867774 EngHydPrssGovernorModeIndicator 0 "Disabled" 1 "Enabled" 2 "ErrorIndicator" 3 "NotAvailable";
VAL_ 2365449982 HydBrakeFluidLevelSwitch 0 "FluidLevelIsNotSufficient" 1 "FluidLevelIsSufficient" 2 "ErrorIndicator" 3 "NotAvailable";
VAL_ 2365449982 HydBrakeSystemAudibleWarningCmd 0 "AudibleWarningOff" 1 "AudibleWarningOn" 2 "Reserved" 3 "DontCare";
VAL_ 2365449982 HydBrkePressSupplyStateCircuit2 0 "SupplyIsNotReliable" 1 "SupplyIsReliable" 2 "ErrorIndicator" 3 "NotAvailable";
VAL_ 2365449982 HydBrkePressSupplyStateCircuit1 0 "SupplyIsNotReliable" 1 "SupplyIsReliable" 2 "ErrorIndicator" 3 "NotAvailable";
VAL_ 2365449982 HydBrkPressWarningStateCircuit2 0 "PressLevelSufficient" 1 "PressLevelBelowWarningLevel" 2 "ErrorIndicator" 3 "NotAvailable";
VAL_ 2365449982 HydBrkPressWarningStateCircuit1 0 "PressLevelSufficient" 1 "PressLevelBelowWarningLevel" 2 "ErrorIndicator" 3 "NotAvailable";
